VERSION ""
BS_:
BU_:

BO_ 823 EPBM_alertMatrix1: 8 ETH
 SG_ EPBM_f065_rightEncIntrpt: 0|1@1+ (1,0) [0|0] "" X
 SG_ EPBM_f066_rightIdleOc: 1|1@1+ (1,0) [0|0] "" X
 SG_ EPBM_f067_rightEncIrrational: 2|1@1+ (1,0) [0|0] "" X
 SG_ EPBM_f068_rightEncoderSna: 3|1@1+ (1,0) [0|0] "" X
 SG_ EPBM_f069_rightOc: 4|1@1+ (1,0) [0|0] "" X
 SG_ EPBM_f070_rightUc: 5|1@1+ (1,0) [0|0] "" X
 SG_ EPBM_f071_rightEndStop: 6|1@1+ (1,0) [0|0] "" X
 SG_ EPBM_f072_rightShortApply: 7|1@1+ (1,0) [0|0] "" X
 SG_ EPBM_f073_rightNShort: 8|1@1+ (1,0) [0|0] "" X
 SG_ EPBM_f074_rightPShort: 9|1@1+ (1,0) [0|0] "" X
 SG_ EPBM_f075_rightNOpen: 10|1@1+ (1,0) [0|0] "" X
 SG_ EPBM_f076_rightPOpen: 11|1@1+ (1,0) [0|0] "" X
 SG_ EPBM_f077_rightEnaStuckHigh: 12|1@1+ (1,0) [0|0] "" X
 SG_ EPBM_f078_rightEnaStuckLow: 13|1@1+ (1,0) [0|0] "" X
 SG_ EPBM_f079_rightDriveDuration: 14|1@1+ (1,0) [0|0] "" X
 SG_ EPBM_f080_rightPHalfBridge: 15|1@1+ (1,0) [0|0] "" X
 SG_ EPBM_f081_rightNHalfBridge: 16|1@1+ (1,0) [0|0] "" X
 SG_ EPBM_f082_rightNvOv: 17|1@1+ (1,0) [0|0] "" X
 SG_ EPBM_f083_rightNvUv: 18|1@1+ (1,0) [0|0] "" X
 SG_ EPBM_f084_rightPvOv: 19|1@1+ (1,0) [0|0] "" X
 SG_ EPBM_f085_rightPvUv: 20|1@1+ (1,0) [0|0] "" X
 SG_ EPBM_f086_rightSubstateErr: 21|1@1+ (1,0) [0|0] "" X
 SG_ EPBM_f087_rightOverApply: 22|1@1+ (1,0) [0|0] "" X
 SG_ EPBM_f088_rightUnderApply: 23|1@1+ (1,0) [0|0] "" X
 SG_ EPBM_f089_rightOverRelease: 24|1@1+ (1,0) [0|0] "" X
 SG_ EPBM_f090_rightUnderRelease: 25|1@1+ (1,0) [0|0] "" X
 SG_ EPBM_f091_spuriousEncIntR: 26|1@1+ (1,0) [0|0] "" X
 SG_ EPBM_f092_noCurrentCalR: 27|1@1+ (1,0) [0|0] "" X
 SG_ EPBM_f093_dasMIA: 28|1@1+ (1,0) [0|0] "" X
 SG_ EPBM_f094_unused: 29|1@1+ (1,0) [0|0] "" X
 SG_ EPBM_f095_invalidConfig: 30|1@1+ (1,0) [0|0] "" X
 SG_ EPBM_f096_selfParkAborted: 31|1@1+ (1,0) [0|0] "" X
 SG_ EPBM_f097_parkMia: 32|1@1+ (1,0) [0|0] "" X
 SG_ EPBM_f098_pmMia: 33|1@1+ (1,0) [0|0] "" X
 SG_ EPBM_f099_unused: 34|1@1+ (1,0) [0|0] "" X
 SG_ EPBM_f100_calibrationWarning: 35|1@1+ (1,0) [0|0] "" X
 SG_ EPBM_f101_calibrationFault: 36|1@1+ (1,0) [0|0] "" X
 SG_ EPBM_f102_targetNotReachedL: 37|1@1+ (1,0) [0|0] "" X
 SG_ EPBM_f103_targetNotReachedR: 38|1@1+ (1,0) [0|0] "" X
 SG_ EPBM_f104_epbStillAsleep: 39|1@1+ (1,0) [0|0] "" X
 SG_ EPBM_f105_epbWentToSleep: 40|1@1+ (1,0) [0|0] "" X
 SG_ EPBM_f106_voltageWarning: 41|1@1+ (1,0) [0|0] "" X
 SG_ EPBM_f107_currentWarning: 42|1@1+ (1,0) [0|0] "" X
 SG_ EPBM_f108_unused: 43|1@1+ (1,0) [0|0] "" X
 SG_ EPBM_f109_unused: 44|1@1+ (1,0) [0|0] "" X
 SG_ EPBM_f110_calWarningLeft: 45|1@1+ (1,0) [0|0] "" X
 SG_ EPBM_f111_calWarningRight: 46|1@1+ (1,0) [0|0] "" X
 SG_ EPBM_f112_calFaultLeft: 47|1@1+ (1,0) [0|0] "" X
 SG_ EPBM_f113_calFaultRight: 48|1@1+ (1,0) [0|0] "" X
 SG_ EPBM_f114_unused: 49|1@1+ (1,0) [0|0] "" X
 SG_ EPBM_f115_rightNVoltageLow: 50|1@1+ (1,0) [0|0] "" X
 SG_ EPBM_f116_rightPVoltageHigh: 51|1@1+ (1,0) [0|0] "" X
 SG_ EPBM_f117_usedFallbackValues: 52|1@1+ (1,0) [0|0] "" X
 SG_ EPBM_f118_unused: 53|1@1+ (1,0) [0|0] "" X
 SG_ EPBM_f119_unused: 54|1@1+ (1,0) [0|0] "" X
 SG_ EPBM_f120_unused: 55|1@1+ (1,0) [0|0] "" X
 SG_ EPBM_f121_unused: 56|1@1+ (1,0) [0|0] "" X
 SG_ EPBM_f122_unused: 57|1@1+ (1,0) [0|0] "" X
 SG_ EPBM_f123_unused: 58|1@1+ (1,0) [0|0] "" X
 SG_ EPBM_f124_unused: 59|1@1+ (1,0) [0|0] "" X
 SG_ EPBM_f125_unused: 60|1@1+ (1,0) [0|0] "" X
 SG_ EPBM_f126_unused: 61|1@1+ (1,0) [0|0] "" X
 SG_ EPBM_f127_unused: 62|1@1+ (1,0) [0|0] "" X
 SG_ EPBM_f128_unused: 63|1@1+ (1,0) [0|0] "" X

BO_ 791 EPBM_alertMatrix2: 8 ETH
 SG_ EPBM_w001_leftEncIntrpt: 0|1@1+ (1,0) [0|0] "" X
 SG_ EPBM_w002_leftIdleOc: 1|1@1+ (1,0) [0|0] "" X
 SG_ EPBM_w003_leftEncIrrational: 2|1@1+ (1,0) [0|0] "" X
 SG_ EPBM_w004_leftEncoderSna: 3|1@1+ (1,0) [0|0] "" X
 SG_ EPBM_w005_leftOc: 4|1@1+ (1,0) [0|0] "" X
 SG_ EPBM_w006_leftUc: 5|1@1+ (1,0) [0|0] "" X
 SG_ EPBM_w007_leftEndStop: 6|1@1+ (1,0) [0|0] "" X
 SG_ EPBM_w008_leftShortApply: 7|1@1+ (1,0) [0|0] "" X
 SG_ EPBM_w009_leftNShort: 8|1@1+ (1,0) [0|0] "" X
 SG_ EPBM_w010_leftPShort: 9|1@1+ (1,0) [0|0] "" X
 SG_ EPBM_w011_leftNOpen: 10|1@1+ (1,0) [0|0] "" X
 SG_ EPBM_w012_leftPOpen: 11|1@1+ (1,0) [0|0] "" X
 SG_ EPBM_w013_leftEnaStuckHigh: 12|1@1+ (1,0) [0|0] "" X
 SG_ EPBM_w014_leftEnaStuckLow: 13|1@1+ (1,0) [0|0] "" X
 SG_ EPBM_w015_leftDriveDuration: 14|1@1+ (1,0) [0|0] "" X
 SG_ EPBM_w016_leftPHalfBridge: 15|1@1+ (1,0) [0|0] "" X
 SG_ EPBM_w017_leftNHalfBridge: 16|1@1+ (1,0) [0|0] "" X
 SG_ EPBM_w018_leftNvOv: 17|1@1+ (1,0) [0|0] "" X
 SG_ EPBM_w019_leftNvUv: 18|1@1+ (1,0) [0|0] "" X
 SG_ EPBM_w020_leftPvOv: 19|1@1+ (1,0) [0|0] "" X
 SG_ EPBM_w021_leftPvUv: 20|1@1+ (1,0) [0|0] "" X
 SG_ EPBM_w022_leftSubstateErr: 21|1@1+ (1,0) [0|0] "" X
 SG_ EPBM_w023_leftOverApply: 22|1@1+ (1,0) [0|0] "" X
 SG_ EPBM_w024_leftUnderApply: 23|1@1+ (1,0) [0|0] "" X
 SG_ EPBM_w025_leftOverRelease: 24|1@1+ (1,0) [0|0] "" X
 SG_ EPBM_w026_leftUnderRelease: 25|1@1+ (1,0) [0|0] "" X
 SG_ EPBM_w027_spuriousEncIntL: 26|1@1+ (1,0) [0|0] "" X
 SG_ EPBM_w028_noCurrentCalL: 27|1@1+ (1,0) [0|0] "" X
 SG_ EPBM_w029_canDisabled: 28|1@1+ (1,0) [0|0] "" X
 SG_ EPBM_w030_interProcSpi: 29|1@1+ (1,0) [0|0] "" X
 SG_ EPBM_w031_stateErr: 30|1@1+ (1,0) [0|0] "" X
 SG_ EPBM_w032_reqStateErr: 31|1@1+ (1,0) [0|0] "" X
 SG_ EPBM_w033_canHardware: 32|1@1+ (1,0) [0|0] "" X
 SG_ EPBM_w034_canData: 33|1@1+ (1,0) [0|0] "" X
 SG_ EPBM_w035_canErr: 34|1@1+ (1,0) [0|0] "" X
 SG_ EPBM_w036_canOverrun: 35|1@1+ (1,0) [0|0] "" X
 SG_ EPBM_w037_firmware: 36|1@1+ (1,0) [0|0] "" X
 SG_ EPBM_w038_eeprom: 37|1@1+ (1,0) [0|0] "" X
 SG_ EPBM_w039_watchdogReset: 38|1@1+ (1,0) [0|0] "" X
 SG_ EPBM_w040_memoryError: 39|1@1+ (1,0) [0|0] "" X
 SG_ EPBM_w041_spiOpen: 40|1@1+ (1,0) [0|0] "" X
 SG_ EPBM_w042_spiRead: 41|1@1+ (1,0) [0|0] "" X
 SG_ EPBM_w043_absMIA: 42|1@1+ (1,0) [0|0] "" X
 SG_ EPBM_w044_diMIA: 43|1@1+ (1,0) [0|0] "" X
 SG_ EPBM_w045_gtwMIA: 44|1@1+ (1,0) [0|0] "" X
 SG_ EPBM_w046_sccmMIA: 45|1@1+ (1,0) [0|0] "" X
 SG_ EPBM_w047_epbMIA: 46|1@1+ (1,0) [0|0] "" X
 SG_ EPBM_w048_chgMIA: 47|1@1+ (1,0) [0|0] "" X
 SG_ EPBM_w049_espMIA: 48|1@1+ (1,0) [0|0] "" X
 SG_ EPBM_w050_mcuMIA: 49|1@1+ (1,0) [0|0] "" X
 SG_ EPBM_w051_leftNVoltageLow: 50|1@1+ (1,0) [0|0] "" X
 SG_ EPBM_w052_leftPVoltageHigh: 51|1@1+ (1,0) [0|0] "" X
 SG_ EPBM_w053_unused: 52|1@1+ (1,0) [0|0] "" X
 SG_ EPBM_w054_unused: 53|1@1+ (1,0) [0|0] "" X
 SG_ EPBM_w055_stackOverflow: 54|1@1+ (1,0) [0|0] "" X
 SG_ EPBM_w056_12vOv: 55|1@1+ (1,0) [0|0] "" X
 SG_ EPBM_w057_12vUv: 56|1@1+ (1,0) [0|0] "" X
 SG_ EPBM_w058_5vLost: 57|1@1+ (1,0) [0|0] "" X
 SG_ EPBM_w059_battMismatch: 58|1@1+ (1,0) [0|0] "" X
 SG_ EPBM_w060_maxCycles1: 59|1@1+ (1,0) [0|0] "" X
 SG_ EPBM_w061_maxCycles2: 60|1@1+ (1,0) [0|0] "" X
 SG_ EPBM_w062_diGearInvld: 61|1@1+ (1,0) [0|0] "" X
 SG_ EPBM_w063_unused: 62|1@1+ (1,0) [0|0] "" X
 SG_ EPBM_w064_unused: 63|1@1+ (1,0) [0|0] "" X

BO_ 807 EPBM_alertMatrix3: 8 ETH
 SG_ EPBM_w065_rightEncIntrpt: 0|1@1+ (1,0) [0|0] "" X
 SG_ EPBM_w066_rightIdleOc: 1|1@1+ (1,0) [0|0] "" X
 SG_ EPBM_w067_rightEncIrrational: 2|1@1+ (1,0) [0|0] "" X
 SG_ EPBM_w068_rightEncoderSna: 3|1@1+ (1,0) [0|0] "" X
 SG_ EPBM_w069_rightOc: 4|1@1+ (1,0) [0|0] "" X
 SG_ EPBM_w070_rightUc: 5|1@1+ (1,0) [0|0] "" X
 SG_ EPBM_w071_rightEndStop: 6|1@1+ (1,0) [0|0] "" X
 SG_ EPBM_w072_rightShortApply: 7|1@1+ (1,0) [0|0] "" X
 SG_ EPBM_w073_rightNShort: 8|1@1+ (1,0) [0|0] "" X
 SG_ EPBM_w074_rightPShort: 9|1@1+ (1,0) [0|0] "" X
 SG_ EPBM_w075_rightNOpen: 10|1@1+ (1,0) [0|0] "" X
 SG_ EPBM_w076_rightPOpen: 11|1@1+ (1,0) [0|0] "" X
 SG_ EPBM_w077_rightEnaStuckHigh: 12|1@1+ (1,0) [0|0] "" X
 SG_ EPBM_w078_rightEnaStuckLow: 13|1@1+ (1,0) [0|0] "" X
 SG_ EPBM_w079_rightDriveDuration: 14|1@1+ (1,0) [0|0] "" X
 SG_ EPBM_w080_rightPHalfBridge: 15|1@1+ (1,0) [0|0] "" X
 SG_ EPBM_w081_rightNHalfBridge: 16|1@1+ (1,0) [0|0] "" X
 SG_ EPBM_w082_rightNvOv: 17|1@1+ (1,0) [0|0] "" X
 SG_ EPBM_w083_rightNvUv: 18|1@1+ (1,0) [0|0] "" X
 SG_ EPBM_w084_rightPvOv: 19|1@1+ (1,0) [0|0] "" X
 SG_ EPBM_w085_rightPvUv: 20|1@1+ (1,0) [0|0] "" X
 SG_ EPBM_w086_rightSubstateErr: 21|1@1+ (1,0) [0|0] "" X
 SG_ EPBM_w087_rightOverApply: 22|1@1+ (1,0) [0|0] "" X
 SG_ EPBM_w088_rightUnderApply: 23|1@1+ (1,0) [0|0] "" X
 SG_ EPBM_w089_rightOverRelease: 24|1@1+ (1,0) [0|0] "" X
 SG_ EPBM_w090_rightUnderRelease: 25|1@1+ (1,0) [0|0] "" X
 SG_ EPBM_w091_spuriousEncIntR: 26|1@1+ (1,0) [0|0] "" X
 SG_ EPBM_w092_noCurrentCalR: 27|1@1+ (1,0) [0|0] "" X
 SG_ EPBM_w093_dasMIA: 28|1@1+ (1,0) [0|0] "" X
 SG_ EPBM_w094_unused: 29|1@1+ (1,0) [0|0] "" X
 SG_ EPBM_w095_invalidConfig: 30|1@1+ (1,0) [0|0] "" X
 SG_ EPBM_w096_selfParkAborted: 31|1@1+ (1,0) [0|0] "" X
 SG_ EPBM_w097_parkMia: 32|1@1+ (1,0) [0|0] "" X
 SG_ EPBM_w098_pmMia: 33|1@1+ (1,0) [0|0] "" X
 SG_ EPBM_w099_unused: 34|1@1+ (1,0) [0|0] "" X
 SG_ EPBM_w100_calibrationWarning: 35|1@1+ (1,0) [0|0] "" X
 SG_ EPBM_w101_calibrationFault: 36|1@1+ (1,0) [0|0] "" X
 SG_ EPBM_w102_targetNotReachedL: 37|1@1+ (1,0) [0|0] "" X
 SG_ EPBM_w103_targetNotReachedR: 38|1@1+ (1,0) [0|0] "" X
 SG_ EPBM_w104_epbStillAsleep: 39|1@1+ (1,0) [0|0] "" X
 SG_ EPBM_w105_epbWentToSleep: 40|1@1+ (1,0) [0|0] "" X
 SG_ EPBM_w106_voltageWarning: 41|1@1+ (1,0) [0|0] "" X
 SG_ EPBM_w107_currentWarning: 42|1@1+ (1,0) [0|0] "" X
 SG_ EPBM_w108_unused: 43|1@1+ (1,0) [0|0] "" X
 SG_ EPBM_w109_unused: 44|1@1+ (1,0) [0|0] "" X
 SG_ EPBM_w110_calWarningLeft: 45|1@1+ (1,0) [0|0] "" X
 SG_ EPBM_w111_calWarningRight: 46|1@1+ (1,0) [0|0] "" X
 SG_ EPBM_w112_calFaultLeft: 47|1@1+ (1,0) [0|0] "" X
 SG_ EPBM_w113_calFaultRight: 48|1@1+ (1,0) [0|0] "" X
 SG_ EPBM_w114_unused: 49|1@1+ (1,0) [0|0] "" X
 SG_ EPBM_w115_rightNVoltageLow: 50|1@1+ (1,0) [0|0] "" X
 SG_ EPBM_w116_rightPVoltageHigh: 51|1@1+ (1,0) [0|0] "" X
 SG_ EPBM_w117_usedFallbackValues: 52|1@1+ (1,0) [0|0] "" X
 SG_ EPBM_w118_unused: 53|1@1+ (1,0) [0|0] "" X
 SG_ EPBM_w119_unused: 54|1@1+ (1,0) [0|0] "" X
 SG_ EPBM_w120_unused: 55|1@1+ (1,0) [0|0] "" X
 SG_ EPBM_w121_unused: 56|1@1+ (1,0) [0|0] "" X
 SG_ EPBM_w122_unused: 57|1@1+ (1,0) [0|0] "" X
 SG_ EPBM_w123_unused: 58|1@1+ (1,0) [0|0] "" X
 SG_ EPBM_w124_unused: 59|1@1+ (1,0) [0|0] "" X
 SG_ EPBM_w125_unused: 60|1@1+ (1,0) [0|0] "" X
 SG_ EPBM_w126_unused: 61|1@1+ (1,0) [0|0] "" X
 SG_ EPBM_w127_unused: 62|1@1+ (1,0) [0|0] "" X
 SG_ EPBM_w128_unused: 63|1@1+ (1,0) [0|0] "" X

BO_ 1351 EPBM_info: 8 ETH
 SG_ EPBM_infoIndex M: 0|8@1+ (1,0) [0|0] "" X
 SG_ EPBM_infoBuildType m10: 8|8@1+ (1,0) [0|0] "" X
 SG_ EPBM_infoBuildConfigID m10: 16|16@1+ (1,0) [0|0] "" X
 SG_ EPBM_infoHardwareID m10: 32|16@1+ (1,0) [0|0] "" X
 SG_ EPBM_infoComponentID m10: 48|16@1+ (1,0) [0|0] "" X
 SG_ EPBM_infoPcbaID m11: 16|8@1+ (1,0) [0|0] "" X
 SG_ EPBM_infoAssemblyID m11: 24|8@1+ (1,0) [0|0] "" X
 SG_ EPBM_infoUsageID m11: 32|16@1+ (1,0) [0|0] "" X
 SG_ EPBM_infoSubUsageID m11: 48|16@1+ (1,0) [0|0] "" X
 SG_ EPBM_infoApplicationCRC m13: 32|32@1+ (1,0) [0|0] "" X
 SG_ EPBM_infoBootloaderSvnRevision m14: 8|24@1+ (1,0) [0|0] "" X
 SG_ EPBM_infoAppGitHashBytes m17: 10|54@1+ (4,0) [0|0] "" X
 SG_ EPBM_infoBootGitHashBytes m18: 10|54@1+ (4,0) [0|0] "" X
 SG_ EPBM_infoPlatformType m19: 8|8@1+ (1,0) [0|0] "" X
 SG_ EPBM_infoMajorVersion m19: 16|8@1+ (1,0) [0|0] "" X
 SG_ EPBM_infoBranchOrigin m19: 24|8@1+ (1,0) [0|0] "" X
 SG_ EPBM_infoMaturity m19: 32|8@1+ (1,0) [0|0] "" X
 SG_ EPBM_infoHardwareRevision m19: 40|8@1+ (1,0) [0|0] "" X
 SG_ EPBM_infoBootUdsProtoVersion m20: 8|8@1+ (1,0) [0|0] "" X
 SG_ EPBM_infoBootloaderCRC m20: 32|32@1+ (1,0) [0|0] "" X

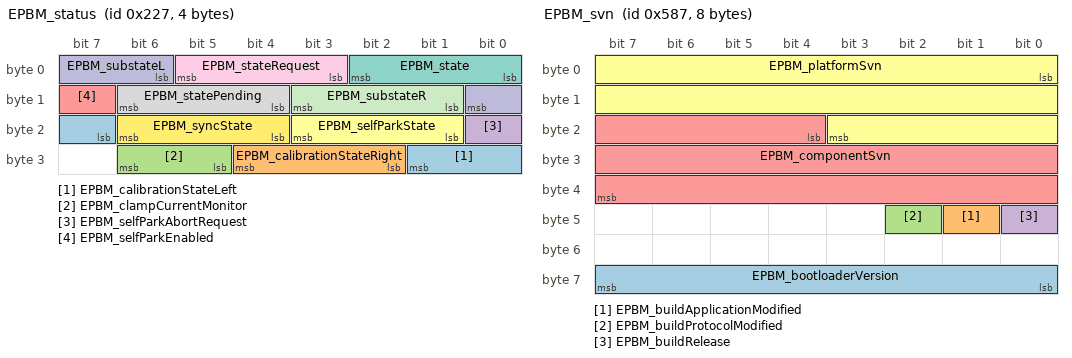
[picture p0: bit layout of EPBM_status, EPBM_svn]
BO_ 551 EPBM_status: 4 ETH
 SG_ EPBM_calibrationStateLeft: 23|3@1+ (1,0) [0|0] "" X
 SG_ EPBM_calibrationStateRight: 26|3@1+ (1,0) [0|0] "" X
 SG_ EPBM_clampCurrentMonitor: 29|2@1+ (1,0) [0|0] "" X
 SG_ EPBM_selfParkAbortRequest: 16|1@1+ (1,0) [0|0] "" X
 SG_ EPBM_selfParkEnabled: 15|1@1+ (1,0) [0|0] "" X
 SG_ EPBM_selfParkState: 17|3@1+ (1,0) [0|0] "" X
 SG_ EPBM_state: 0|3@1+ (1,0) [0|0] "" X
 SG_ EPBM_statePending: 12|3@1+ (1,0) [0|0] "" X
 SG_ EPBM_stateRequest: 3|3@1+ (1,0) [0|0] "" X
 SG_ EPBM_substateL: 6|3@1+ (1,0) [0|0] "" X
 SG_ EPBM_substateR: 9|3@1+ (1,0) [0|0] "" X
 SG_ EPBM_syncState: 20|3@1+ (1,0) [0|0] "" X

BO_ 1415 EPBM_svn: 8 ETH
 SG_ EPBM_bootloaderVersion: 56|8@1+ (1,0) [0|0] "" X
 SG_ EPBM_buildApplicationModified: 41|1@1+ (1,0) [0|0] "" X
 SG_ EPBM_buildProtocolModified: 42|1@1+ (1,0) [0|0] "" X
 SG_ EPBM_buildRelease: 40|1@1+ (1,0) [0|0] "" X
 SG_ EPBM_componentSvn: 20|20@1+ (1,0) [0|0] "" X
 SG_ EPBM_platformSvn: 0|20@1+ (1,0) [0|0] "" X

BO_ 1623 EPBM_udsResponse: 8 ETH
 SG_ EPBM_udsResponseData_H: 0|32@0+ (1,0) [0|0] "" X
 SG_ EPBM_udsResponseData_L: 32|32@0+ (1,0) [0|0] "" X

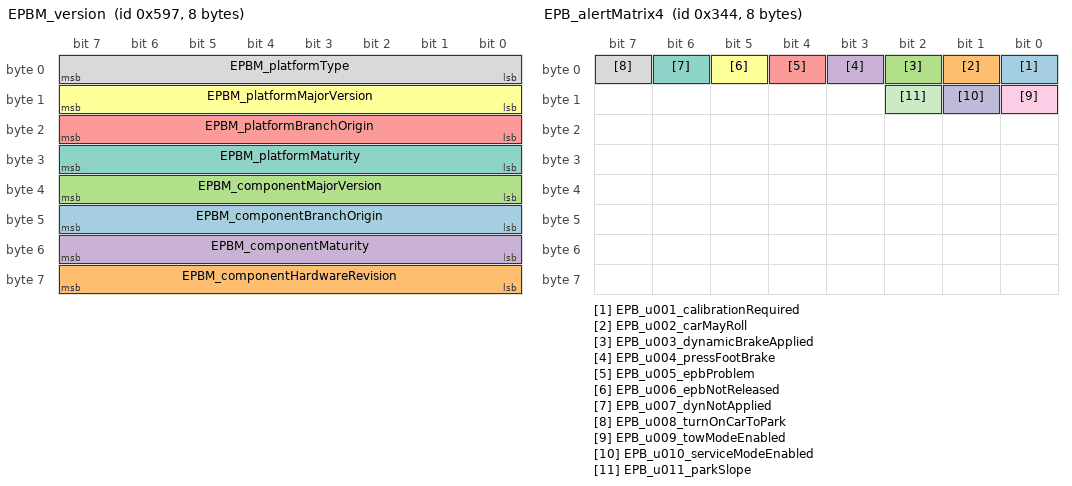
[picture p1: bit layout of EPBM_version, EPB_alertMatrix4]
BO_ 1431 EPBM_version: 8 ETH
 SG_ EPBM_componentBranchOrigin: 40|8@1+ (1,0) [0|0] "" X
 SG_ EPBM_componentHardwareRevision: 56|8@1+ (1,0) [0|0] "" X
 SG_ EPBM_componentMajorVersion: 32|8@1+ (1,0) [0|0] "" X
 SG_ EPBM_componentMaturity: 48|8@1+ (1,0) [0|0] "" X
 SG_ EPBM_platformBranchOrigin: 16|8@1+ (1,0) [0|0] "" X
 SG_ EPBM_platformMajorVersion: 8|8@1+ (1,0) [0|0] "" X
 SG_ EPBM_platformMaturity: 24|8@1+ (1,0) [0|0] "" X
 SG_ EPBM_platformType: 0|8@1+ (1,0) [0|0] "" X

BO_ 772 EPB_alertMatrix0: 8 ETH
 SG_ EPB_f001_leftEncIntrpt: 0|1@1+ (1,0) [0|0] "" X
 SG_ EPB_f002_leftIdleOc: 1|1@1+ (1,0) [0|0] "" X
 SG_ EPB_f003_leftEncIrrational: 2|1@1+ (1,0) [0|0] "" X
 SG_ EPB_f004_leftEncoderSna: 3|1@1+ (1,0) [0|0] "" X
 SG_ EPB_f005_leftOc: 4|1@1+ (1,0) [0|0] "" X
 SG_ EPB_f006_leftUc: 5|1@1+ (1,0) [0|0] "" X
 SG_ EPB_f007_leftEndStop: 6|1@1+ (1,0) [0|0] "" X
 SG_ EPB_f008_leftShortApply: 7|1@1+ (1,0) [0|0] "" X
 SG_ EPB_f009_leftNShort: 8|1@1+ (1,0) [0|0] "" X
 SG_ EPB_f010_leftPShort: 9|1@1+ (1,0) [0|0] "" X
 SG_ EPB_f011_leftNOpen: 10|1@1+ (1,0) [0|0] "" X
 SG_ EPB_f012_leftPOpen: 11|1@1+ (1,0) [0|0] "" X
 SG_ EPB_f013_leftEnaStuckHigh: 12|1@1+ (1,0) [0|0] "" X
 SG_ EPB_f014_leftEnaStuckLow: 13|1@1+ (1,0) [0|0] "" X
 SG_ EPB_f015_leftDriveDuration: 14|1@1+ (1,0) [0|0] "" X
 SG_ EPB_f016_leftPHalfBridge: 15|1@1+ (1,0) [0|0] "" X
 SG_ EPB_f017_leftNHalfBridge: 16|1@1+ (1,0) [0|0] "" X
 SG_ EPB_f018_leftNvOv: 17|1@1+ (1,0) [0|0] "" X
 SG_ EPB_f019_leftNvUv: 18|1@1+ (1,0) [0|0] "" X
 SG_ EPB_f020_leftPvOv: 19|1@1+ (1,0) [0|0] "" X
 SG_ EPB_f021_leftPvUv: 20|1@1+ (1,0) [0|0] "" X
 SG_ EPB_f022_leftSubstateErr: 21|1@1+ (1,0) [0|0] "" X
 SG_ EPB_f023_leftFirstShortApply: 22|1@1+ (1,0) [0|0] "" X
 SG_ EPB_f024_motorShortedReleaseL: 23|1@1+ (1,0) [0|0] "" X
 SG_ EPB_f025_motorShortedApplyL: 24|1@1+ (1,0) [0|0] "" X
 SG_ EPB_f026_noCurrentCalL: 25|1@1+ (1,0) [0|0] "" X
 SG_ EPB_f027_spuriousEncIntL: 26|1@1+ (1,0) [0|0] "" X
 SG_ EPB_f028_reqStateErr: 27|1@1+ (1,0) [0|0] "" X
 SG_ EPB_f029_stateErr: 28|1@1+ (1,0) [0|0] "" X
 SG_ EPB_f030_interProcSpi: 29|1@1+ (1,0) [0|0] "" X
 SG_ EPB_f031_chgMIA: 30|1@1+ (1,0) [0|0] "" X
 SG_ EPB_f032_canDisabled: 31|1@1+ (1,0) [0|0] "" X
 SG_ EPB_f033_canHardware: 32|1@1+ (1,0) [0|0] "" X
 SG_ EPB_f034_canData: 33|1@1+ (1,0) [0|0] "" X
 SG_ EPB_f035_canErr: 34|1@1+ (1,0) [0|0] "" X
 SG_ EPB_f036_canOverrun: 35|1@1+ (1,0) [0|0] "" X
 SG_ EPB_f037_firmware: 36|1@1+ (1,0) [0|0] "" X
 SG_ EPB_f038_eeprom: 37|1@1+ (1,0) [0|0] "" X
 SG_ EPB_f039_watchdogReset: 38|1@1+ (1,0) [0|0] "" X
 SG_ EPB_f040_memoryError: 39|1@1+ (1,0) [0|0] "" X
 SG_ EPB_f041_spiOpen: 40|1@1+ (1,0) [0|0] "" X
 SG_ EPB_f042_spiRead: 41|1@1+ (1,0) [0|0] "" X
 SG_ EPB_f043_absMIA: 42|1@1+ (1,0) [0|0] "" X
 SG_ EPB_f044_diMIA: 43|1@1+ (1,0) [0|0] "" X
 SG_ EPB_f045_gtwMIA: 44|1@1+ (1,0) [0|0] "" X
 SG_ EPB_f046_sccmMIA: 45|1@1+ (1,0) [0|0] "" X
 SG_ EPB_f047_epbmMIA: 46|1@1+ (1,0) [0|0] "" X
 SG_ EPB_f048_mcuMIA: 47|1@1+ (1,0) [0|0] "" X
 SG_ EPB_f049_espMIA: 48|1@1+ (1,0) [0|0] "" X
 SG_ EPB_f050_resetRequired: 49|1@1+ (1,0) [0|0] "" X
 SG_ EPB_f051_epbNotApplied: 50|1@1+ (1,0) [0|0] "" X
 SG_ EPB_f052_epbProblem: 51|1@1+ (1,0) [0|0] "" X
 SG_ EPB_f053_epbNotReleased: 52|1@1+ (1,0) [0|0] "" X
 SG_ EPB_f054_severeShortApply: 53|1@1+ (1,0) [0|0] "" X
 SG_ EPB_f055_stackOverflow: 54|1@1+ (1,0) [0|0] "" X
 SG_ EPB_f056_12vOv: 55|1@1+ (1,0) [0|0] "" X
 SG_ EPB_f057_12vUv: 56|1@1+ (1,0) [0|0] "" X
 SG_ EPB_f058_5vLost: 57|1@1+ (1,0) [0|0] "" X
 SG_ EPB_f059_battMismatch: 58|1@1+ (1,0) [0|0] "" X
 SG_ EPB_f060_maxCycles1: 59|1@1+ (1,0) [0|0] "" X
 SG_ EPB_f061_maxCycles2: 60|1@1+ (1,0) [0|0] "" X
 SG_ EPB_f062_diGearInvld: 61|1@1+ (1,0) [0|0] "" X
 SG_ EPB_f063_parkWhlSpeed: 62|1@1+ (1,0) [0|0] "" X
 SG_ EPB_f064_EPBMTimeout: 63|1@1+ (1,0) [0|0] "" X

BO_ 820 EPB_alertMatrix1: 8 ETH
 SG_ EPB_f065_rightEncIntrpt: 0|1@1+ (1,0) [0|0] "" X
 SG_ EPB_f066_rightIdleOc: 1|1@1+ (1,0) [0|0] "" X
 SG_ EPB_f067_rightEncIrrational: 2|1@1+ (1,0) [0|0] "" X
 SG_ EPB_f068_rightEncoderSna: 3|1@1+ (1,0) [0|0] "" X
 SG_ EPB_f069_rightOc: 4|1@1+ (1,0) [0|0] "" X
 SG_ EPB_f070_rightUc: 5|1@1+ (1,0) [0|0] "" X
 SG_ EPB_f071_rightEndStop: 6|1@1+ (1,0) [0|0] "" X
 SG_ EPB_f072_rightShortApply: 7|1@1+ (1,0) [0|0] "" X
 SG_ EPB_f073_rightNShort: 8|1@1+ (1,0) [0|0] "" X
 SG_ EPB_f074_rightPShort: 9|1@1+ (1,0) [0|0] "" X
 SG_ EPB_f075_rightNOpen: 10|1@1+ (1,0) [0|0] "" X
 SG_ EPB_f076_rightPOpen: 11|1@1+ (1,0) [0|0] "" X
 SG_ EPB_f077_rightEnaStuckHigh: 12|1@1+ (1,0) [0|0] "" X
 SG_ EPB_f078_rightEnaStuckLow: 13|1@1+ (1,0) [0|0] "" X
 SG_ EPB_f079_rightDriveDuration: 14|1@1+ (1,0) [0|0] "" X
 SG_ EPB_f080_rightPHalfBridge: 15|1@1+ (1,0) [0|0] "" X
 SG_ EPB_f081_rightNHalfBridge: 16|1@1+ (1,0) [0|0] "" X
 SG_ EPB_f082_rightNvOv: 17|1@1+ (1,0) [0|0] "" X
 SG_ EPB_f083_rightNvUv: 18|1@1+ (1,0) [0|0] "" X
 SG_ EPB_f084_rightPvOv: 19|1@1+ (1,0) [0|0] "" X
 SG_ EPB_f085_rightPvUv: 20|1@1+ (1,0) [0|0] "" X
 SG_ EPB_f086_rightSubstateErr: 21|1@1+ (1,0) [0|0] "" X
 SG_ EPB_f087_rightFirstShortApply: 22|1@1+ (1,0) [0|0] "" X
 SG_ EPB_f088_motorShortedReleaseR: 23|1@1+ (1,0) [0|0] "" X
 SG_ EPB_f089_motorShortedApplyR: 24|1@1+ (1,0) [0|0] "" X
 SG_ EPB_f090_noCurrentCalR: 25|1@1+ (1,0) [0|0] "" X
 SG_ EPB_f091_spuriousEncIntR: 26|1@1+ (1,0) [0|0] "" X
 SG_ EPB_f092_obsolete: 27|1@1+ (1,0) [0|0] "" X
 SG_ EPB_f093_dasMIA: 28|1@1+ (1,0) [0|0] "" X
 SG_ EPB_f094_inhibitEac: 29|1@1+ (1,0) [0|0] "" X
 SG_ EPB_f095_invalidConfig: 30|1@1+ (1,0) [0|0] "" X
 SG_ EPB_f096_epasMia: 31|1@1+ (1,0) [0|0] "" X
 SG_ EPB_f097_selfParkAborted: 32|1@1+ (1,0) [0|0] "" X
 SG_ EPB_f098_parkMia: 33|1@1+ (1,0) [0|0] "" X
 SG_ EPB_f099_pmMia: 34|1@1+ (1,0) [0|0] "" X
 SG_ EPB_f100_calibrationWarning: 35|1@1+ (1,0) [0|0] "" X
 SG_ EPB_f101_calibrationFault: 36|1@1+ (1,0) [0|0] "" X
 SG_ EPB_f102_eepromCorrupt: 37|1@1+ (1,0) [0|0] "" X
 SG_ EPB_f103_eepromUpdated: 38|1@1+ (1,0) [0|0] "" X
 SG_ EPB_f104_epbmStillAsleep: 39|1@1+ (1,0) [0|0] "" X
 SG_ EPB_f105_epbmWentToSleep: 40|1@1+ (1,0) [0|0] "" X
 SG_ EPB_f106_leftNVoltageLow: 41|1@1+ (1,0) [0|0] "" X
 SG_ EPB_f107_leftPVoltageHigh: 42|1@1+ (1,0) [0|0] "" X
 SG_ EPB_f108_rightNVoltageLow: 43|1@1+ (1,0) [0|0] "" X
 SG_ EPB_f109_rightPVoltageHigh: 44|1@1+ (1,0) [0|0] "" X
 SG_ EPB_f110_calWarningLeft: 45|1@1+ (1,0) [0|0] "" X
 SG_ EPB_f111_calWarningRight: 46|1@1+ (1,0) [0|0] "" X
 SG_ EPB_f112_calFaultLeft: 47|1@1+ (1,0) [0|0] "" X
 SG_ EPB_f113_calFaultRight: 48|1@1+ (1,0) [0|0] "" X
 SG_ EPB_f114_voltageWarning: 49|1@1+ (1,0) [0|0] "" X
 SG_ EPB_f115_currentWarning: 50|1@1+ (1,0) [0|0] "" X
 SG_ EPB_f116_unableToCalcGrade: 51|1@1+ (1,0) [0|0] "" X
 SG_ EPB_f117_usedFallbackValues: 52|1@1+ (1,0) [0|0] "" X
 SG_ EPB_f118_unused: 53|1@1+ (1,0) [0|0] "" X
 SG_ EPB_f119_unused: 54|1@1+ (1,0) [0|0] "" X
 SG_ EPB_f120_releaseLogL: 55|1@1+ (1,0) [0|0] "" X
 SG_ EPB_f121_releaseLogR: 56|1@1+ (1,0) [0|0] "" X
 SG_ EPB_f122_unused: 57|1@1+ (1,0) [0|0] "" X
 SG_ EPB_f123_releaseDistanceL: 58|1@1+ (1,0) [0|0] "" X
 SG_ EPB_f124_releaseDistanceR: 59|1@1+ (1,0) [0|0] "" X
 SG_ EPB_f125_gradeTooSteep: 60|1@1+ (1,0) [0|0] "" X
 SG_ EPB_f126_unused: 61|1@1+ (1,0) [0|0] "" X
 SG_ EPB_f127_unused: 62|1@1+ (1,0) [0|0] "" X
 SG_ EPB_f128_unused: 63|1@1+ (1,0) [0|0] "" X

BO_ 788 EPB_alertMatrix2: 8 ETH
 SG_ EPB_w001_leftEncIntrpt: 0|1@1+ (1,0) [0|0] "" X
 SG_ EPB_w002_leftIdleOc: 1|1@1+ (1,0) [0|0] "" X
 SG_ EPB_w003_leftEncIrrational: 2|1@1+ (1,0) [0|0] "" X
 SG_ EPB_w004_leftEncoderSna: 3|1@1+ (1,0) [0|0] "" X
 SG_ EPB_w005_leftOc: 4|1@1+ (1,0) [0|0] "" X
 SG_ EPB_w006_leftUc: 5|1@1+ (1,0) [0|0] "" X
 SG_ EPB_w007_leftEndStop: 6|1@1+ (1,0) [0|0] "" X
 SG_ EPB_w008_leftShortApply: 7|1@1+ (1,0) [0|0] "" X
 SG_ EPB_w009_leftNShort: 8|1@1+ (1,0) [0|0] "" X
 SG_ EPB_w010_leftPShort: 9|1@1+ (1,0) [0|0] "" X
 SG_ EPB_w011_leftNOpen: 10|1@1+ (1,0) [0|0] "" X
 SG_ EPB_w012_leftPOpen: 11|1@1+ (1,0) [0|0] "" X
 SG_ EPB_w013_leftEnaStuckHigh: 12|1@1+ (1,0) [0|0] "" X
 SG_ EPB_w014_leftEnaStuckLow: 13|1@1+ (1,0) [0|0] "" X
 SG_ EPB_w015_leftDriveDuration: 14|1@1+ (1,0) [0|0] "" X
 SG_ EPB_w016_leftPHalfBridge: 15|1@1+ (1,0) [0|0] "" X
 SG_ EPB_w017_leftNHalfBridge: 16|1@1+ (1,0) [0|0] "" X
 SG_ EPB_w018_leftNvOv: 17|1@1+ (1,0) [0|0] "" X
 SG_ EPB_w019_leftNvUv: 18|1@1+ (1,0) [0|0] "" X
 SG_ EPB_w020_leftPvOv: 19|1@1+ (1,0) [0|0] "" X
 SG_ EPB_w021_leftPvUv: 20|1@1+ (1,0) [0|0] "" X
 SG_ EPB_w022_leftSubstateErr: 21|1@1+ (1,0) [0|0] "" X
 SG_ EPB_w023_leftFirstShortApply: 22|1@1+ (1,0) [0|0] "" X
 SG_ EPB_w024_motorShortedReleaseL: 23|1@1+ (1,0) [0|0] "" X
 SG_ EPB_w025_motorShortedApplyL: 24|1@1+ (1,0) [0|0] "" X
 SG_ EPB_w026_noCurrentCalL: 25|1@1+ (1,0) [0|0] "" X
 SG_ EPB_w027_spuriousEncIntL: 26|1@1+ (1,0) [0|0] "" X
 SG_ EPB_w028_reqStateErr: 27|1@1+ (1,0) [0|0] "" X
 SG_ EPB_w029_stateErr: 28|1@1+ (1,0) [0|0] "" X
 SG_ EPB_w030_interProcSpi: 29|1@1+ (1,0) [0|0] "" X
 SG_ EPB_w031_chgMIA: 30|1@1+ (1,0) [0|0] "" X
 SG_ EPB_w032_canDisabled: 31|1@1+ (1,0) [0|0] "" X
 SG_ EPB_w033_canHardware: 32|1@1+ (1,0) [0|0] "" X
 SG_ EPB_w034_canData: 33|1@1+ (1,0) [0|0] "" X
 SG_ EPB_w035_canErr: 34|1@1+ (1,0) [0|0] "" X
 SG_ EPB_w036_canOverrun: 35|1@1+ (1,0) [0|0] "" X
 SG_ EPB_w037_firmware: 36|1@1+ (1,0) [0|0] "" X
 SG_ EPB_w038_eeprom: 37|1@1+ (1,0) [0|0] "" X
 SG_ EPB_w039_watchdogReset: 38|1@1+ (1,0) [0|0] "" X
 SG_ EPB_w040_memoryError: 39|1@1+ (1,0) [0|0] "" X
 SG_ EPB_w041_spiOpen: 40|1@1+ (1,0) [0|0] "" X
 SG_ EPB_w042_spiRead: 41|1@1+ (1,0) [0|0] "" X
 SG_ EPB_w043_absMIA: 42|1@1+ (1,0) [0|0] "" X
 SG_ EPB_w044_diMIA: 43|1@1+ (1,0) [0|0] "" X
 SG_ EPB_w045_gtwMIA: 44|1@1+ (1,0) [0|0] "" X
 SG_ EPB_w046_sccmMIA: 45|1@1+ (1,0) [0|0] "" X
 SG_ EPB_w047_epbmMIA: 46|1@1+ (1,0) [0|0] "" X
 SG_ EPB_w048_mcuMIA: 47|1@1+ (1,0) [0|0] "" X
 SG_ EPB_w049_espMIA: 48|1@1+ (1,0) [0|0] "" X
 SG_ EPB_w050_resetRequired: 49|1@1+ (1,0) [0|0] "" X
 SG_ EPB_w051_epbNotApplied: 50|1@1+ (1,0) [0|0] "" X
 SG_ EPB_w052_epbProblem: 51|1@1+ (1,0) [0|0] "" X
 SG_ EPB_w053_epbNotReleased: 52|1@1+ (1,0) [0|0] "" X
 SG_ EPB_w054_severeShortApply: 53|1@1+ (1,0) [0|0] "" X
 SG_ EPB_w055_stackOverflow: 54|1@1+ (1,0) [0|0] "" X
 SG_ EPB_w056_12vOv: 55|1@1+ (1,0) [0|0] "" X
 SG_ EPB_w057_12vUv: 56|1@1+ (1,0) [0|0] "" X
 SG_ EPB_w058_5vLost: 57|1@1+ (1,0) [0|0] "" X
 SG_ EPB_w059_battMismatch: 58|1@1+ (1,0) [0|0] "" X
 SG_ EPB_w060_maxCycles1: 59|1@1+ (1,0) [0|0] "" X
 SG_ EPB_w061_maxCycles2: 60|1@1+ (1,0) [0|0] "" X
 SG_ EPB_w062_diGearInvld: 61|1@1+ (1,0) [0|0] "" X
 SG_ EPB_w063_parkWhlSpeed: 62|1@1+ (1,0) [0|0] "" X
 SG_ EPB_w064_EPBMTimeout: 63|1@1+ (1,0) [0|0] "" X

BO_ 804 EPB_alertMatrix3: 8 ETH
 SG_ EPB_w065_rightEncIntrpt: 0|1@1+ (1,0) [0|0] "" X
 SG_ EPB_w066_rightIdleOc: 1|1@1+ (1,0) [0|0] "" X
 SG_ EPB_w067_rightEncIrrational: 2|1@1+ (1,0) [0|0] "" X
 SG_ EPB_w068_rightEncoderSna: 3|1@1+ (1,0) [0|0] "" X
 SG_ EPB_w069_rightOc: 4|1@1+ (1,0) [0|0] "" X
 SG_ EPB_w070_rightUc: 5|1@1+ (1,0) [0|0] "" X
 SG_ EPB_w071_rightEndStop: 6|1@1+ (1,0) [0|0] "" X
 SG_ EPB_w072_rightShortApply: 7|1@1+ (1,0) [0|0] "" X
 SG_ EPB_w073_rightNShort: 8|1@1+ (1,0) [0|0] "" X
 SG_ EPB_w074_rightPShort: 9|1@1+ (1,0) [0|0] "" X
 SG_ EPB_w075_rightNOpen: 10|1@1+ (1,0) [0|0] "" X
 SG_ EPB_w076_rightPOpen: 11|1@1+ (1,0) [0|0] "" X
 SG_ EPB_w077_rightEnaStuckHigh: 12|1@1+ (1,0) [0|0] "" X
 SG_ EPB_w078_rightEnaStuckLow: 13|1@1+ (1,0) [0|0] "" X
 SG_ EPB_w079_rightDriveDuration: 14|1@1+ (1,0) [0|0] "" X
 SG_ EPB_w080_rightPHalfBridge: 15|1@1+ (1,0) [0|0] "" X
 SG_ EPB_w081_rightNHalfBridge: 16|1@1+ (1,0) [0|0] "" X
 SG_ EPB_w082_rightNvOv: 17|1@1+ (1,0) [0|0] "" X
 SG_ EPB_w083_rightNvUv: 18|1@1+ (1,0) [0|0] "" X
 SG_ EPB_w084_rightPvOv: 19|1@1+ (1,0) [0|0] "" X
 SG_ EPB_w085_rightPvUv: 20|1@1+ (1,0) [0|0] "" X
 SG_ EPB_w086_rightSubstateErr: 21|1@1+ (1,0) [0|0] "" X
 SG_ EPB_w087_rightFirstShortApply: 22|1@1+ (1,0) [0|0] "" X
 SG_ EPB_w088_motorShortedReleaseR: 23|1@1+ (1,0) [0|0] "" X
 SG_ EPB_w089_motorShortedApplyR: 24|1@1+ (1,0) [0|0] "" X
 SG_ EPB_w090_noCurrentCalR: 25|1@1+ (1,0) [0|0] "" X
 SG_ EPB_w091_spuriousEncIntR: 26|1@1+ (1,0) [0|0] "" X
 SG_ EPB_w092_obsolete: 27|1@1+ (1,0) [0|0] "" X
 SG_ EPB_w093_dasMIA: 28|1@1+ (1,0) [0|0] "" X
 SG_ EPB_w094_inhibitEac: 29|1@1+ (1,0) [0|0] "" X
 SG_ EPB_w095_invalidConfig: 30|1@1+ (1,0) [0|0] "" X
 SG_ EPB_w096_epasMia: 31|1@1+ (1,0) [0|0] "" X
 SG_ EPB_w097_selfParkAborted: 32|1@1+ (1,0) [0|0] "" X
 SG_ EPB_w098_parkMia: 33|1@1+ (1,0) [0|0] "" X
 SG_ EPB_w099_pmMia: 34|1@1+ (1,0) [0|0] "" X
 SG_ EPB_w100_calibrationWarning: 35|1@1+ (1,0) [0|0] "" X
 SG_ EPB_w101_calibrationFault: 36|1@1+ (1,0) [0|0] "" X
 SG_ EPB_w102_eepromCorrupt: 37|1@1+ (1,0) [0|0] "" X
 SG_ EPB_w103_eepromUpdated: 38|1@1+ (1,0) [0|0] "" X
 SG_ EPB_w104_epbmStillAsleep: 39|1@1+ (1,0) [0|0] "" X
 SG_ EPB_w105_epbmWentToSleep: 40|1@1+ (1,0) [0|0] "" X
 SG_ EPB_w106_leftNVoltageLow: 41|1@1+ (1,0) [0|0] "" X
 SG_ EPB_w107_leftPVoltageHigh: 42|1@1+ (1,0) [0|0] "" X
 SG_ EPB_w108_rightNVoltageLow: 43|1@1+ (1,0) [0|0] "" X
 SG_ EPB_w109_rightPVoltageHigh: 44|1@1+ (1,0) [0|0] "" X
 SG_ EPB_w110_calWarningLeft: 45|1@1+ (1,0) [0|0] "" X
 SG_ EPB_w111_calWarningRight: 46|1@1+ (1,0) [0|0] "" X
 SG_ EPB_w112_calFaultLeft: 47|1@1+ (1,0) [0|0] "" X
 SG_ EPB_w113_calFaultRight: 48|1@1+ (1,0) [0|0] "" X
 SG_ EPB_w114_voltageWarning: 49|1@1+ (1,0) [0|0] "" X
 SG_ EPB_w115_currentWarning: 50|1@1+ (1,0) [0|0] "" X
 SG_ EPB_w116_unableToCalcGrade: 51|1@1+ (1,0) [0|0] "" X
 SG_ EPB_w117_usedFallbackValues: 52|1@1+ (1,0) [0|0] "" X
 SG_ EPB_w118_unused: 53|1@1+ (1,0) [0|0] "" X
 SG_ EPB_w119_unused: 54|1@1+ (1,0) [0|0] "" X
 SG_ EPB_w120_releaseLogL: 55|1@1+ (1,0) [0|0] "" X
 SG_ EPB_w121_releaseLogR: 56|1@1+ (1,0) [0|0] "" X
 SG_ EPB_w122_unused: 57|1@1+ (1,0) [0|0] "" X
 SG_ EPB_w123_releaseDistanceL: 58|1@1+ (1,0) [0|0] "" X
 SG_ EPB_w124_releaseDistanceR: 59|1@1+ (1,0) [0|0] "" X
 SG_ EPB_w125_gradeTooSteep: 60|1@1+ (1,0) [0|0] "" X
 SG_ EPB_w126_unused: 61|1@1+ (1,0) [0|0] "" X
 SG_ EPB_w127_unused: 62|1@1+ (1,0) [0|0] "" X
 SG_ EPB_w128_unused: 63|1@1+ (1,0) [0|0] "" X

BO_ 836 EPB_alertMatrix4: 8 ETH
 SG_ EPB_u001_calibrationRequired: 0|1@1+ (1,0) [0|0] "" X
 SG_ EPB_u002_carMayRoll: 1|1@1+ (1,0) [0|0] "" X
 SG_ EPB_u003_dynamicBrakeApplied: 2|1@1+ (1,0) [0|0] "" X
 SG_ EPB_u004_pressFootBrake: 3|1@1+ (1,0) [0|0] "" X
 SG_ EPB_u005_epbProblem: 4|1@1+ (1,0) [0|0] "" X
 SG_ EPB_u006_epbNotReleased: 5|1@1+ (1,0) [0|0] "" X
 SG_ EPB_u007_dynNotApplied: 6|1@1+ (1,0) [0|0] "" X
 SG_ EPB_u008_turnOnCarToPark: 7|1@1+ (1,0) [0|0] "" X
 SG_ EPB_u009_towModeEnabled: 8|1@1+ (1,0) [0|0] "" X
 SG_ EPB_u010_serviceModeEnabled: 9|1@1+ (1,0) [0|0] "" X
 SG_ EPB_u011_parkSlope: 10|1@1+ (1,0) [0|0] "" X

BO_ 1332 EPB_info: 8 ETH
 SG_ EPB_infoIndex M: 0|8@1+ (1,0) [0|0] "" X
 SG_ EPB_infoBuildType m10: 8|8@1+ (1,0) [0|0] "" X
 SG_ EPB_infoBuildConfigID m10: 16|16@1+ (1,0) [0|0] "" X
 SG_ EPB_infoHardwareID m10: 32|16@1+ (1,0) [0|0] "" X
 SG_ EPB_infoComponentID m10: 48|16@1+ (1,0) [0|0] "" X
 SG_ EPB_infoPcbaID m11: 16|8@1+ (1,0) [0|0] "" X
 SG_ EPB_infoAssemblyID m11: 24|8@1+ (1,0) [0|0] "" X
 SG_ EPB_infoUsageID m11: 32|16@1+ (1,0) [0|0] "" X
 SG_ EPB_infoSubUsageID m11: 48|16@1+ (1,0) [0|0] "" X
 SG_ EPB_infoApplicationCRC m13: 32|32@1+ (1,0) [0|0] "" X
 SG_ EPB_infoBootloaderSvnRevision m14: 8|24@1+ (1,0) [0|0] "" X
 SG_ EPB_infoAppGitHashBytes m17: 10|54@1+ (4,0) [0|0] "" X
 SG_ EPB_infoBootGitHashBytes m18: 10|54@1+ (4,0) [0|0] "" X
 SG_ EPB_infoPlatformType m19: 8|8@1+ (1,0) [0|0] "" X
 SG_ EPB_infoMajorVersion m19: 16|8@1+ (1,0) [0|0] "" X
 SG_ EPB_infoBranchOrigin m19: 24|8@1+ (1,0) [0|0] "" X
 SG_ EPB_infoMaturity m19: 32|8@1+ (1,0) [0|0] "" X
 SG_ EPB_infoHardwareRevision m19: 40|8@1+ (1,0) [0|0] "" X
 SG_ EPB_infoBootUdsProtoVersion m20: 8|8@1+ (1,0) [0|0] "" X
 SG_ EPB_infoBootloaderCRC m20: 32|32@1+ (1,0) [0|0] "" X

BO_ 516 EPB_status: 8 ETH
 SG_ EPB_brakeApplied: 22|2@1+ (1,0) [0|0] "" X
 SG_ EPB_brakeHwTypeMismatch: 16|1@1+ (1,0) [0|0] "" X
 SG_ EPB_brakeLight: 8|2@1+ (1,0) [0|0] "" X
 SG_ EPB_calibrationStateLeft: 27|3@1+ (1,0) [0|0] "" X
 SG_ EPB_calibrationStateRight: 47|3@1+ (1,0) [0|0] "" X
 SG_ EPB_ignoreCan: 34|2@1+ (1,0) [0|0] "" X
 SG_ EPB_mcuButtonAvailable: 40|1@1+ (1,0) [0|0] "" X
 SG_ EPB_requestUserConfirmation: 33|1@1+ (1,0) [0|0] "" X
 SG_ EPB_selfParkEnabled: 36|1@1+ (1,0) [0|0] "" X
 SG_ EPB_selfParkState: 37|3@1+ (1,0) [0|0] "" X
 SG_ EPB_state: 0|3@1+ (1,0) [0|0] "" X
 SG_ EPB_statePending: 24|3@1+ (1,0) [0|0] "" X
 SG_ EPB_stateRequest: 3|3@1+ (1,0) [0|0] "" X
 SG_ EPB_statusChecksum: 56|8@1+ (1,0) [0|0] "" X
 SG_ EPB_statusCounter: 52|4@1+ (1,0) [0|0] "" X
 SG_ EPB_substateL: 10|3@1+ (1,0) [0|0] "" X
 SG_ EPB_substateR: 13|3@1+ (1,0) [0|0] "" X
 SG_ EPB_syncState: 44|3@1+ (1,0) [0|0] "" X
 SG_ EPB_telltale: 41|3@1+ (1,0) [0|0] "" X
 SG_ EPB_towModeEnabled: 32|1@1+ (1,0) [0|0] "" X
 SG_ EPB_tsApply: 18|2@1+ (1,0) [0|0] "" X
 SG_ EPB_tsRelease: 20|2@1+ (1,0) [0|0] "" X

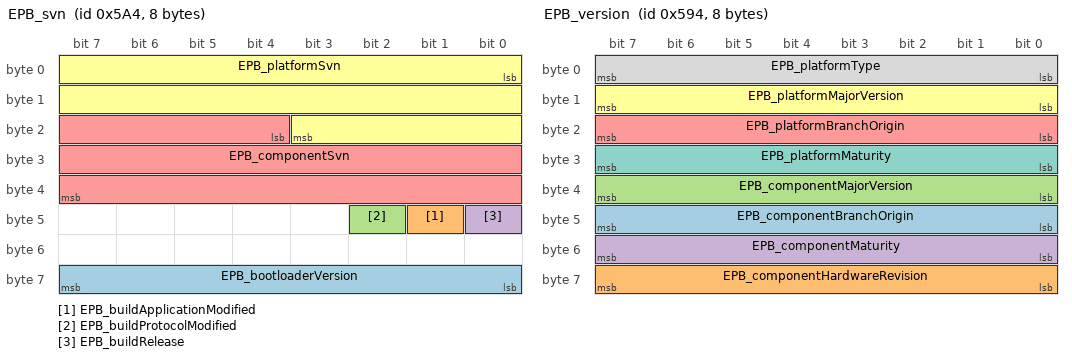
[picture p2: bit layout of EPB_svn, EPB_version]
BO_ 1444 EPB_svn: 8 ETH
 SG_ EPB_bootloaderVersion: 56|8@1+ (1,0) [0|0] "" X
 SG_ EPB_buildApplicationModified: 41|1@1+ (1,0) [0|0] "" X
 SG_ EPB_buildProtocolModified: 42|1@1+ (1,0) [0|0] "" X
 SG_ EPB_buildRelease: 40|1@1+ (1,0) [0|0] "" X
 SG_ EPB_componentSvn: 20|20@1+ (1,0) [0|0] "" X
 SG_ EPB_platformSvn: 0|20@1+ (1,0) [0|0] "" X

BO_ 1620 EPB_udsResponse: 8 ETH
 SG_ EPB_udsResponseData_H: 0|32@0+ (1,0) [0|0] "" X
 SG_ EPB_udsResponseData_L: 32|32@0+ (1,0) [0|0] "" X

BO_ 1428 EPB_version: 8 ETH
 SG_ EPB_componentBranchOrigin: 40|8@1+ (1,0) [0|0] "" X
 SG_ EPB_componentHardwareRevision: 56|8@1+ (1,0) [0|0] "" X
 SG_ EPB_componentMajorVersion: 32|8@1+ (1,0) [0|0] "" X
 SG_ EPB_componentMaturity: 48|8@1+ (1,0) [0|0] "" X
 SG_ EPB_platformBranchOrigin: 16|8@1+ (1,0) [0|0] "" X
 SG_ EPB_platformMajorVersion: 8|8@1+ (1,0) [0|0] "" X
 SG_ EPB_platformMaturity: 24|8@1+ (1,0) [0|0] "" X
 SG_ EPB_platformType: 0|8@1+ (1,0) [0|0] "" X

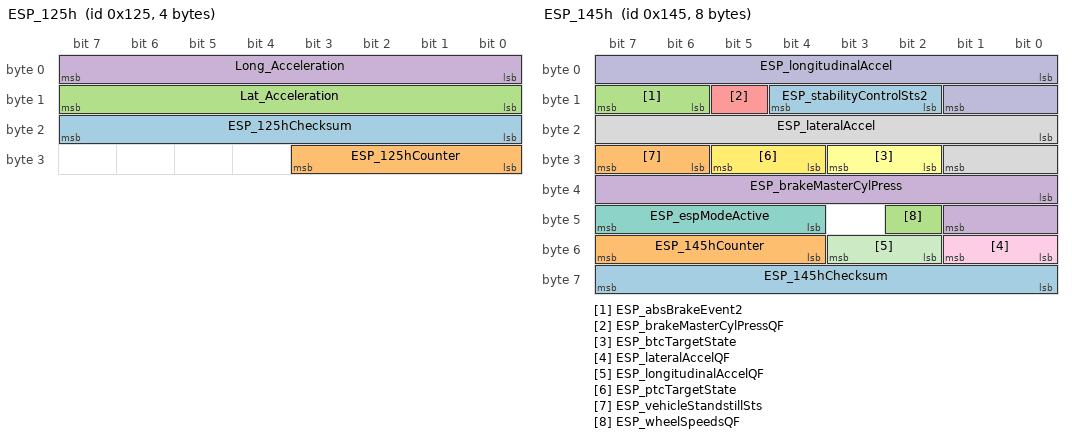
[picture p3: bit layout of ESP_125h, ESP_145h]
BO_ 293 ESP_125h: 4 ETH
 SG_ ESP_125hChecksum: 16|8@1+ (1,0) [0|0] "" X
 SG_ ESP_125hCounter: 24|4@1+ (1,0) [0|0] "" X
 SG_ Lat_Acceleration: 8|8@1- (0.08,0) [0|0] "m/s^2" X
 SG_ Long_Acceleration: 0|8@1- (0.08,0) [0|0] "m/s^2" X

BO_ 56 ESP_135h: 5 ETH
 SG_ ESP_135hChecksum: 16|8@1+ (1,0) [0|0] "" X
 SG_ ESP_135hCounter: 8|4@1+ (1,0) [0|0] "" X
 SG_ ESP_absBrakeEvent: 2|1@1+ (1,0) [0|0] "" X
 SG_ ESP_absFaultLamp: 27|1@1+ (1,0) [0|0] "" X
 SG_ ESP_brakeDiscWipingActive: 4|1@1+ (1,0) [0|0] "" X
 SG_ ESP_brakeLamp: 3|1@1+ (1,0) [0|0] "" X
 SG_ ESP_espFaultLamp: 6|1@1+ (1,0) [0|0] "" X
 SG_ ESP_espLampFlash: 7|1@1+ (1,0) [0|0] "" X
 SG_ ESP_espOffLamp: 31|1@1+ (1,0) [0|0] "" X
 SG_ ESP_hillStartAssistActive: 0|2@1+ (1,0) [0|0] "" X
 SG_ ESP_hydraulicBoostEnabled: 30|1@1+ (1,0) [0|0] "" X
 SG_ ESP_messageDynoModeActive: 29|1@1+ (1,0) [0|0] "" X
 SG_ ESP_messageEBDFailure: 26|1@1+ (1,0) [0|0] "" X
 SG_ ESP_messagePumpFailure: 25|1@1+ (1,0) [0|0] "" X
 SG_ ESP_messagePumpService: 24|1@1+ (1,0) [0|0] "" X
 SG_ ESP_stabilityControlSts: 12|3@1+ (1,0) [0|0] "" X
 SG_ ESP_tcDisabledByFault: 28|1@1+ (1,0) [0|0] "" X
 SG_ ESP_tcLampFlash: 5|1@1+ (1,0) [0|0] "" X
 SG_ ESP_tcOffLamp: 15|1@1+ (1,0) [0|0] "" X

BO_ 325 ESP_145h: 8 ETH
 SG_ ESP_145hChecksum: 56|8@1+ (1,0) [0|0] "" X
 SG_ ESP_145hCounter: 52|4@1+ (1,0) [0|0] "" X
 SG_ ESP_absBrakeEvent2: 14|2@1+ (1,0) [0|0] "" X
 SG_ ESP_brakeMasterCylPress: 32|10@1+ (0.25,-42.5) [0|0] "bar" X
 SG_ ESP_brakeMasterCylPressQF: 13|1@1+ (1,0) [0|0] "" X
 SG_ ESP_btcTargetState: 26|2@1+ (1,0) [0|0] "" X
 SG_ ESP_espModeActive: 44|4@1+ (1,0) [0|0] "" X
 SG_ ESP_lateralAccel: 16|10@1+ (0.05,-25.6) [0|0] "m/s^2" X
 SG_ ESP_lateralAccelQF: 48|2@1+ (1,0) [0|0] "" X
 SG_ ESP_longitudinalAccel: 0|10@1+ (0.05,-25.6) [0|0] "m/s^2" X
 SG_ ESP_longitudinalAccelQF: 50|2@1+ (1,0) [0|0] "" X
 SG_ ESP_ptcTargetState: 28|2@1+ (1,0) [0|0] "" X
 SG_ ESP_stabilityControlSts2: 10|3@1+ (1,0) [0|0] "" X
 SG_ ESP_vehicleStandstillSts: 30|2@1+ (1,0) [0|0] "" X
 SG_ ESP_wheelSpeedsQF: 42|1@1+ (1,0) [0|0] "" X

BO_ 1 ESP_B: 8 ETH
 SG_ ESP_BChecksum: 32|8@1+ (1,0) [0|0] "" X
 SG_ ESP_BCounter: 59|4@1+ (1,0) [0|0] "" X
 SG_ ESP_vehicleSpeed: 40|16@0+ (0.01,0) [0|0] "kph" X
 SG_ ESP_vehicleSpeedQF: 56|2@1+ (1,0) [0|0] "" X
 SG_ ESP_wheelPulseCountFrL: 0|8@1+ (1,0) [0|0] "" X
 SG_ ESP_wheelPulseCountFrR: 8|8@1+ (1,0) [0|0] "" X
 SG_ ESP_wheelPulseCountReL: 16|8@1+ (1,0) [0|0] "" X
 SG_ ESP_wheelPulseCountReR: 24|8@1+ (1,0) [0|0] "" X

BO_ 504 ESP_C_partial: 2 ETH
 SG_ ESP_driverBrakeApply: 14|2@1+ (1,0) [0|0] "" X
 SG_ ESP_yawRate: 0|12@1+ (0.001,-2) [0|0] "rad/s" X

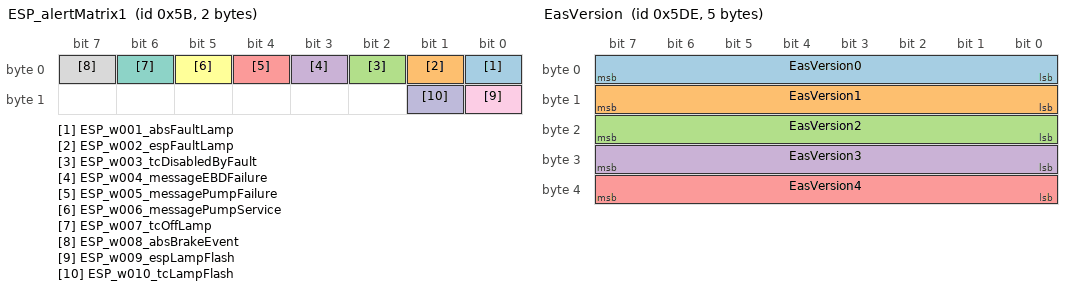
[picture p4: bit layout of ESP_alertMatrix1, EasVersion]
BO_ 91 ESP_alertMatrix1: 2 ETH
 SG_ ESP_w001_absFaultLamp: 0|1@1+ (1,0) [0|0] "" X
 SG_ ESP_w002_espFaultLamp: 1|1@1+ (1,0) [0|0] "" X
 SG_ ESP_w003_tcDisabledByFault: 2|1@1+ (1,0) [0|0] "" X
 SG_ ESP_w004_messageEBDFailure: 3|1@1+ (1,0) [0|0] "" X
 SG_ ESP_w005_messagePumpFailure: 4|1@1+ (1,0) [0|0] "" X
 SG_ ESP_w006_messagePumpService: 5|1@1+ (1,0) [0|0] "" X
 SG_ ESP_w007_tcOffLamp: 6|1@1+ (1,0) [0|0] "" X
 SG_ ESP_w008_absBrakeEvent: 7|1@1+ (1,0) [0|0] "" X
 SG_ ESP_w009_espLampFlash: 8|1@1+ (1,0) [0|0] "" X
 SG_ ESP_w010_tcLampFlash: 9|1@1+ (1,0) [0|0] "" X

BO_ 949 ESP_dtcMatrix: 8 ETH
 SG_ ESP_dtcIndex M: 0|8@1+ (1,0) [0|0] "" X
 SG_ ESP_d000_absPumpMotorControl m0: 8|2@1+ (1,0) [0|0] "" X
 SG_ ESP_d001_wssFLLineGnd m0: 10|2@1+ (1,0) [0|0] "" X
 SG_ ESP_d002_wssFLLineHigh m0: 12|2@1+ (1,0) [0|0] "" X
 SG_ ESP_d003_wssFLLineUndef m0: 14|2@1+ (1,0) [0|0] "" X
 SG_ ESP_d004_wssFLOutOfRange m0: 16|2@1+ (1,0) [0|0] "" X
 SG_ ESP_d005_wssFLSignalMissing m0: 18|2@1+ (1,0) [0|0] "" X
 SG_ ESP_d006_wssFLWrongSen m0: 20|2@1+ (1,0) [0|0] "" X
 SG_ ESP_d007_wssFLPlausibility m0: 22|2@1+ (1,0) [0|0] "" X
 SG_ ESP_d008_wssFAWrongMounting m0: 24|2@1+ (1,0) [0|0] "" X
 SG_ ESP_d009_wssFLAirGap m0: 26|2@1+ (1,0) [0|0] "" X
 SG_ ESP_d010_wssFLSupGnd m0: 28|2@1+ (1,0) [0|0] "" X
 SG_ ESP_d011_wssTstFLFld m0: 30|2@1+ (1,0) [0|0] "" X
 SG_ ESP_d012_wssFRLineGnd m0: 32|2@1+ (1,0) [0|0] "" X
 SG_ ESP_d013_wssFRLineHigh m0: 34|2@1+ (1,0) [0|0] "" X
 SG_ ESP_d014_wssFRLineUndef m0: 36|2@1+ (1,0) [0|0] "" X
 SG_ ESP_d015_wssFROutOfRange m0: 38|2@1+ (1,0) [0|0] "" X
 SG_ ESP_d016_wssFRSignalMissing m0: 40|2@1+ (1,0) [0|0] "" X
 SG_ ESP_d017_wssFRWrongSen m0: 42|2@1+ (1,0) [0|0] "" X
 SG_ ESP_d018_wssFRPlausibility m0: 44|2@1+ (1,0) [0|0] "" X
 SG_ ESP_d019_wssMonWheelDirFR m0: 46|2@1+ (1,0) [0|0] "" X
 SG_ ESP_d020_wssFRAirGap m0: 48|2@1+ (1,0) [0|0] "" X
 SG_ ESP_d021_wssFRSupGnd m0: 50|2@1+ (1,0) [0|0] "" X
 SG_ ESP_d022_wssTstFRFld m0: 52|2@1+ (1,0) [0|0] "" X
 SG_ ESP_d023_wssRLLineGnd m0: 54|2@1+ (1,0) [0|0] "" X
 SG_ ESP_d024_wssRLLineHigh m0: 56|2@1+ (1,0) [0|0] "" X
 SG_ ESP_d025_wssRLLineUndef m0: 58|2@1+ (1,0) [0|0] "" X
 SG_ ESP_d026_wssRLOutOfRange m0: 60|2@1+ (1,0) [0|0] "" X
 SG_ ESP_d027_wssRLSignalMissing m0: 62|2@1+ (1,0) [0|0] "" X
 SG_ ESP_d028_wssRLWrongSen m1: 8|2@1+ (1,0) [0|0] "" X
 SG_ ESP_d029_wssRLPlausibility m1: 10|2@1+ (1,0) [0|0] "" X
 SG_ ESP_d030_wssRAWrongMounting m1: 12|2@1+ (1,0) [0|0] "" X
 SG_ ESP_d031_wssRLAirGap m1: 14|2@1+ (1,0) [0|0] "" X
 SG_ ESP_d032_wssRLSupGnd m1: 16|2@1+ (1,0) [0|0] "" X
 SG_ ESP_d033_wssTstRLFld m1: 18|2@1+ (1,0) [0|0] "" X
 SG_ ESP_d034_wssRRLineGnd m1: 20|2@1+ (1,0) [0|0] "" X
 SG_ ESP_d035_wssRRLineHigh m1: 22|2@1+ (1,0) [0|0] "" X
 SG_ ESP_d036_wssRRLineUndef m1: 24|2@1+ (1,0) [0|0] "" X
 SG_ ESP_d037_wssRROutOfRange m1: 26|2@1+ (1,0) [0|0] "" X
 SG_ ESP_d038_wssRRSignalMissing m1: 28|2@1+ (1,0) [0|0] "" X
 SG_ ESP_d039_wssRRWrongSen m1: 30|2@1+ (1,0) [0|0] "" X
 SG_ ESP_d040_wssRRPlausibility m1: 32|2@1+ (1,0) [0|0] "" X
 SG_ ESP_d041_wssMonWheelDirRR m1: 34|2@1+ (1,0) [0|0] "" X
 SG_ ESP_d042_wssRRAirGap m1: 36|2@1+ (1,0) [0|0] "" X
 SG_ ESP_d043_wssRRSupGnd m1: 38|2@1+ (1,0) [0|0] "" X
 SG_ ESP_d044_wssTstRRFld m1: 40|2@1+ (1,0) [0|0] "" X
 SG_ ESP_d045_wssGeneralFault m1: 42|2@1+ (1,0) [0|0] "" X
 SG_ ESP_d046_brakeSwitchStuckHigh m1: 44|2@1+ (1,0) [0|0] "" X
 SG_ ESP_d047_blsStatusInvd m1: 46|2@1+ (1,0) [0|0] "" X
 SG_ ESP_d048_brakeSwitchPlausib m1: 48|2@1+ (1,0) [0|0] "" X
 SG_ ESP_d049_pressSenMc1Line m1: 50|2@1+ (1,0) [0|0] "" X
 SG_ ESP_d050_acmPsOfstMc1 m1: 52|2@1+ (1,0) [0|0] "" X
 SG_ ESP_d051_acmPsTstpulseMc1 m1: 54|2@1+ (1,0) [0|0] "" X
 SG_ ESP_d052_comSclLowBrakeFluid m1: 56|2@1+ (1,0) [0|0] "" X
 SG_ ESP_d053_sasMonConstSig m1: 58|2@1+ (1,0) [0|0] "" X
 SG_ ESP_d054_sasMonOfst m1: 60|2@1+ (1,0) [0|0] "" X
 SG_ ESP_d055_sasPlausibility m1: 62|2@1+ (1,0) [0|0] "" X
 SG_ ESP_d056_aySensorFault m2: 8|2@1+ (1,0) [0|0] "" X
 SG_ ESP_d057_aysMonRange m2: 10|2@1+ (1,0) [0|0] "" X
 SG_ ESP_d058_aysOffset m2: 12|2@1+ (1,0) [0|0] "" X
 SG_ ESP_d059_aysPlaus m2: 14|2@1+ (1,0) [0|0] "" X
 SG_ ESP_d060_axSensorFault m2: 16|2@1+ (1,0) [0|0] "" X
 SG_ ESP_d061_axsMonRange m2: 18|2@1+ (1,0) [0|0] "" X
 SG_ ESP_d062_axOffsTooLarge m2: 20|2@1+ (1,0) [0|0] "" X
 SG_ ESP_d063_axSensorPlaus m2: 22|2@1+ (1,0) [0|0] "" X
 SG_ ESP_d064_yawSensorFault m2: 24|2@1+ (1,0) [0|0] "" X
 SG_ ESP_d065_yawSensorPlaus m2: 26|2@1+ (1,0) [0|0] "" X
 SG_ ESP_d066_absVdcContControl m2: 28|2@1+ (1,0) [0|0] "" X
 SG_ ESP_d067_undervoltage m2: 30|2@1+ (1,0) [0|0] "" X
 SG_ ESP_d068_overvoltage m2: 32|2@1+ (1,0) [0|0] "" X
 SG_ ESP_d069_memoryFault m2: 34|2@1+ (1,0) [0|0] "" X
 SG_ ESP_d070_ecuInternalGeneric m2: 36|2@1+ (1,0) [0|0] "" X
 SG_ ESP_d071_ecuInternalEcu m2: 38|2@1+ (1,0) [0|0] "" X
 SG_ ESP_d072_valveGeneric m2: 40|2@1+ (1,0) [0|0] "" X
 SG_ ESP_d073_valveAvFaults m2: 42|2@1+ (1,0) [0|0] "" X
 SG_ ESP_d074_valveEvFaults m2: 44|2@1+ (1,0) [0|0] "" X
 SG_ ESP_d075_valveHsvFaults m2: 46|2@1+ (1,0) [0|0] "" X
 SG_ ESP_d076_valveUsvFaults m2: 48|2@1+ (1,0) [0|0] "" X
 SG_ ESP_d077_refNotInitInTime m2: 50|2@1+ (1,0) [0|0] "" X
 SG_ ESP_d078_acmBtmOheatBraking m2: 52|2@1+ (1,0) [0|0] "" X
 SG_ ESP_d079_varCodeEeprom m2: 54|2@1+ (1,0) [0|0] "" X
 SG_ ESP_d080_reverseGearPlaus m2: 56|2@1+ (1,0) [0|0] "" X
 SG_ ESP_d081_comSclVinAllZeroFF m2: 58|2@1+ (1,0) [0|0] "" X
 SG_ ESP_d082_comSclVip405HsImpVin m2: 60|2@1+ (1,0) [0|0] "" X
 SG_ ESP_d083_comSclVip405HsDtCrpt m2: 62|2@1+ (1,0) [0|0] "" X
 SG_ ESP_d084_comSclVip405HsTout m3: 8|2@1+ (1,0) [0|0] "" X
 SG_ ESP_d085_rollerBenchActv m3: 10|2@1+ (1,0) [0|0] "" X
 SG_ ESP_d086_network0 m3: 12|2@1+ (1,0) [0|0] "" X
 SG_ ESP_d087_network1 m3: 14|2@1+ (1,0) [0|0] "" X
 SG_ ESP_d088_comMotorTOut m3: 16|2@1+ (1,0) [0|0] "" X
 SG_ ESP_d089_comDrsTxTOut m3: 18|2@1+ (1,0) [0|0] "" X
 SG_ ESP_d090_comSclStwAnglhpTout m3: 20|2@1+ (1,0) [0|0] "" X
 SG_ ESP_d091_comSclEpbStatusTout m3: 22|2@1+ (1,0) [0|0] "" X
 SG_ ESP_d092_comIbEsptTOut m3: 24|2@1+ (1,0) [0|0] "" X
 SG_ ESP_d093_comSclBdyStatusTout m3: 26|2@1+ (1,0) [0|0] "" X
 SG_ ESP_d094_comSclGtwEsp1Tout m3: 28|2@1+ (1,0) [0|0] "" X
 SG_ ESP_d095_comSclGtwOdoTout m3: 30|2@1+ (1,0) [0|0] "" X
 SG_ ESP_d096_comSclGtwCarCfgTout m3: 32|2@1+ (1,0) [0|0] "" X
 SG_ ESP_d097_comMotorCrpt m3: 34|2@1+ (1,0) [0|0] "" X
 SG_ ESP_d098_comMotorMsgCount m3: 36|2@1+ (1,0) [0|0] "" X
 SG_ ESP_d099_comMotorInvalidSig m3: 38|2@1+ (1,0) [0|0] "" X
 SG_ ESP_d100_comSclEpbStatusCrpt m3: 40|2@1+ (1,0) [0|0] "" X
 SG_ ESP_d101_comIbEspCrpt m3: 42|2@1+ (1,0) [0|0] "" X
 SG_ ESP_d102_comIbEspMsgCount m3: 44|2@1+ (1,0) [0|0] "" X
 SG_ ESP_d103_sclIbEspInvalidSig m3: 46|2@1+ (1,0) [0|0] "" X
 SG_ ESP_d104_comSclBdyStatusCrpt m3: 48|2@1+ (1,0) [0|0] "" X
 SG_ ESP_d105_comStwAnglHpCrpt m3: 50|2@1+ (1,0) [0|0] "" X
 SG_ ESP_d106_comStwAnglHpMsgCount m3: 52|2@1+ (1,0) [0|0] "" X
 SG_ ESP_d107_comSasInvalidSig m3: 54|2@1+ (1,0) [0|0] "" X
 SG_ ESP_d108_comDrsTxCrpt m3: 56|2@1+ (1,0) [0|0] "" X
 SG_ ESP_d109_sclMm3InvalidSig m3: 58|2@1+ (1,0) [0|0] "" X
 SG_ ESP_d110_comGtwEsp1Crpt m3: 60|2@1+ (1,0) [0|0] "" X
 SG_ ESP_d111_comSclGtwEsp1CntFlt m3: 62|2@1+ (1,0) [0|0] "" X
 SG_ ESP_d112_comSclGtwOdoDtCrpt m4: 8|2@1+ (1,0) [0|0] "" X
 SG_ ESP_d113_comSclGtwCrCfgDtCrpt m4: 10|2@1+ (1,0) [0|0] "" X
 SG_ ESP_d114_teslaChassisTypeSna m4: 12|2@1+ (1,0) [0|0] "" X
 SG_ ESP_d115_varPlatCalMismtch m4: 14|2@1+ (1,0) [0|0] "" X
 SG_ ESP_d116_ptsBlsStatusInvd m4: 16|2@1+ (1,0) [0|0] "" X
 SG_ ESP_d117_comSclBdwReqInvalid m4: 18|2@1+ (1,0) [0|0] "" X
 SG_ ESP_d118_rcmInvalidAx m4: 20|2@1+ (1,0) [0|0] "" X
 SG_ ESP_d119_rcmInvalidAy m4: 22|2@1+ (1,0) [0|0] "" X
 SG_ ESP_d120_rcmInvalidYaw m4: 24|2@1+ (1,0) [0|0] "" X
 SG_ ESP_d121_rcmInvalidFrame1 m4: 26|2@1+ (1,0) [0|0] "" X
 SG_ ESP_d122_rcmInvalidFrame2 m4: 28|2@1+ (1,0) [0|0] "" X
 SG_ ESP_d123_rcmLostComm m4: 30|2@1+ (1,0) [0|0] "" X
 SG_ ESP_d124_rcmIncompleteSensInfo m4: 32|2@1+ (1,0) [0|0] "" X
 SG_ ESP_d125_rcmSerialNumMismatch m4: 34|2@1+ (1,0) [0|0] "" X
 SG_ ESP_d126_rcmWrongSensorConfig m4: 36|2@1+ (1,0) [0|0] "" X
 SG_ ESP_d127_rcmInvalidCalibration m4: 38|2@1+ (1,0) [0|0] "" X
 SG_ ESP_d128_comSclPmState2TOut m4: 40|2@1+ (1,0) [0|0] "" X
 SG_ ESP_d129_sclBdwReqActiveInvd m4: 42|2@1+ (1,0) [0|0] "" X
 SG_ ESP_d130_comPmState2Crpt m4: 44|2@1+ (1,0) [0|0] "" X
 SG_ ESP_d131_comSclPmState2CntFlt m4: 46|2@1+ (1,0) [0|0] "" X
 SG_ ESP_d132_sclPmEbrCmdStateInvd m4: 48|2@1+ (1,0) [0|0] "" X
 SG_ ESP_d133_acmVsSignalPlaus m5: 8|2@1+ (1,0) [0|0] "" X
 SG_ ESP_d134_sasMonRange m5: 10|2@1+ (1,0) [0|0] "" X
 SG_ ESP_d135_sasMonGrad m5: 12|2@1+ (1,0) [0|0] "" X
 SG_ ESP_d136_yrsSignalOutOfRange m5: 14|2@1+ (1,0) [0|0] "" X
 SG_ ESP_d137_yrsMonGrad m5: 16|2@1+ (1,0) [0|0] "" X
 SG_ ESP_d138_yrsOffsetTooLarge m5: 18|2@1+ (1,0) [0|0] "" X
 SG_ ESP_d139_evpSigPlausibility m5: 20|2@1+ (1,0) [0|0] "" X
 SG_ ESP_d140_evpVacSigLow m5: 22|2@1+ (1,0) [0|0] "" X
 SG_ ESP_d141_vacSensorElectFail m5: 24|2@1+ (1,0) [0|0] "" X
 SG_ ESP_d142_canCommGeneral m5: 26|2@1+ (1,0) [0|0] "" X
 SG_ ESP_d143_mcuChassisContrDtCrpt m5: 28|2@1+ (1,0) [0|0] "" X
 SG_ ESP_d144_mcuChassisContrTout m5: 30|2@1+ (1,0) [0|0] "" X

BO_ 805 ESP_info: 8 ETH
 SG_ ESP_infoIndex M: 0|8@1+ (1,0) [0|0] "" X
 SG_ ESP_buildType m10: 8|8@1+ (1,0) [0|0] "" X
 SG_ ESP_componentId m10: 48|16@1+ (1,0) [0|0] "" X
 SG_ ESP_pcbaId m11: 16|8@1+ (1,0) [0|0] "" X
 SG_ ESP_assemblyId m11: 24|8@1+ (1,0) [0|0] "" X
 SG_ ESP_usageId m11: 32|16@1+ (1,0) [0|0] "" X
 SG_ ESP_applicationCrc m13: 32|32@1+ (1,0) [0|0] "" X
 SG_ ESP_vehicleVariant m16: 16|8@1+ (1,0) [0|0] "" X
 SG_ ESP_udsProtocolVersion m20: 8|8@1+ (1,0) [0|0] "" X
 SG_ ESP_bootloaderCrc m20: 32|32@1+ (1,0) [0|0] "" X
 SG_ ESP_variantCrc m22: 32|32@1+ (1,0) [0|0] "" X

BO_ 1621 ESP_udsResponse: 8 ETH
 SG_ ESP_udsResponse: 0|54@0+ (1024,0) [0|0] "" X

BO_ 1502 EasVersion: 5 ETH
 SG_ EasVersion0: 0|8@1+ (1,0) [0|0] "" X
 SG_ EasVersion1: 8|8@1+ (1,0) [0|0] "" X
 SG_ EasVersion2: 16|8@1+ (1,0) [0|0] "" X
 SG_ EasVersion3: 24|8@1+ (1,0) [0|0] "" X
 SG_ EasVersion4: 32|8@1+ (1,0) [0|0] "" X

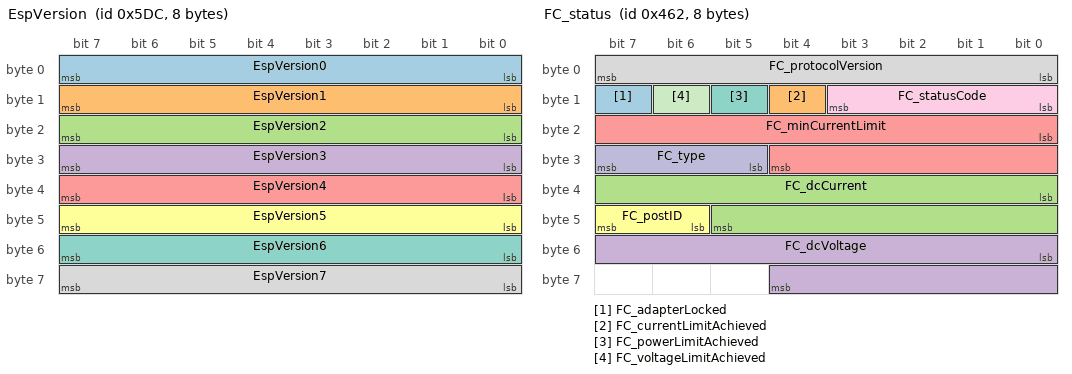
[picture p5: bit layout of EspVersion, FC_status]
BO_ 1500 EspVersion: 8 ETH
 SG_ EspVersion0: 0|8@1+ (1,0) [0|0] "" X
 SG_ EspVersion1: 8|8@1+ (1,0) [0|0] "" X
 SG_ EspVersion2: 16|8@1+ (1,0) [0|0] "" X
 SG_ EspVersion3: 24|8@1+ (1,0) [0|0] "" X
 SG_ EspVersion4: 32|8@1+ (1,0) [0|0] "" X
 SG_ EspVersion5: 40|8@1+ (1,0) [0|0] "" X
 SG_ EspVersion6: 48|8@1+ (1,0) [0|0] "" X
 SG_ EspVersion7: 56|8@1+ (1,0) [0|0] "" X

BO_ 533 FC_info: 8 ETH
 SG_ FC_infoDummySig: 7|1@1+ (1,0) [0|0] "" X
 SG_ FC_infoIndex M: 0|7@1+ (1,0) [0|0] "" X
 SG_ FC_infoBuildType m10: 8|8@1+ (1,0) [0|0] "" X
 SG_ FC_infoBuildConfigID m10: 16|16@1+ (1,0) [0|0] "" X
 SG_ FC_infoHardwareID m10: 32|16@1+ (1,0) [0|0] "" X
 SG_ FC_infoComponentID m10: 48|16@1+ (1,0) [0|0] "" X
 SG_ FC_infoPcbaID m11: 16|8@1+ (1,0) [0|0] "" X
 SG_ FC_infoAssemblyID m11: 24|8@1+ (1,0) [0|0] "" X
 SG_ FC_infoUsageID m11: 32|16@1+ (1,0) [0|0] "" X
 SG_ FC_infoSubUsageID m11: 48|16@1+ (1,0) [0|0] "" X
 SG_ FC_infoApplicationCRC m13: 32|32@1+ (1,0) [0|0] "" X
 SG_ FC_infoBootSvnRev m14: 8|24@1+ (1,0) [0|0] "" X
 SG_ FC_infoBootCRC m15: 32|32@1+ (1,0) [0|0] "" X
 SG_ FC_infoCPLDVersionMajor m16: 16|8@1+ (1,0) [0|0] "" X
 SG_ FC_infoCPLDVersionMinor m16: 24|8@1+ (1,0) [0|0] "" X
 SG_ FC_infoAppGitHashBytes m17: 10|54@1+ (4,0) [0|0] "" X
 SG_ FC_infoBootGitHashBytes m18: 10|54@1+ (4,0) [0|0] "" X
 SG_ FC_infoPlatformType m19: 8|8@1+ (1,0) [0|0] "" X
 SG_ FC_infoMajorVersion m19: 16|8@1+ (1,0) [0|0] "" X
 SG_ FC_infoBranchOrigin m19: 24|8@1+ (1,0) [0|0] "" X
 SG_ FC_infoMaturity m19: 32|8@1+ (1,0) [0|0] "" X
 SG_ FC_infoHardwareRevision m19: 40|8@1+ (1,0) [0|0] "" X
 SG_ FC_infoBootUdsProtoVersion m20: 8|8@1+ (1,0) [0|0] "" X
 SG_ FC_partNumChar01 m25: 8|8@1+ (1,0) [0|0] "" X
 SG_ FC_partNumChar02 m25: 16|8@1+ (1,0) [0|0] "" X
 SG_ FC_partNumChar03 m25: 24|8@1+ (1,0) [0|0] "" X
 SG_ FC_partNumChar04 m25: 32|8@1+ (1,0) [0|0] "" X
 SG_ FC_partNumChar05 m25: 40|8@1+ (1,0) [0|0] "" X
 SG_ FC_partNumChar06 m25: 48|8@1+ (1,0) [0|0] "" X
 SG_ FC_partNumChar07 m25: 56|8@1+ (1,0) [0|0] "" X
 SG_ FC_partNumChar08 m26: 8|8@1+ (1,0) [0|0] "" X
 SG_ FC_partNumChar09 m26: 16|8@1+ (1,0) [0|0] "" X
 SG_ FC_partNumChar10 m26: 24|8@1+ (1,0) [0|0] "" X
 SG_ FC_partNumChar11 m26: 32|8@1+ (1,0) [0|0] "" X
 SG_ FC_partNumChar12 m26: 40|8@1+ (1,0) [0|0] "" X
 SG_ FC_partNumChar13 m26: 48|8@1+ (1,0) [0|0] "" X
 SG_ FC_partNumChar14 m26: 56|8@1+ (1,0) [0|0] "" X
 SG_ FC_partNumChar15 m27: 8|8@1+ (1,0) [0|0] "" X
 SG_ FC_partNumChar16 m27: 16|8@1+ (1,0) [0|0] "" X
 SG_ FC_partNumChar17 m27: 24|8@1+ (1,0) [0|0] "" X
 SG_ FC_partNumChar18 m27: 32|8@1+ (1,0) [0|0] "" X
 SG_ FC_partNumChar19 m27: 40|8@1+ (1,0) [0|0] "" X
 SG_ FC_partNumChar20 m27: 48|8@1+ (1,0) [0|0] "" X

BO_ 543 FC_serial: 8 ETH
 SG_ FC_serialDataSelect M: 0|7@1+ (1,0) [0|0] "" X
 SG_ FC_serialDummySig: 7|1@1+ (1,0) [0|0] "" X
 SG_ FC_serialChar01 m0: 8|8@1+ (1,0) [0|0] "" X
 SG_ FC_serialChar02 m0: 16|8@1+ (1,0) [0|0] "" X
 SG_ FC_serialChar03 m0: 24|8@1+ (1,0) [0|0] "" X
 SG_ FC_serialChar04 m0: 32|8@1+ (1,0) [0|0] "" X
 SG_ FC_serialChar05 m0: 40|8@1+ (1,0) [0|0] "" X
 SG_ FC_serialChar06 m0: 48|8@1+ (1,0) [0|0] "" X
 SG_ FC_serialChar07 m0: 56|8@1+ (1,0) [0|0] "" X
 SG_ FC_serialChar08 m1: 8|8@1+ (1,0) [0|0] "" X
 SG_ FC_serialChar09 m1: 16|8@1+ (1,0) [0|0] "" X
 SG_ FC_serialChar10 m1: 24|8@1+ (1,0) [0|0] "" X
 SG_ FC_serialChar11 m1: 32|8@1+ (1,0) [0|0] "" X
 SG_ FC_serialChar12 m1: 40|8@1+ (1,0) [0|0] "" X
 SG_ FC_serialChar13 m1: 48|8@1+ (1,0) [0|0] "" X
 SG_ FC_serialChar14 m1: 56|8@1+ (1,0) [0|0] "" X
 SG_ FC_serialChar15 m2: 8|8@1+ (1,0) [0|0] "" X
 SG_ FC_serialChar16 m2: 16|8@1+ (1,0) [0|0] "" X
 SG_ FC_serialChar17 m2: 24|8@1+ (1,0) [0|0] "" X

BO_ 1122 FC_status: 8 ETH
 SG_ FC_adapterLocked: 15|1@1+ (1,0) [0|0] "" X
 SG_ FC_currentLimitAchieved: 12|1@1+ (1,0) [0|0] "" X
 SG_ FC_dcCurrent: 32|14@1- (0.0732422,0) [0|0] "A" X
 SG_ FC_dcVoltage: 48|13@1+ (0.0732422,0) [0|0] "V" X
 SG_ FC_minCurrentLimit: 16|13@1+ (0.1,0) [0|0] "A" X
 SG_ FC_postID: 46|2@1+ (2,0) [0|0] "" X
 SG_ FC_powerLimitAchieved: 13|1@1+ (1,0) [0|0] "" X
 SG_ FC_protocolVersion: 0|8@1+ (1,0) [0|0] "" X
 SG_ FC_statusCode: 8|4@1+ (1,0) [0|0] "" X
 SG_ FC_type: 29|3@1+ (1,0) [0|0] "" X
 SG_ FC_voltageLimitAchieved: 14|1@1+ (1,0) [0|0] "" X

BO_ 1123 FC_status2: 1 ETH
 SG_ FC_externalIsolationResistance: 0|8@1+ (40,0) [0|0] "kOhm" X

BO_ 1124 FC_status3: 8 ETH
 SG_ FC_status3DataSelect M: 0|7@1+ (1,0) [0|0] "" X
 SG_ FC_status3DummySig: 7|1@1+ (1,0) [0|0] "" X
 SG_ FC_class m0: 8|8@1+ (1,0) [0|0] "" X
 SG_ FC_brand m0: 16|4@1+ (1,0) [0|0] "" X
 SG_ FC_coolingType m0: 20|4@1+ (1,0) [0|0] "" X
 SG_ FC_uiStopType m0: 24|4@1+ (1,0) [0|0] "" X

BO_ 644 FC_userMatrix1: 8 ETH
 SG_ FC_u001_scPostOutOfService: 0|1@1+ (1,0) [0|0] "" X
 SG_ FC_u002_scPowerShared: 1|1@1+ (1,0) [0|0] "" X

BO_ 645 FC_userMatrix2: 8 ETH
 SG_ FC_u065_userData: 10|54@1+ (1024,0) [0|0] "" X

BO_ 643 FC_warningMatrix3: 8 ETH
 SG_ FC_w129_CA_flyback_HW_OC: 0|1@1+ (1,0) [0|0] "" X
 SG_ FC_w130_CA_flyback_SW_OV: 1|1@1+ (1,0) [0|0] "" X
 SG_ FC_w131_CA_flyback_HW_OV: 2|1@1+ (1,0) [0|0] "" X
 SG_ FC_w132_CA_bmsMia: 3|1@1+ (1,0) [0|0] "" X
 SG_ FC_w133_CA_evseMia: 4|1@1+ (1,0) [0|0] "" X
 SG_ FC_w134_CA_vehTxBufOvf: 5|1@1+ (1,0) [0|0] "" X
 SG_ FC_w135_CA_vehRxBufOvf: 6|1@1+ (1,0) [0|0] "" X
 SG_ FC_w136_CA_evseTxBufOvf: 7|1@1+ (1,0) [0|0] "" X
 SG_ FC_w137_CA_evseRxBufOvf: 8|1@1+ (1,0) [0|0] "" X
 SG_ FC_w138_CA_hwProxTrip: 9|1@1+ (1,0) [0|0] "" X
 SG_ FC_w139_CA_ss2NotLow: 10|1@1+ (1,0) [0|0] "" X
 SG_ FC_w140_CA_bmsIncompatible: 11|1@1+ (1,0) [0|0] "" X
 SG_ FC_w141_CA_vehConn_OT: 12|1@1+ (1,0) [0|0] "" X
 SG_ FC_w142_CA_evseConn_OT: 13|1@1+ (1,0) [0|0] "" X
 SG_ FC_w143_CA_pcb_OT: 14|1@1+ (1,0) [0|0] "" X
 SG_ FC_w144_CA_flybackUnstable: 15|1@1+ (1,0) [0|0] "" X
 SG_ FC_w145_CA_flybackDataStale: 16|1@1+ (1,0) [0|0] "" X
 SG_ FC_w146_CA_flybackBusLoadHi: 17|1@1+ (1,0) [0|0] "" X
 SG_ FC_w147_CA_vehConn_UT: 18|1@1+ (1,0) [0|0] "" X
 SG_ FC_w148_CA_evseConn_UT: 19|1@1+ (1,0) [0|0] "" X
 SG_ FC_w149_CA_pcb_UT: 20|1@1+ (1,0) [0|0] "" X
 SG_ FC_w150_CA_vehToEvseDeltaHi: 21|1@1+ (1,0) [0|0] "" X
 SG_ FC_w151_CA_vehToEvseDeltaLo: 22|1@1+ (1,0) [0|0] "" X
 SG_ FC_w152_CA_vehToPcbDeltaHi: 23|1@1+ (1,0) [0|0] "" X
 SG_ FC_w153_CA_evseToPcbDeltaHi: 24|1@1+ (1,0) [0|0] "" X
 SG_ FC_w154_CA_vehToPcbDeltaLo: 25|1@1+ (1,0) [0|0] "" X
 SG_ FC_w155_CA_evseToPcbDeltaLo: 26|1@1+ (1,0) [0|0] "" X
 SG_ FC_w156_CA_flybackRunTimeout: 27|1@1+ (1,0) [0|0] "" X
 SG_ FC_w157_CA_unused: 28|1@1+ (1,0) [0|0] "" X
 SG_ FC_w158_CA_evseOverCurrent: 29|1@1+ (1,0) [0|0] "" X
 SG_ FC_w159_CA_wdtExpired: 30|1@1+ (1,0) [0|0] "" X
 SG_ FC_w160_CA_ss2Deasserted: 31|1@1+ (1,0) [0|0] "" X
 SG_ FC_w161_CA_vehTempHiFoldBk: 32|1@1+ (1,0) [0|0] "" X
 SG_ FC_w162_CA_evseTempHiFoldBk: 33|1@1+ (1,0) [0|0] "" X
 SG_ FC_w163_CA_pcbTempHiFoldBk: 34|1@1+ (1,0) [0|0] "" X
 SG_ FC_w164_CA_proxDisconnected: 35|1@1+ (1,0) [0|0] "" X
 SG_ FC_w165_CA_evseConnUnlocked: 36|1@1+ (1,0) [0|0] "" X
 SG_ FC_w166_CA_vehConnUnlocked: 37|1@1+ (1,0) [0|0] "" X
 SG_ FC_w167_CA_isoVoltageLow: 38|1@1+ (1,0) [0|0] "" X
 SG_ FC_w168_CA_proxTimeout: 39|1@1+ (1,0) [0|0] "" X
 SG_ FC_w169_CA_pilotAcceptTimeout: 40|1@1+ (1,0) [0|0] "" X
 SG_ FC_w170_CA_vehDataTimeout: 41|1@1+ (1,0) [0|0] "" X
 SG_ FC_w171_CA_vehConLockTimeout: 42|1@1+ (1,0) [0|0] "" X
 SG_ FC_w172_CA_ss2LowTimeout: 43|1@1+ (1,0) [0|0] "" X
 SG_ FC_w173_CA_evseDataTimeout: 44|1@1+ (1,0) [0|0] "" X
 SG_ FC_w174_CA_vehReadyTimeout: 45|1@1+ (1,0) [0|0] "" X
 SG_ FC_w175_CA_evseIsoTestTimeout: 46|1@1+ (1,0) [0|0] "" X
 SG_ FC_w176_CA_chargingBusTimeout: 47|1@1+ (1,0) [0|0] "" X
 SG_ FC_w177_CA_bmsCtrCloseTimeout: 48|1@1+ (1,0) [0|0] "" X
 SG_ FC_w178_CA_evseStartTimeout: 49|1@1+ (1,0) [0|0] "" X
 SG_ FC_w179_CA_startupProblem: 50|1@1+ (1,0) [0|0] "" X
 SG_ FC_w180_CA_chargingProblem: 51|1@1+ (1,0) [0|0] "" X
 SG_ FC_w181_CA_vRegBrownout: 52|1@1+ (1,0) [0|0] "" X
 SG_ FC_w182_CA_evseChrMalfunc: 53|1@1+ (1,0) [0|0] "" X
 SG_ FC_w183_CA_evseBatIncompat: 54|1@1+ (1,0) [0|0] "" X
 SG_ FC_w184_CA_evseBatMalfunc: 55|1@1+ (1,0) [0|0] "" X
 SG_ FC_w185_CA_vehReadyDeasserted: 56|1@1+ (1,0) [0|0] "" X
 SG_ FC_w186_CA_fcContOpenTimeout: 57|1@1+ (1,0) [0|0] "" X
 SG_ FC_w187_CA_evseConLockTimeout: 58|1@1+ (1,0) [0|0] "" X

BO_ 646 FC_warningMatrix4: 8 ETH
 SG_ FC_w193_FCAlertPlaceholder: 10|54@1+ (1024,0) [0|0] "" X

BO_ 650 FC_warningMatrix5: 8 ETH
 SG_ FC_w257_GB_bmsMia: 0|1@1+ (1,0) [0|0] "" X
 SG_ FC_w258_GB_evseMia: 1|1@1+ (1,0) [0|0] "" X
 SG_ FC_w259_GB_vehTxBufOvf: 2|1@1+ (1,0) [0|0] "" X
 SG_ FC_w260_GB_vehRxBufOvf: 3|1@1+ (1,0) [0|0] "" X
 SG_ FC_w261_GB_evseTxBufOvf: 4|1@1+ (1,0) [0|0] "" X
 SG_ FC_w262_GB_evseRxBufOvf: 5|1@1+ (1,0) [0|0] "" X
 SG_ FC_w263_GB_hwProxTrip: 6|1@1+ (1,0) [0|0] "" X
 SG_ FC_w264_GB_ss2NotLow: 7|1@1+ (1,0) [0|0] "" X
 SG_ FC_w265_GB_bmsIncompatible: 8|1@1+ (1,0) [0|0] "" X
 SG_ FC_w266_GB_negPin_OT: 9|1@1+ (1,0) [0|0] "" X
 SG_ FC_w267_GB_posPin_OT: 10|1@1+ (1,0) [0|0] "" X
 SG_ FC_w268_GB_pcb_OT: 11|1@1+ (1,0) [0|0] "" X
 SG_ FC_w269_GB_unused: 12|1@1+ (1,0) [0|0] "" X
 SG_ FC_w270_GB_unused: 13|1@1+ (1,0) [0|0] "" X
 SG_ FC_w271_GB_unused: 14|1@1+ (1,0) [0|0] "" X
 SG_ FC_w272_GB_negToPosDeltaHi: 15|1@1+ (1,0) [0|0] "" X
 SG_ FC_w273_GB_negToPosDeltaLo: 16|1@1+ (1,0) [0|0] "" X
 SG_ FC_w274_GB_negToPcbDeltaHi: 17|1@1+ (1,0) [0|0] "" X
 SG_ FC_w275_GB_posToPcbDeltaHi: 18|1@1+ (1,0) [0|0] "" X
 SG_ FC_w276_GB_negToPcbDeltaLo: 19|1@1+ (1,0) [0|0] "" X
 SG_ FC_w277_GB_posToPcbDeltaLo: 20|1@1+ (1,0) [0|0] "" X
 SG_ FC_w278_GB_unused: 21|1@1+ (1,0) [0|0] "" X
 SG_ FC_w279_GB_evseOverCurrent: 22|1@1+ (1,0) [0|0] "" X
 SG_ FC_w280_GB_unused: 23|1@1+ (1,0) [0|0] "" X
 SG_ FC_w281_GB_ss2Deasserted: 24|1@1+ (1,0) [0|0] "" X
 SG_ FC_w282_GB_negTempHiFoldBk: 25|1@1+ (1,0) [0|0] "" X
 SG_ FC_w283_GB_posTempHiFoldBk: 26|1@1+ (1,0) [0|0] "" X
 SG_ FC_w284_GB_pcbTempHiFoldBk: 27|1@1+ (1,0) [0|0] "" X
 SG_ FC_w285_GB_proxDisconnected: 28|1@1+ (1,0) [0|0] "" X
 SG_ FC_w286_GB_evseConnUnlocked: 29|1@1+ (1,0) [0|0] "" X
 SG_ FC_w287_GB_vehConnUnlocked: 30|1@1+ (1,0) [0|0] "" X
 SG_ FC_w288_GB_isoVoltageLow: 31|1@1+ (1,0) [0|0] "" X
 SG_ FC_w289_GB_proxTimeout: 32|1@1+ (1,0) [0|0] "" X
 SG_ FC_w290_GB_pilotAcceptTimeout: 33|1@1+ (1,0) [0|0] "" X
 SG_ FC_w291_GB_vehDataTimeout: 34|1@1+ (1,0) [0|0] "" X
 SG_ FC_w292_GB_vehConLockTimeout: 35|1@1+ (1,0) [0|0] "" X
 SG_ FC_w293_GB_ss2LowTimeout: 36|1@1+ (1,0) [0|0] "" X
 SG_ FC_w294_GB_evseDataTimeout: 37|1@1+ (1,0) [0|0] "" X
 SG_ FC_w295_GB_vehReadyTimeout: 38|1@1+ (1,0) [0|0] "" X
 SG_ FC_w296_GB_evseIsoTestTimeout: 39|1@1+ (1,0) [0|0] "" X
 SG_ FC_w297_GB_chargingBusTimeout: 40|1@1+ (1,0) [0|0] "" X
 SG_ FC_w298_GB_bmsCtrCloseTimeout: 41|1@1+ (1,0) [0|0] "" X
 SG_ FC_w299_GB_evseReadyTimeout: 42|1@1+ (1,0) [0|0] "" X
 SG_ FC_w300_GB_startupProblem: 43|1@1+ (1,0) [0|0] "" X
 SG_ FC_w301_GB_chargingProblem: 44|1@1+ (1,0) [0|0] "" X
 SG_ FC_w302_GB_vRegBrownout: 45|1@1+ (1,0) [0|0] "" X
 SG_ FC_w303_GB_negRecogTimeout: 46|1@1+ (1,0) [0|0] "" X
 SG_ FC_w304_GB_evseIncompatible: 47|1@1+ (1,0) [0|0] "" X
 SG_ FC_w305_GB_posRecogTimeout: 48|1@1+ (1,0) [0|0] "" X
 SG_ FC_w306_GB_vehReadyDeasserted: 49|1@1+ (1,0) [0|0] "" X
 SG_ FC_w307_GB_fcContOpenTimeout: 50|1@1+ (1,0) [0|0] "" X
 SG_ FC_w308_GB_evseConLockTimeout: 51|1@1+ (1,0) [0|0] "" X
 SG_ FC_w309_GB_unused: 52|1@1+ (1,0) [0|0] "" X
 SG_ FC_w310_GB_vehicleIdTimeout: 53|1@1+ (1,0) [0|0] "" X
 SG_ FC_w311_GB_battParamsTimeout: 54|1@1+ (1,0) [0|0] "" X
 SG_ FC_w312_GB_evseLimitsTimeout: 55|1@1+ (1,0) [0|0] "" X

BO_ 651 FC_warningMatrix6: 8 ETH
 SG_ FC_w321_FCAlertPlaceholder: 10|54@1+ (1024,0) [0|0] "" X

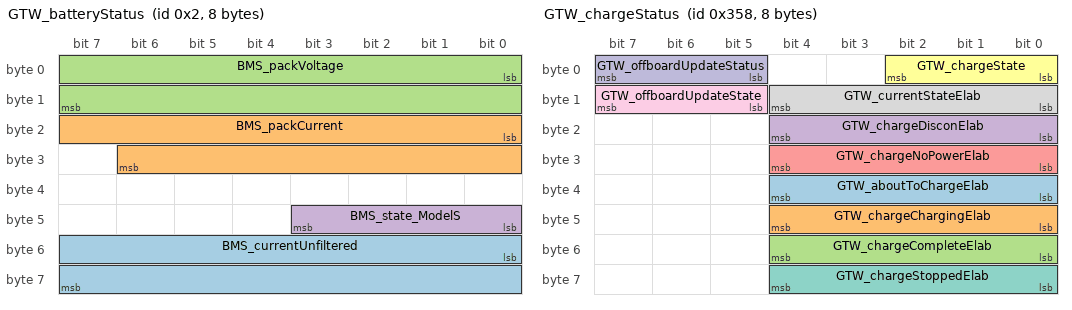
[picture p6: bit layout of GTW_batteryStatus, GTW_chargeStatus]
BO_ 2 GTW_batteryStatus: 8 ETH
 SG_ BMS_currentUnfiltered: 48|16@1- (0.05,-1000) [0|0] "A" X
 SG_ BMS_packCurrent: 16|15@1- (0.1,-1000) [0|0] "A" X
 SG_ BMS_packVoltage: 0|16@1+ (0.01,0) [0|0] "V" X
 SG_ BMS_state_ModelS: 40|4@1+ (1,0) [0|0] "" X

BO_ 523 GTW_captureAck: 4 ETH
 SG_ GTW_captureBus: 8|8@1+ (1,0) [0|0] "" X
 SG_ GTW_captureMessage: 16|16@0+ (1,0) [0|0] "" X
 SG_ GTW_captureState: 0|8@1+ (1,0) [0|0] "" X

BO_ 792 GTW_carConfig: 8 ETH
 SG_ GTW_HVJB16APerPhaseOK: 22|1@1+ (1,0) [0|0] "" X
 SG_ GTW_airbagCutoffInstalled: 32|1@1+ (1,0) [0|0] "" X
 SG_ GTW_audioType: 28|2@1+ (1,0) [0|0] "" X
 SG_ GTW_autopilot: 62|2@1+ (1,0) [0|0] "" X
 SG_ GTW_autopilotTrial: 25|1@1+ (1,0) [0|0] "" X
 SG_ GTW_auxHvacType: 60|1@1+ (1,0) [0|0] "" X
 SG_ GTW_cornerInstalled: 52|1@1+ (1,0) [0|0] "" X
 SG_ GTW_country: 0|16@0+ (1,0) [0|0] "" X
 SG_ GTW_drlInstalled: 48|1@1+ (1,0) [0|0] "" X
 SG_ GTW_euVehicle: 39|1@1+ (1,0) [0|0] "" X
 SG_ GTW_fastChargeAllowed: 35|2@1+ (1,0) [0|0] "" X
 SG_ GTW_forceTrunksClosed: 41|1@1+ (1,0) [0|0] "" X
 SG_ GTW_fourWheelDrive: 43|1@1+ (1,0) [0|0] "" X
 SG_ GTW_frontFogInstalled: 16|1@1+ (1,0) [0|0] "" X
 SG_ GTW_frunkLatchType: 21|1@1+ (1,0) [0|0] "" X
 SG_ GTW_gpsType: 58|2@1+ (1,0) [0|0] "" X
 SG_ GTW_ionizerType: 23|1@1+ (1,0) [0|0] "" X
 SG_ GTW_memoryMirrorsInstalled: 26|1@1+ (1,0) [0|0] "" X
 SG_ GTW_memorySeatsInstalled: 33|2@1+ (1,0) [0|0] "" X
 SG_ GTW_noKeylessEntry: 50|1@1+ (1,0) [0|0] "" X
 SG_ GTW_noPack: 30|1@1+ (1,0) [0|0] "" X
 SG_ GTW_noVehicleSleep: 31|1@1+ (1,0) [0|0] "" X
 SG_ GTW_ocsInstalled: 38|1@1+ (1,0) [0|0] "" X
 SG_ GTW_performanceConfig: 53|3@1+ (1,0) [0|0] "" X
 SG_ GTW_plcAdapterType: 45|1@1+ (1,0) [0|0] "" X
 SG_ GTW_powerLiftGate: 49|1@1+ (1,0) [0|0] "" X
 SG_ GTW_rearDriveUnitType: 47|1@1+ (1,0) [0|0] "" X
 SG_ GTW_rearFogInstalled: 17|1@1+ (1,0) [0|0] "" X
 SG_ GTW_rhd: 27|1@1+ (1,0) [0|0] "" X
 SG_ GTW_roofColor: 56|2@1+ (1,0) [0|0] "" X
 SG_ GTW_seatHeatersInstalled: 44|1@1+ (1,0) [0|0] "" X
 SG_ GTW_showcar: 42|1@1+ (1,0) [0|0] "" X
 SG_ GTW_steeringHeat: 24|1@1+ (1,0) [0|0] "" X
 SG_ GTW_steeringWheel: 18|3@1+ (1,0) [0|0] "" X
 SG_ GTW_thBusInstalled: 61|1@1+ (1,0) [0|0] "" X
 SG_ GTW_towPackage: 51|1@1+ (1,0) [0|0] "" X
 SG_ GTW_useKey: 40|1@1+ (1,0) [0|0] "" X

BO_ 794 GTW_carConfig2: 8 ETH
 SG_ GTW_ambientLightsInstalled: 52|1@1+ (1,0) [0|0] "" X
 SG_ GTW_badging: 18|3@1+ (1,0) [0|0] "" X
 SG_ GTW_boardRevision: 32|8@1+ (1,0) [0|0] "" X
 SG_ GTW_bodyControlsType: 63|1@1+ (1,0) [0|0] "" X
 SG_ GTW_chargerType: 56|3@1+ (1,0) [0|0] "" X
 SG_ GTW_dimmableRvMirror: 59|1@1+ (1,0) [0|0] "" X
 SG_ GTW_exteriorColorCode: 0|8@1+ (1,0) [0|0] "" X
 SG_ GTW_foldingMirrorsInstalled: 45|1@1+ (1,0) [0|0] "" X
 SG_ GTW_frontSeatVentilationType: 21|3@1+ (1,0) [0|0] "" X
 SG_ GTW_headLampType: 40|2@1+ (1,0) [0|0] "" X
 SG_ GTW_interiorColorCode: 8|8@1+ (1,0) [0|0] "" X
 SG_ GTW_intrusionTiltInstalled: 16|2@1+ (1,0) [0|0] "" X
 SG_ GTW_isEbuck: 46|1@1+ (1,0) [0|0] "" X
 SG_ GTW_lightPipeInstalled: 47|1@1+ (1,0) [0|0] "" X
 SG_ GTW_noPushToUnlock: 53|1@1+ (1,0) [0|0] "" X
 SG_ GTW_noSpeedPulse: 54|1@1+ (1,0) [0|0] "" X
 SG_ GTW_nozzleHeatInstalled: 44|1@1+ (1,0) [0|0] "" X
 SG_ GTW_otherFastChargeAllowed: 60|1@1+ (1,0) [0|0] "" X
 SG_ GTW_packConfig: 24|8@1+ (1,0) [0|0] "" X
 SG_ GTW_powerLiftgateStrutType: 50|1@1+ (1,0) [0|0] "" X
 SG_ GTW_sideMarkerInstalled: 55|1@1+ (1,0) [0|0] "" X
 SG_ GTW_simulatedS1: 42|1@1+ (1,0) [0|0] "" X
 SG_ GTW_steeringColumnType: 51|1@1+ (1,0) [0|0] "" X
 SG_ GTW_thirdRowSeatType: 48|2@1+ (1,0) [0|0] "" X
 SG_ GTW_tpmsType: 61|2@1+ (1,0) [0|0] "" X
 SG_ GTW_wiperHeatInstalled: 43|1@1+ (1,0) [0|0] "" X

BO_ 131 GTW_carConfig3: 8 ETH
 SG_ GTW_airSuspensionInstalled: 24|3@1+ (1,0) [0|0] "" X
 SG_ GTW_backupCameraType: 15|1@1+ (1,0) [0|0] "" X
 SG_ GTW_brakeHwType: 28|2@1+ (1,0) [0|0] "" X
 SG_ GTW_compressorType: 38|2@1+ (1,0) [0|0] "" X
 SG_ GTW_curveLightingType: 31|1@1+ (1,0) [0|0] "" X
 SG_ GTW_dasHw: 20|4@1+ (1,0) [0|0] "" X
 SG_ GTW_displayBacklightFilmType: 11|1@1+ (1,0) [0|0] "" X
 SG_ GTW_epasType: 35|3@1+ (1,0) [0|0] "" X
 SG_ GTW_espInterface: 8|2@1+ (1,0) [0|0] "" X
 SG_ GTW_freeSlaveCharger: 10|1@1+ (1,0) [0|0] "" X
 SG_ GTW_frontDriveUnitType: 12|1@1+ (1,0) [0|0] "" X
 SG_ GTW_headlightLevelerInstalled: 54|2@1+ (1,0) [0|0] "" X
 SG_ GTW_intakeAirFilterType: 59|3@1+ (1,0) [0|0] "" X
 SG_ GTW_mapRegion: 0|4@1+ (1,0) [0|0] "" X
 SG_ GTW_navigationAllowed: 18|2@1+ (1,0) [0|0] "" X
 SG_ GTW_numberHVILNodes: 32|3@1+ (1,0) [0|0] "" X
 SG_ GTW_parkAssistInstalled: 16|2@1+ (1,0) [0|0] "" X
 SG_ GTW_radarPosition: 44|4@1+ (1,0) [0|0] "" X
 SG_ GTW_rearFacingSeats: 7|1@1+ (1,0) [0|0] "" X
 SG_ GTW_rearSeatControllerMask: 56|3@1+ (1,0) [0|0] "" X
 SG_ GTW_restraintControlsType: 6|1@1+ (1,0) [0|0] "" X
 SG_ GTW_spoilerInstalled: 62|2@1+ (1,0) [0|0] "" X
 SG_ GTW_sunroofInstalled: 4|2@1+ (1,0) [0|0] "" X
 SG_ GTW_topSpeedEnum: 13|2@1+ (1,0) [0|0] "" X
 SG_ GTW_updateWhatYouSee: 30|1@1+ (1,0) [0|0] "" X
 SG_ GTW_wheelType: 48|5@1+ (1,0) [0|0] "" X
 SG_ GTW_xmAntInstalled: 27|1@1+ (1,0) [0|0] "" X

BO_ 793 GTW_carConfig4: 8 ETH
 SG_ GTW_chassisType: 34|2@1+ (1,0) [0|0] "" X
 SG_ GTW_devTPMSType: 31|1@1+ (1,0) [0|0] "" X
 SG_ GTW_efficiencyPackage: 16|1@1+ (1,0) [0|0] "" X
 SG_ GTW_efuseType: 46|2@1+ (1,0) [0|0] "" X
 SG_ GTW_exvType: 3|1@1+ (1,0) [0|0] "" X
 SG_ GTW_falconCapSensorInstalled: 57|1@1+ (1,0) [0|0] "" X
 SG_ GTW_falconInwardUSSInstalled: 54|2@1+ (1,0) [0|0] "" X
 SG_ GTW_falconStrutType: 56|1@1+ (1,0) [0|0] "" X
 SG_ GTW_fasciaType: 5|1@1+ (1,0) [0|0] "" X
 SG_ GTW_fastChargeInstalled: 24|2@1+ (1,0) [0|0] "" X
 SG_ GTW_forwardRadarHw: 58|2@1+ (1,0) [0|0] "" X
 SG_ GTW_frontDoorActuationType: 17|2@1+ (1,0) [0|0] "" X
 SG_ GTW_frontDoorLatchType: 22|1@1+ (1,0) [0|0] "" X
 SG_ GTW_homelinkInstalled: 42|2@1+ (1,0) [0|0] "" X
 SG_ GTW_parkSensorGeometryType: 32|2@1+ (1,0) [0|0] "" X
 SG_ GTW_performanceAddOn: 44|2@1+ (1,0) [0|0] "" X
 SG_ GTW_performanceLock: 53|1@1+ (1,0) [0|0] "" X
 SG_ GTW_prototypeType: 6|2@1+ (1,0) [0|0] "" X
 SG_ GTW_pwsSpeakerType: 20|1@1+ (1,0) [0|0] "" X
 SG_ GTW_pwsSupported: 19|1@1+ (1,0) [0|0] "" X
 SG_ GTW_rearSeatHeatersInstalled: 50|3@1+ (1,0) [0|0] "" X
 SG_ GTW_rearSeatType: 0|3@1+ (1,0) [0|0] "" X
 SG_ GTW_restraintsHardwareType: 8|8@1+ (1,0) [0|0] "" X
 SG_ GTW_screenAdhesiveType: 41|1@1+ (1,0) [0|0] "" X
 SG_ GTW_seatType: 26|2@1+ (1,0) [0|0] "" X
 SG_ GTW_shutterType: 4|1@1+ (1,0) [0|0] "" X
 SG_ GTW_softPackConfig: 60|4@1+ (1,0) [0|0] "" X
 SG_ GTW_standbySupplyRequired: 23|1@1+ (1,0) [0|0] "" X
 SG_ GTW_steeringColumnHarness: 39|1@1+ (1,0) [0|0] "" X
 SG_ GTW_temperatureHumiditySensor: 40|1@1+ (1,0) [0|0] "" X
 SG_ GTW_thirdRowSeatHeatType: 48|2@1+ (1,0) [0|0] "" X
 SG_ GTW_tractionControlType: 21|1@1+ (1,0) [0|0] "" X
 SG_ GTW_twelveVBatteryType: 36|3@1+ (1,0) [0|0] "" X

BO_ 856 GTW_chargeStatus: 8 ETH
 SG_ GTW_aboutToChargeElab: 32|5@1+ (1,0) [0|0] "" X
 SG_ GTW_chargeChargingElab: 40|5@1+ (1,0) [0|0] "" X
 SG_ GTW_chargeCompleteElab: 48|5@1+ (1,0) [0|0] "" X
 SG_ GTW_chargeDisconElab: 16|5@1+ (1,0) [0|0] "" X
 SG_ GTW_chargeNoPowerElab: 24|5@1+ (1,0) [0|0] "" X
 SG_ GTW_chargeState: 0|3@1+ (1,0) [0|0] "" X
 SG_ GTW_chargeStoppedElab: 56|5@1+ (1,0) [0|0] "" X
 SG_ GTW_currentStateElab: 8|5@1+ (1,0) [0|0] "" X
 SG_ GTW_offboardUpdateState: 13|3@1+ (1,0) [0|0] "" X
 SG_ GTW_offboardUpdateStatus: 5|3@1+ (1,0) [0|0] "" X

BO_ 824 GTW_dtcMatrix: 8 ETH
 SG_ GTW_dtcIndex M: 0|8@1+ (1,0) [0|0] "" X
 SG_ GTW_d001_versionMismatch m0: 8|2@1+ (1,0) [0|0] "" X
 SG_ GTW_d002_12VOvervoltage m0: 10|2@1+ (1,0) [0|0] "" X
 SG_ GTW_d003_12VUndervoltage m0: 12|2@1+ (1,0) [0|0] "" X
 SG_ GTW_d004_replaceGateway m0: 14|2@1+ (1,0) [0|0] "" X
 SG_ GTW_d005_componentMia m0: 16|2@1+ (1,0) [0|0] "" X
 SG_ GTW_d006_replace12VBattery m0: 18|2@1+ (1,0) [0|0] "" X
 SG_ GTW_d007_chgMia m0: 20|2@1+ (1,0) [0|0] "" X
 SG_ GTW_d008_diMia m0: 22|2@1+ (1,0) [0|0] "" X
 SG_ GTW_d009_bmsMia m0: 24|2@1+ (1,0) [0|0] "" X
 SG_ GTW_d010_dcdcMia m0: 26|2@1+ (1,0) [0|0] "" X
 SG_ GTW_d011_thcMia m0: 28|2@1+ (1,0) [0|0] "" X
 SG_ GTW_d012_bdyMia m0: 30|2@1+ (1,0) [0|0] "" X
 SG_ GTW_d013_epbMia m0: 32|2@1+ (1,0) [0|0] "" X

BO_ 257 GTW_epasControl_reduced: 3 ETH
 SG_ GTW_epasTuneRequest: 0|3@1+ (1,0) [0|0] "" X

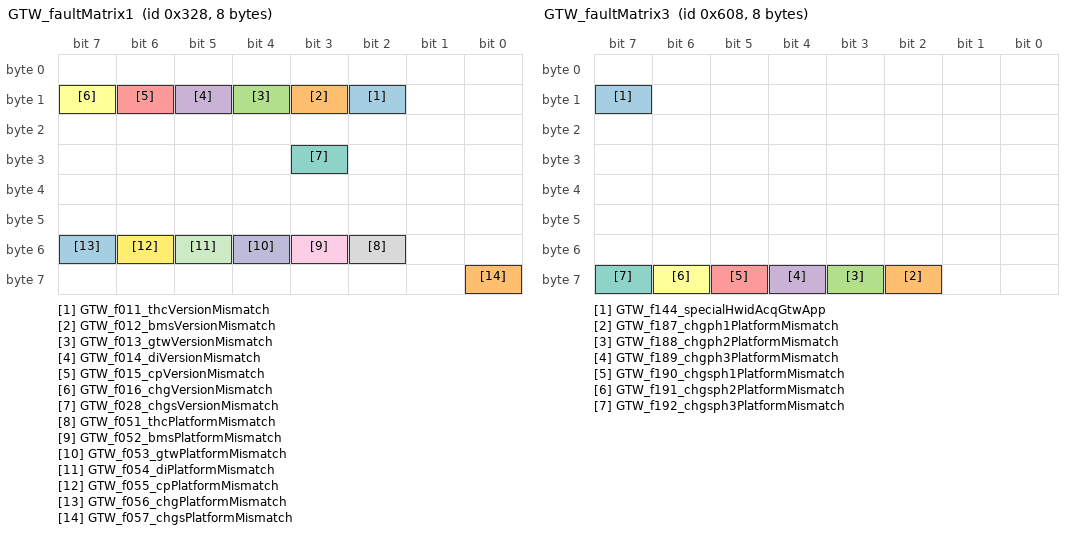
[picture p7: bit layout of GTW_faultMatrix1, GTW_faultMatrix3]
BO_ 808 GTW_faultMatrix1: 8 ETH
 SG_ GTW_f011_thcVersionMismatch: 10|1@1+ (1,0) [0|0] "" X
 SG_ GTW_f012_bmsVersionMismatch: 11|1@1+ (1,0) [0|0] "" X
 SG_ GTW_f013_gtwVersionMismatch: 12|1@1+ (1,0) [0|0] "" X
 SG_ GTW_f014_diVersionMismatch: 13|1@1+ (1,0) [0|0] "" X
 SG_ GTW_f015_cpVersionMismatch: 14|1@1+ (1,0) [0|0] "" X
 SG_ GTW_f016_chgVersionMismatch: 15|1@1+ (1,0) [0|0] "" X
 SG_ GTW_f028_chgsVersionMismatch: 27|1@1+ (1,0) [0|0] "" X
 SG_ GTW_f051_thcPlatformMismatch: 50|1@1+ (1,0) [0|0] "" X
 SG_ GTW_f052_bmsPlatformMismatch: 51|1@1+ (1,0) [0|0] "" X
 SG_ GTW_f053_gtwPlatformMismatch: 52|1@1+ (1,0) [0|0] "" X
 SG_ GTW_f054_diPlatformMismatch: 53|1@1+ (1,0) [0|0] "" X
 SG_ GTW_f055_cpPlatformMismatch: 54|1@1+ (1,0) [0|0] "" X
 SG_ GTW_f056_chgPlatformMismatch: 55|1@1+ (1,0) [0|0] "" X
 SG_ GTW_f057_chgsPlatformMismatch: 56|1@1+ (1,0) [0|0] "" X

BO_ 1528 GTW_faultMatrix2: 8 ETH
 SG_ GTW_f067_missingFirmwareRc: 2|1@1+ (1,0) [0|0] "" X
 SG_ GTW_f081_disVersionMismatch: 16|1@1+ (1,0) [0|0] "" X
 SG_ GTW_f082_disPlatformMismatch: 17|1@1+ (1,0) [0|0] "" X
 SG_ GTW_f084_pmVersionMismatch: 19|1@1+ (1,0) [0|0] "" X
 SG_ GTW_f085_pmPlatformMismatch: 20|1@1+ (1,0) [0|0] "" X
 SG_ GTW_f094_bmsCpldVersionMismatch: 29|1@1+ (1,0) [0|0] "" X
 SG_ GTW_f095_chgCpldVersionMismatch: 30|1@1+ (1,0) [0|0] "" X
 SG_ GTW_f096_diCpldVersionMismatch: 31|1@1+ (1,0) [0|0] "" X
 SG_ GTW_f097_chgsCpldVersionMismatch: 32|1@1+ (1,0) [0|0] "" X
 SG_ GTW_f098_disCpldVersionMismatch: 33|1@1+ (1,0) [0|0] "" X
 SG_ GTW_f100_epbVersionMismatch: 35|1@1+ (1,0) [0|0] "" X
 SG_ GTW_f101_epbPlatformMismatch: 36|1@1+ (1,0) [0|0] "" X
 SG_ GTW_f102_epbmVersionMismatch: 37|1@1+ (1,0) [0|0] "" X
 SG_ GTW_f103_epbmPlatformMismatch: 38|1@1+ (1,0) [0|0] "" X
 SG_ GTW_f106_espVersionMismatch: 41|1@1+ (1,0) [0|0] "" X
 SG_ GTW_f126_icVersionMismatch: 61|1@1+ (1,0) [0|0] "" X
 SG_ GTW_f127_epasVersionMismatch: 62|1@1+ (1,0) [0|0] "" X

BO_ 1544 GTW_faultMatrix3: 8 ETH
 SG_ GTW_f144_specialHwidAcqGtwApp: 15|1@1+ (1,0) [0|0] "" X
 SG_ GTW_f187_chgph1PlatformMismatch: 58|1@1+ (1,0) [0|0] "" X
 SG_ GTW_f188_chgph2PlatformMismatch: 59|1@1+ (1,0) [0|0] "" X
 SG_ GTW_f189_chgph3PlatformMismatch: 60|1@1+ (1,0) [0|0] "" X
 SG_ GTW_f190_chgsph1PlatformMismatch: 61|1@1+ (1,0) [0|0] "" X
 SG_ GTW_f191_chgsph2PlatformMismatch: 62|1@1+ (1,0) [0|0] "" X
 SG_ GTW_f192_chgsph3PlatformMismatch: 63|1@1+ (1,0) [0|0] "" X

BO_ 1496 GTW_faultMatrix4: 8 ETH
 SG_ GTW_f193_chgph1VersionMismatch: 0|1@1+ (1,0) [0|0] "" X
 SG_ GTW_f194_chgph2VersionMismatch: 1|1@1+ (1,0) [0|0] "" X
 SG_ GTW_f195_chgph3VersionMismatch: 2|1@1+ (1,0) [0|0] "" X
 SG_ GTW_f196_chgph1CpldVersMismatch: 3|1@1+ (1,0) [0|0] "" X
 SG_ GTW_f197_chgph2CpldVersMismatch: 4|1@1+ (1,0) [0|0] "" X
 SG_ GTW_f198_chgph3CpldVersMismatch: 5|1@1+ (1,0) [0|0] "" X
 SG_ GTW_f199_chgsph1VersionMismatch: 6|1@1+ (1,0) [0|0] "" X
 SG_ GTW_f200_chgsph2VersionMismatch: 7|1@1+ (1,0) [0|0] "" X
 SG_ GTW_f201_chgsph3VersionMismatch: 8|1@1+ (1,0) [0|0] "" X
 SG_ GTW_f202_chgsph1CpldVersMismatch: 9|1@1+ (1,0) [0|0] "" X
 SG_ GTW_f203_chgsph2CpldVersMismatch: 10|1@1+ (1,0) [0|0] "" X
 SG_ GTW_f204_chgsph3CpldVersMismatch: 11|1@1+ (1,0) [0|0] "" X
 SG_ GTW_f205_firmwareRcModuleProblem: 12|1@1+ (1,0) [0|0] "" X
 SG_ GTW_f208_noDriveAllowed: 15|1@1+ (1,0) [0|0] "" X
 SG_ GTW_f209_noChargeAllowed: 16|1@1+ (1,0) [0|0] "" X
 SG_ GTW_f210_noSupportAllowed: 17|1@1+ (1,0) [0|0] "" X
 SG_ GTW_f227_icPlatformMismatch: 34|1@1+ (1,0) [0|0] "" X
 SG_ GTW_f228_icFpgaVersionMismatch: 35|1@1+ (1,0) [0|0] "" X
 SG_ GTW_f231_pmsVersionMismatch: 38|1@1+ (1,0) [0|0] "" X
 SG_ GTW_f232_pmsPlatformMismatch: 39|1@1+ (1,0) [0|0] "" X
 SG_ GTW_f236_buildTypeMismatch: 43|1@1+ (1,0) [0|0] "" X
 SG_ GTW_f241_dasVersionMismatch: 48|1@1+ (1,0) [0|0] "" X
 SG_ GTW_f243_espConfigMismatch: 50|1@1+ (1,0) [0|0] "" X
 SG_ GTW_f244_bcConfigMismatch: 51|1@1+ (1,0) [0|0] "" X
 SG_ GTW_f246_espCalVersionMismatch: 53|1@1+ (1,0) [0|0] "" X
 SG_ GTW_f248_bccenVersionMismatch: 55|1@1+ (1,0) [0|0] "" X
 SG_ GTW_f249_bcfdmVersionMismatch: 56|1@1+ (1,0) [0|0] "" X
 SG_ GTW_f250_bcfrontVersionMismatch: 57|1@1+ (1,0) [0|0] "" X
 SG_ GTW_f251_bcrdmVersionMismatch: 58|1@1+ (1,0) [0|0] "" X
 SG_ GTW_f252_bcrearVersionMismatch: 59|1@1+ (1,0) [0|0] "" X
 SG_ GTW_f253_radcVersionMismatch: 60|1@1+ (1,0) [0|0] "" X
 SG_ GTW_f254_bccenPlatformMismatch: 61|1@1+ (1,0) [0|0] "" X
 SG_ GTW_f255_bcfdmPlatformMismatch: 62|1@1+ (1,0) [0|0] "" X
 SG_ GTW_f256_bcfrontPlatformMismatch: 63|1@1+ (1,0) [0|0] "" X

BO_ 1992 GTW_faultMatrix5: 8 ETH
 SG_ GTW_f257_bcrdmPlatformMismatch: 0|1@1+ (1,0) [0|0] "" X
 SG_ GTW_f258_bcrearPlatformMismatch: 1|1@1+ (1,0) [0|0] "" X
 SG_ GTW_f259_radcPlatformMismatch: 2|1@1+ (1,0) [0|0] "" X
 SG_ GTW_f266_ibstVersionMismatch: 9|1@1+ (1,0) [0|0] "" X
 SG_ GTW_f267_ibstCalMismatch: 10|1@1+ (1,0) [0|0] "" X
 SG_ GTW_f272_chgrlyPlatformMismatch: 15|1@1+ (1,0) [0|0] "" X
 SG_ GTW_f278_bcfpmPlatformMismatch: 21|1@1+ (1,0) [0|0] "" X
 SG_ GTW_f279_bcfpmVersionMismatch: 22|1@1+ (1,0) [0|0] "" X
 SG_ GTW_f280_bcrpmPlatformMismatch: 23|1@1+ (1,0) [0|0] "" X
 SG_ GTW_f281_bcrpmVersionMismatch: 24|1@1+ (1,0) [0|0] "" X
 SG_ GTW_f282_bcs2lPlatformMismatch: 25|1@1+ (1,0) [0|0] "" X
 SG_ GTW_f284_bcs2cPlatformMismatch: 27|1@1+ (1,0) [0|0] "" X
 SG_ GTW_f286_bcs2rPlatformMismatch: 29|1@1+ (1,0) [0|0] "" X
 SG_ GTW_f288_bcfalcdPlatformMismatch: 31|1@1+ (1,0) [0|0] "" X
 SG_ GTW_f289_bcfalcdVersionMismatch: 32|1@1+ (1,0) [0|0] "" X
 SG_ GTW_f293_espHwCfgMismatch: 36|1@1+ (1,0) [0|0] "" X
 SG_ GTW_f294_ibstHwCfgMismatch: 37|1@1+ (1,0) [0|0] "" X
 SG_ GTW_f295_rcmConfigMismatch: 38|1@1+ (1,0) [0|0] "" X
 SG_ GTW_f296_rcmVersionMismatch: 39|1@1+ (1,0) [0|0] "" X
 SG_ GTW_f298_rcmcalVersionMismatch: 41|1@1+ (1,0) [0|0] "" X
 SG_ GTW_f316_bcfalcpPlatformMismatch: 59|1@1+ (1,0) [0|0] "" X
 SG_ GTW_f317_bcfalcpVersionMismatch: 60|1@1+ (1,0) [0|0] "" X
 SG_ GTW_f320_airSuspPlatformMismatch: 63|1@1+ (1,0) [0|0] "" X

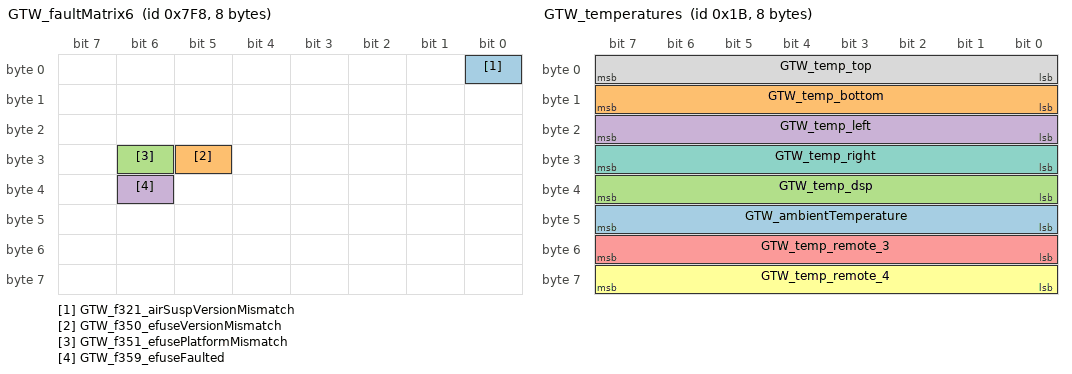
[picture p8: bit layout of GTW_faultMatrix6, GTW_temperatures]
BO_ 2040 GTW_faultMatrix6: 8 ETH
 SG_ GTW_f321_airSuspVersionMismatch: 0|1@1+ (1,0) [0|0] "" X
 SG_ GTW_f350_efuseVersionMismatch: 29|1@1+ (1,0) [0|0] "" X
 SG_ GTW_f351_efusePlatformMismatch: 30|1@1+ (1,0) [0|0] "" X
 SG_ GTW_f359_efuseFaulted: 38|1@1+ (1,0) [0|0] "" X

BO_ 49 GTW_gatewayStatus: 8 ETH
 SG_ GTW_accGoingDown: 0|1@1+ (1,0) [0|0] "" X
 SG_ GTW_accRailRequest: 4|1@1+ (1,0) [0|0] "" X
 SG_ GTW_bdyBusAsleep: 9|1@1+ (1,0) [0|0] "" X
 SG_ GTW_bftBusAsleep: 11|1@1+ (1,0) [0|0] "" X
 SG_ GTW_busesActive: 28|1@1+ (1,0) [0|0] "" X
 SG_ GTW_chBusAsleep: 13|1@1+ (1,0) [0|0] "" X
 SG_ GTW_charging: 7|1@1+ (1,0) [0|0] "" X
 SG_ GTW_diagBusAsleep: 8|1@1+ (1,0) [0|0] "" X
 SG_ GTW_diagDriveState: 29|3@1+ (1,0) [0|0] "" X
 SG_ GTW_driveRailRequest: 3|1@1+ (1,0) [0|0] "" X
 SG_ GTW_driverIsLeaving: 18|1@1+ (1,0) [0|0] "" X
 SG_ GTW_ethBusAsleep: 14|1@1+ (1,0) [0|0] "" X
 SG_ GTW_gsmPwrGood: 19|1@1+ (1,0) [0|0] "" X
 SG_ GTW_hvacGoingDown: 1|1@1+ (1,0) [0|0] "" X
 SG_ GTW_hvacRailRequest: 2|1@1+ (1,0) [0|0] "" X
 SG_ GTW_icWillBePoweredOff: 20|1@1+ (1,0) [0|0] "" X
 SG_ GTW_leftSeatHeaterOn: 15|1@1+ (1,0) [0|0] "" X
 SG_ GTW_mcuGoingDown: 17|1@1+ (1,0) [0|0] "" X
 SG_ GTW_preconditioningCabin: 5|1@1+ (1,0) [0|0] "" X
 SG_ GTW_preconditioningPack: 6|1@1+ (1,0) [0|0] "" X
 SG_ GTW_ptBusAsleep: 10|1@1+ (1,0) [0|0] "" X
 SG_ GTW_rearCenterSeatHeaterOn: 22|1@1+ (1,0) [0|0] "" X
 SG_ GTW_rearLeftSeatHeaterOn: 21|1@1+ (1,0) [0|0] "" X
 SG_ GTW_rearRightSeatHeaterOn: 23|1@1+ (1,0) [0|0] "" X
 SG_ GTW_rightSeatHeaterOn: 16|1@1+ (1,0) [0|0] "" X
 SG_ GTW_startingSleepAck: 26|1@1+ (1,0) [0|0] "" X
 SG_ GTW_statusChecksum: 56|8@1+ (1,0) [0|0] "" X
 SG_ GTW_statusCounter: 52|4@1+ (1,0) [0|0] "" X
 SG_ GTW_touchPower: 27|1@1+ (1,0) [0|0] "" X
 SG_ GTW_willBeGoingToSleep: 24|2@1+ (1,0) [0|0] "" X

BO_ 60 GTW_info: 8 ETH
 SG_ GTW_infoIndex M: 0|8@1+ (1,0) [0|0] "" X
 SG_ GTW_appGitHash0 m17: 8|8@1+ (1,0) [0|0] "" X
 SG_ GTW_appGitHash1 m17: 16|8@1+ (1,0) [0|0] "" X
 SG_ GTW_appGitHash2 m17: 24|8@1+ (1,0) [0|0] "" X
 SG_ GTW_appGitHash3 m17: 32|8@1+ (1,0) [0|0] "" X
 SG_ GTW_appGitHash4 m17: 40|8@1+ (1,0) [0|0] "" X
 SG_ GTW_appGitHash5 m17: 48|8@1+ (1,0) [0|0] "" X
 SG_ GTW_appGitHash6 m17: 56|8@1+ (1,0) [0|0] "" X
 SG_ GTW_buildType m10: 8|8@1+ (1,0) [0|0] "" X
 SG_ GTW_buildConfigID m10: 16|16@1+ (1,0) [0|0] "" X
 SG_ GTW_applicationCrc m13: 32|32@1+ (1,0) [0|0] "" X
 SG_ GTW_branchEnumId m21: 32|12@1+ (1,0) [0|0] "" X
 SG_ GTW_branchCommitCount m21: 44|20@1+ (1,0) [0|0] "" X

BO_ 776 GTW_odo_partial: 8 ETH
 SG_ GTW_easManualLevelRequest: 0|3@1+ (1,0) [0|0] "" X

BO_ 14 GTW_requests: 1 ETH
 SG_ GTW_timeRequest: 0|1@1+ (1,0) [0|0] "" X

BO_ 135 GTW_sleepDebug: 8 ETH
 SG_ GTW_bdyHadKeepWake: 1|1@1+ (1,0) [0|0] "" X
 SG_ GTW_chgWantsKeepAwake: 6|1@1+ (1,0) [0|0] "" X
 SG_ GTW_clusterState: 16|3@1+ (1,0) [0|0] "" X
 SG_ GTW_cpWantsKeepAwake: 7|1@1+ (1,0) [0|0] "" X
 SG_ GTW_ddmHadKeepWake: 2|1@1+ (1,0) [0|0] "" X
 SG_ GTW_delayMinutesRemaining: 48|8@1+ (1,0) [0|0] "min" X
 SG_ GTW_icOff: 13|1@1+ (1,0) [0|0] "" X
 SG_ GTW_keyPresent: 14|1@1+ (1,0) [0|0] "" X
 SG_ GTW_lftHadKeepWake: 4|1@1+ (1,0) [0|0] "" X
 SG_ GTW_mcuClusterInstantOn: 11|1@1+ (1,0) [0|0] "" X
 SG_ GTW_mcuGatewaySleepReq: 8|3@1+ (1,0) [0|0] "" X
 SG_ GTW_pdmHadKeepWake: 3|1@1+ (1,0) [0|0] "" X
 SG_ GTW_secHadKeepWake: 0|1@1+ (1,0) [0|0] "" X
 SG_ GTW_sleepInhibitedByXfer: 12|1@1+ (1,0) [0|0] "" X
 SG_ GTW_sunHadKeepWake: 5|1@1+ (1,0) [0|0] "" X
 SG_ GTW_updaterMinutesRemaining: 40|8@1+ (1,0) [0|0] "min" X
 SG_ GTW_updaterSleepDelay: 24|8@1+ (5,0) [0|0] "" X
 SG_ GTW_wouldSleep: 15|1@1+ (1,0) [0|0] "" X

BO_ 136 GTW_sleepDebug2: 8 ETH
 SG_ GTW_deepSleepMinutes: 32|14@0+ (1,0) [0|0] "" X
 SG_ GTW_lastUserAction: 0|32@0+ (1,0) [0|0] "secs" X
 SG_ GTW_mcuOff: 41|1@1+ (1,0) [0|0] "" X
 SG_ GTW_updaterChBusMinutesRemaining: 56|8@1+ (1,0) [0|0] "min" X
 SG_ GTW_updaterChBusSleepDelay: 48|8@1+ (5,0) [0|0] "" X
 SG_ GTW_wantDeepSleep: 40|1@1+ (1,0) [0|0] "" X

BO_ 2038 GTW_sleepDebug3: 4 ETH
 SG_ GTW_wakeupReason: 0|32@0+ (1,0) [0|0] "" X

BO_ 27 GTW_temperatures: 8 ETH
 SG_ GTW_ambientTemperature: 40|8@1+ (0.5,-40) [0|0] "degC" X
 SG_ GTW_temp_bottom: 8|8@1- (1,0) [0|0] "degC" X
 SG_ GTW_temp_dsp: 32|8@1- (1,0) [0|0] "deg C" X
 SG_ GTW_temp_left: 16|8@1- (1,0) [0|0] "deg C" X
 SG_ GTW_temp_remote_3: 48|8@1- (1,0) [0|0] "deg C" X
 SG_ GTW_temp_remote_4: 56|8@1- (1,0) [0|0] "deg C" X
 SG_ GTW_temp_right: 24|8@1- (1,0) [0|0] "degC" X
 SG_ GTW_temp_top: 0|8@1- (1,0) [0|0] "deg C" X

BO_ 10 GTW_timeResponse: 4 ETH
 SG_ GTW_timeSecs: 0|32@0+ (1,0) [0|0] "" X

BO_ 2028 GTW_toolResponse: 1 ETH
 SG_ GTW_progHLKResponse: 0|2@1+ (1,0) [0|0] "" X

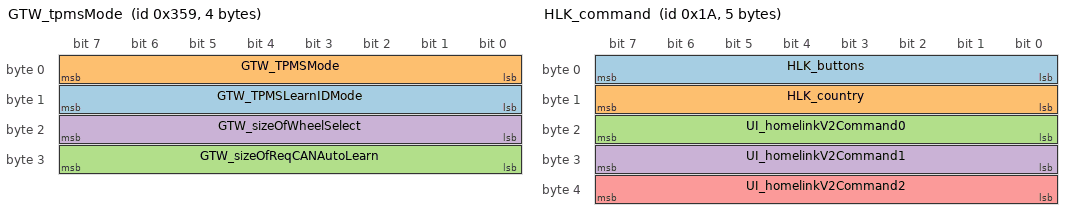
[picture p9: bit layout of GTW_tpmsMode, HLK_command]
BO_ 857 GTW_tpmsMode: 4 ETH
 SG_ GTW_TPMSLearnIDMode: 8|8@1+ (1,0) [0|0] "" X
 SG_ GTW_TPMSMode: 0|8@1+ (1,0) [0|0] "" X
 SG_ GTW_sizeOfReqCANAutoLearn: 24|8@1+ (1,0) [0|0] "" X
 SG_ GTW_sizeOfWheelSelect: 16|8@1+ (1,0) [0|0] "" X

BO_ 840 GTW_userMatrix1: 3 ETH
 SG_ GTW_u001_chgCableConnected: 0|1@1+ (1,0) [0|0] "" X
 SG_ GTW_u002_keyNotInside: 1|1@1+ (1,0) [0|0] "" X
 SG_ GTW_u003_bmsPower: 2|1@1+ (1,0) [0|0] "" X
 SG_ GTW_u004_unusedFwMismatch: 3|1@1+ (1,0) [0|0] "" X
 SG_ GTW_u005_dead12vBattery: 4|1@1+ (1,0) [0|0] "" X
 SG_ GTW_u006_cabinSocTooLow: 5|1@1+ (1,0) [0|0] "" X
 SG_ GTW_u007_cabinOpen: 6|1@1+ (1,0) [0|0] "" X
 SG_ GTW_u008_packSocTooLow: 7|1@1+ (1,0) [0|0] "" X
 SG_ GTW_u009_notEnough12VForDrive: 8|1@1+ (1,0) [0|0] "" X
 SG_ GTW_u010_low12VPower: 9|1@1+ (1,0) [0|0] "" X
 SG_ GTW_u011_replace12vBattery: 10|1@1+ (1,0) [0|0] "" X
 SG_ GTW_u012_parkToCharge: 11|1@1+ (1,0) [0|0] "" X
 SG_ GTW_u013_keyMissingInDrive: 12|1@1+ (1,0) [0|0] "" X
 SG_ GTW_u014_carInNeutral: 13|1@1+ (1,0) [0|0] "" X
 SG_ GTW_u015_displaysNotReady: 14|1@1+ (1,0) [0|0] "" X
 SG_ GTW_u016_driveDisabled: 15|1@1+ (1,0) [0|0] "" X
 SG_ GTW_u017_carInShowroomMode: 16|1@1+ (1,0) [0|0] "" X
 SG_ GTW_u018_efusesNotReady: 17|1@1+ (1,0) [0|0] "" X
 SG_ GTW_u019_overheatSocTooLow: 18|1@1+ (1,0) [0|0] "" X
 SG_ GTW_u020_ccFWUpdate: 19|1@1+ (1,0) [0|0] "" X
 SG_ GTW_u021_pinDisabledDrive: 20|1@1+ (1,0) [0|0] "" X

BO_ 59 GTW_version: 8 ETH
 SG_ GTW_componentHardwareRevision: 56|8@1+ (1,0) [0|0] "" X
 SG_ GTW_platformType: 0|8@1+ (1,0) [0|0] "" X

BO_ 62 GTW_warningMatrix1: 8 ETH
 SG_ GTW_w001_RSR_WDRS: 0|1@1+ (1,0) [0|0] "" X
 SG_ GTW_w002_cantWriteLogEntry: 1|1@1+ (1,0) [0|0] "" X
 SG_ GTW_w003_cantGetLogPoolEntry: 2|1@1+ (1,0) [0|0] "" X
 SG_ GTW_w004_RSR_PORS: 3|1@1+ (1,0) [0|0] "" X
 SG_ GTW_w005_RSR_ERS: 4|1@1+ (1,0) [0|0] "" X
 SG_ GTW_w006_RSR_LLRS: 5|1@1+ (1,0) [0|0] "" X
 SG_ GTW_w007_RSR_LCRS: 6|1@1+ (1,0) [0|0] "" X
 SG_ GTW_w008_RSR_CRS: 7|1@1+ (1,0) [0|0] "" X
 SG_ GTW_w010_sdCardFailed: 9|1@1+ (1,0) [0|0] "" X
 SG_ GTW_w011_thcVersionMismatch: 10|1@1+ (1,0) [0|0] "" X
 SG_ GTW_w012_bmsVersionMismatch: 11|1@1+ (1,0) [0|0] "" X
 SG_ GTW_w013_gtwVersionMismatch: 12|1@1+ (1,0) [0|0] "" X
 SG_ GTW_w014_diVersionMismatch: 13|1@1+ (1,0) [0|0] "" X
 SG_ GTW_w015_cpVersionMismatch: 14|1@1+ (1,0) [0|0] "" X
 SG_ GTW_w016_chgVersionMismatch: 15|1@1+ (1,0) [0|0] "" X
 SG_ GTW_w017_accLoadShed: 16|1@1+ (1,0) [0|0] "" X
 SG_ GTW_w018_hvacLoadShed: 17|1@1+ (1,0) [0|0] "" X
 SG_ GTW_w019_bmsMia: 18|1@1+ (1,0) [0|0] "" X
 SG_ GTW_w020_diMia: 19|1@1+ (1,0) [0|0] "" X
 SG_ GTW_w021_thcMia: 20|1@1+ (1,0) [0|0] "" X
 SG_ GTW_w022_dcdcMia: 21|1@1+ (1,0) [0|0] "" X
 SG_ GTW_w023_chgMia: 22|1@1+ (1,0) [0|0] "" X
 SG_ GTW_w024_chgsMia: 23|1@1+ (1,0) [0|0] "" X
 SG_ GTW_w025_easMia: 24|1@1+ (1,0) [0|0] "" X
 SG_ GTW_w026_ibsMia: 25|1@1+ (1,0) [0|0] "" X
 SG_ GTW_w027_epbMia: 26|1@1+ (1,0) [0|0] "" X
 SG_ GTW_w028_chgsVersionMismatch: 27|1@1+ (1,0) [0|0] "" X
 SG_ GTW_w029_bdyMia: 28|1@1+ (1,0) [0|0] "" X
 SG_ GTW_w030_ddmMia: 29|1@1+ (1,0) [0|0] "" X
 SG_ GTW_w031_lftMia: 30|1@1+ (1,0) [0|0] "" X
 SG_ GTW_w032_pdmMia: 31|1@1+ (1,0) [0|0] "" X
 SG_ GTW_w033_secMia: 32|1@1+ (1,0) [0|0] "" X
 SG_ GTW_w034_sunMia: 33|1@1+ (1,0) [0|0] "" X
 SG_ GTW_w035_tunerMia: 34|1@1+ (1,0) [0|0] "" X
 SG_ GTW_w036_epasMia: 35|1@1+ (1,0) [0|0] "" X
 SG_ GTW_w037_espMia: 36|1@1+ (1,0) [0|0] "" X
 SG_ GTW_w038_icMia: 37|1@1+ (1,0) [0|0] "" X
 SG_ GTW_w039_sccmMia: 38|1@1+ (1,0) [0|0] "" X
 SG_ GTW_w040_msmMia: 39|1@1+ (1,0) [0|0] "" X
 SG_ GTW_w041_ptcMia: 40|1@1+ (1,0) [0|0] "" X
 SG_ GTW_w042_cpMia: 41|1@1+ (1,0) [0|0] "" X
 SG_ GTW_w043_pmMia: 42|1@1+ (1,0) [0|0] "" X
 SG_ GTW_w044_tpmsMia: 43|1@1+ (1,0) [0|0] "" X
 SG_ GTW_w045_rccmMia: 44|1@1+ (1,0) [0|0] "" X
 SG_ GTW_w046_mcuMia: 45|1@1+ (1,0) [0|0] "" X
 SG_ GTW_w047_leftShMia: 46|1@1+ (1,0) [0|0] "" X
 SG_ GTW_w048_rightShMia: 47|1@1+ (1,0) [0|0] "" X
 SG_ GTW_w049_homelinkMia: 48|1@1+ (1,0) [0|0] "" X
 SG_ GTW_w050_rvMirrorMia: 49|1@1+ (1,0) [0|0] "" X
 SG_ GTW_w051_thcPlatformMismatch: 50|1@1+ (1,0) [0|0] "" X
 SG_ GTW_w052_bmsPlatformMismatch: 51|1@1+ (1,0) [0|0] "" X
 SG_ GTW_w053_gtwPlatformMismatch: 52|1@1+ (1,0) [0|0] "" X
 SG_ GTW_w054_diPlatformMismatch: 53|1@1+ (1,0) [0|0] "" X
 SG_ GTW_w055_cpPlatformMismatch: 54|1@1+ (1,0) [0|0] "" X
 SG_ GTW_w056_chgPlatformMismatch: 55|1@1+ (1,0) [0|0] "" X
 SG_ GTW_w057_chgsPlatformMismatch: 56|1@1+ (1,0) [0|0] "" X
 SG_ GTW_w058_stwMia: 57|1@1+ (1,0) [0|0] "" X
 SG_ GTW_w059_stackOverflow: 58|1@1+ (1,0) [0|0] "" X
 SG_ GTW_w060_hvacRailNotOn: 59|1@1+ (1,0) [0|0] "" X
 SG_ GTW_w061_hvacRailTooLow: 60|1@1+ (1,0) [0|0] "" X
 SG_ GTW_w062_hvacRailOV: 61|1@1+ (1,0) [0|0] "" X
 SG_ GTW_w063_unknownMsg: 62|1@1+ (1,0) [0|0] "" X
 SG_ GTW_w064_canOverrun: 63|1@1+ (1,0) [0|0] "" X

BO_ 1432 GTW_warningMatrix2: 8 ETH
 SG_ GTW_w065_msgChecksumMismatch: 0|1@1+ (1,0) [0|0] "" X
 SG_ GTW_w066_canBusOff: 1|1@1+ (1,0) [0|0] "" X
 SG_ GTW_w067_missingFirmwareRc: 2|1@1+ (1,0) [0|0] "" X
 SG_ GTW_w068_can0BusOff: 3|1@1+ (1,0) [0|0] "" X
 SG_ GTW_w069_can1BusOff: 4|1@1+ (1,0) [0|0] "" X
 SG_ GTW_w070_can2BusOff: 5|1@1+ (1,0) [0|0] "" X
 SG_ GTW_w071_can3BusOff: 6|1@1+ (1,0) [0|0] "" X
 SG_ GTW_w072_can4BusOff: 7|1@1+ (1,0) [0|0] "" X
 SG_ GTW_w073_can5BusOff: 8|1@1+ (1,0) [0|0] "" X
 SG_ GTW_w074_can0Errors: 9|1@1+ (1,0) [0|0] "" X
 SG_ GTW_w075_can1Errors: 10|1@1+ (1,0) [0|0] "" X
 SG_ GTW_w076_can2Errors: 11|1@1+ (1,0) [0|0] "" X
 SG_ GTW_w077_can3Errors: 12|1@1+ (1,0) [0|0] "" X
 SG_ GTW_w078_can4Errors: 13|1@1+ (1,0) [0|0] "" X
 SG_ GTW_w079_can5Errors: 14|1@1+ (1,0) [0|0] "" X
 SG_ GTW_w080_appCrcError: 15|1@1+ (1,0) [0|0] "" X
 SG_ GTW_w081_disVersionMismatch: 16|1@1+ (1,0) [0|0] "" X
 SG_ GTW_w083_disMia: 18|1@1+ (1,0) [0|0] "" X
 SG_ GTW_w084_pmVersionMismatch: 19|1@1+ (1,0) [0|0] "" X
 SG_ GTW_w086_mcuLoadShed: 21|1@1+ (1,0) [0|0] "" X
 SG_ GTW_w087_mcuPowerOff: 22|1@1+ (1,0) [0|0] "" X
 SG_ GTW_w088_hwidMismatch: 23|1@1+ (1,0) [0|0] "" X
 SG_ GTW_w089_canTxOverflow: 24|1@1+ (1,0) [0|0] "" X
 SG_ GTW_w090_powerUpTimeout: 25|1@1+ (1,0) [0|0] "" X
 SG_ GTW_w091_mfgDataCrcError: 26|1@1+ (1,0) [0|0] "" X
 SG_ GTW_w092_icTegraMia: 27|1@1+ (1,0) [0|0] "" X
 SG_ GTW_w093_secReset: 28|1@1+ (1,0) [0|0] "" X
 SG_ GTW_w099_epbmMia: 34|1@1+ (1,0) [0|0] "" X
 SG_ GTW_w100_epbVersionMismatch: 35|1@1+ (1,0) [0|0] "" X
 SG_ GTW_w101_epbPlatformMismatch: 36|1@1+ (1,0) [0|0] "" X
 SG_ GTW_w102_epbmVersionMismatch: 37|1@1+ (1,0) [0|0] "" X
 SG_ GTW_w103_epbmPlatformMismatch: 38|1@1+ (1,0) [0|0] "" X
 SG_ GTW_w104_ocsMia: 39|1@1+ (1,0) [0|0] "" X
 SG_ GTW_w105_rcmMia: 40|1@1+ (1,0) [0|0] "" X
 SG_ GTW_w106_espVersionMismatch: 41|1@1+ (1,0) [0|0] "" X
 SG_ GTW_w107_1HzTaskTooLong: 42|1@1+ (1,0) [0|0] "" X
 SG_ GTW_w108_10HzTaskTooLong: 43|1@1+ (1,0) [0|0] "" X
 SG_ GTW_w109_100HzTaskTooLong: 44|1@1+ (1,0) [0|0] "" X
 SG_ GTW_w110_can0BusOverload: 45|1@1+ (1,0) [0|0] "" X
 SG_ GTW_w111_can1BusOverload: 46|1@1+ (1,0) [0|0] "" X
 SG_ GTW_w112_can2BusOverload: 47|1@1+ (1,0) [0|0] "" X
 SG_ GTW_w113_can3BusOverload: 48|1@1+ (1,0) [0|0] "" X
 SG_ GTW_w114_can4BusOverload: 49|1@1+ (1,0) [0|0] "" X
 SG_ GTW_w115_can5BusOverload: 50|1@1+ (1,0) [0|0] "" X
 SG_ GTW_w116_mediaPwrError: 51|1@1+ (1,0) [0|0] "" X
 SG_ GTW_w117_tegraPwrError: 52|1@1+ (1,0) [0|0] "" X
 SG_ GTW_w118_5vMediaPwrError: 53|1@1+ (1,0) [0|0] "" X
 SG_ GTW_w119_dspOverTemp: 54|1@1+ (1,0) [0|0] "" X
 SG_ GTW_w120_cantPreconditionSocSna: 55|1@1+ (1,0) [0|0] "" X
 SG_ GTW_w121_touchCableFault: 56|1@1+ (1,0) [0|0] "" X
 SG_ GTW_w122_bmsNotSupporting12V: 57|1@1+ (1,0) [0|0] "" X
 SG_ GTW_w123_messageCounterMismatch: 58|1@1+ (1,0) [0|0] "" X
 SG_ GTW_w124_logOffsetIncorrect: 59|1@1+ (1,0) [0|0] "" X
 SG_ GTW_w125_dcdcVersionMismatch: 60|1@1+ (1,0) [0|0] "" X
 SG_ GTW_w126_icVersionMismatch: 61|1@1+ (1,0) [0|0] "" X
 SG_ GTW_w127_epasVersionMismatch: 62|1@1+ (1,0) [0|0] "" X
 SG_ GTW_w128_msmVersionMismatch: 63|1@1+ (1,0) [0|0] "" X

BO_ 1464 GTW_warningMatrix3: 8 ETH
 SG_ GTW_w129_ptcVersionMismatch: 0|1@1+ (1,0) [0|0] "" X
 SG_ GTW_w130_rccmVersionMismatch: 1|1@1+ (1,0) [0|0] "" X
 SG_ GTW_w131_tunerVersionMismatch: 2|1@1+ (1,0) [0|0] "" X
 SG_ GTW_w132_tunerDspVersionMismatch: 3|1@1+ (1,0) [0|0] "" X
 SG_ GTW_w133_tunerCalVersionMismatch: 4|1@1+ (1,0) [0|0] "" X
 SG_ GTW_w134_secVersionMismatch: 5|1@1+ (1,0) [0|0] "" X
 SG_ GTW_w135_bcVersionMismatch: 6|1@1+ (1,0) [0|0] "" X
 SG_ GTW_w136_sunVersionMismatch: 7|1@1+ (1,0) [0|0] "" X
 SG_ GTW_w137_lftVersionMismatch: 8|1@1+ (1,0) [0|0] "" X
 SG_ GTW_w138_ddmVersionMismatch: 9|1@1+ (1,0) [0|0] "" X
 SG_ GTW_w139_pdmVersionMismatch: 10|1@1+ (1,0) [0|0] "" X
 SG_ GTW_w140_hndfdVersionMismatch: 11|1@1+ (1,0) [0|0] "" X
 SG_ GTW_w141_hndrdVersionMismatch: 12|1@1+ (1,0) [0|0] "" X
 SG_ GTW_w142_hndfpVersionMismatch: 13|1@1+ (1,0) [0|0] "" X
 SG_ GTW_w143_hndrpVersionMismatch: 14|1@1+ (1,0) [0|0] "" X
 SG_ GTW_w145_unableToSetRtcAlarm: 16|1@1+ (1,0) [0|0] "" X
 SG_ GTW_w146_unableToReadRtc: 17|1@1+ (1,0) [0|0] "" X
 SG_ GTW_w147_sdCardFilesysError: 18|1@1+ (1,0) [0|0] "" X
 SG_ GTW_w148_fileCrcBad: 19|1@1+ (1,0) [0|0] "" X
 SG_ GTW_w149_usingBackupConfig: 20|1@1+ (1,0) [0|0] "" X
 SG_ GTW_w150_missingConfig: 21|1@1+ (1,0) [0|0] "" X
 SG_ GTW_w151_badConfigValue: 22|1@1+ (1,0) [0|0] "" X
 SG_ GTW_w152_headlightLevelerMia: 23|1@1+ (1,0) [0|0] "" X
 SG_ GTW_w153_blowerFault: 24|1@1+ (1,0) [0|0] "" X
 SG_ GTW_w154_fan1Fault: 25|1@1+ (1,0) [0|0] "" X
 SG_ GTW_w155_fan2Fault: 26|1@1+ (1,0) [0|0] "" X
 SG_ GTW_w156_12VAhThreshNotReached: 27|1@1+ (1,0) [0|0] "" X
 SG_ GTW_w157_12VThermalRunaway: 28|1@1+ (1,0) [0|0] "" X
 SG_ GTW_w158_12VOvercharge: 29|1@1+ (1,0) [0|0] "" X
 SG_ GTW_w159_12VChgNotTapering: 30|1@1+ (1,0) [0|0] "" X
 SG_ GTW_w160_crashDetected: 31|1@1+ (1,0) [0|0] "" X
 SG_ GTW_w161_chgPh1Mia: 32|1@1+ (1,0) [0|0] "" X
 SG_ GTW_w162_chgPh2Mia: 33|1@1+ (1,0) [0|0] "" X
 SG_ GTW_w163_chgPh3Mia: 34|1@1+ (1,0) [0|0] "" X
 SG_ GTW_w164_chgsPh1Mia: 35|1@1+ (1,0) [0|0] "" X
 SG_ GTW_w165_chgsPh2Mia: 36|1@1+ (1,0) [0|0] "" X
 SG_ GTW_w166_chgsPh3Mia: 37|1@1+ (1,0) [0|0] "" X
 SG_ GTW_w167_rearLeftShMia: 38|1@1+ (1,0) [0|0] "" X
 SG_ GTW_w168_rearCenterShMia: 39|1@1+ (1,0) [0|0] "" X
 SG_ GTW_w169_rearRightShMia: 40|1@1+ (1,0) [0|0] "" X
 SG_ GTW_w170_parkAssistMia: 41|1@1+ (1,0) [0|0] "" X
 SG_ GTW_w171_blindSpotMia: 42|1@1+ (1,0) [0|0] "" X
 SG_ GTW_w172_ibsCommError: 43|1@1+ (1,0) [0|0] "" X
 SG_ GTW_w173_low12VCapacity: 44|1@1+ (1,0) [0|0] "" X
 SG_ GTW_w174_Replace12VBattery: 45|1@1+ (1,0) [0|0] "" X
 SG_ GTW_w175_low12VPower: 46|1@1+ (1,0) [0|0] "" X
 SG_ GTW_w176_notEnough12VForDrive: 47|1@1+ (1,0) [0|0] "" X
 SG_ GTW_w177_dead12VBattery: 48|1@1+ (1,0) [0|0] "" X
 SG_ GTW_w178_driveRailMismatch: 49|1@1+ (1,0) [0|0] "" X
 SG_ GTW_w179_accRailMismatch: 50|1@1+ (1,0) [0|0] "" X
 SG_ GTW_w180_hvacRailMismatch: 51|1@1+ (1,0) [0|0] "" X
 SG_ GTW_w181_parkAssistSystemDTC: 52|1@1+ (1,0) [0|0] "" X
 SG_ GTW_w182_parkAssistFailure: 53|1@1+ (1,0) [0|0] "" X
 SG_ GTW_w183_dfHndMia: 54|1@1+ (1,0) [0|0] "" X
 SG_ GTW_w184_drHndMia: 55|1@1+ (1,0) [0|0] "" X
 SG_ GTW_w185_pfHndMia: 56|1@1+ (1,0) [0|0] "" X
 SG_ GTW_w186_prHndMia: 57|1@1+ (1,0) [0|0] "" X
 SG_ GTW_w187_chgph1PlatformMismatch: 58|1@1+ (1,0) [0|0] "" X
 SG_ GTW_w188_chgph2PlatformMismatch: 59|1@1+ (1,0) [0|0] "" X
 SG_ GTW_w189_chgph3PlatformMismatch: 60|1@1+ (1,0) [0|0] "" X
 SG_ GTW_w190_chgsph1PlatformMismatch: 61|1@1+ (1,0) [0|0] "" X
 SG_ GTW_w191_chgsph2PlatformMismatch: 62|1@1+ (1,0) [0|0] "" X
 SG_ GTW_w192_chgsph3PlatformMismatch: 63|1@1+ (1,0) [0|0] "" X

BO_ 1480 GTW_warningMatrix4: 8 ETH
 SG_ GTW_w193_chgph1VersionMismatch: 0|1@1+ (1,0) [0|0] "" X
 SG_ GTW_w194_chgph2VersionMismatch: 1|1@1+ (1,0) [0|0] "" X
 SG_ GTW_w195_chgph3VersionMismatch: 2|1@1+ (1,0) [0|0] "" X
 SG_ GTW_w199_chgsph1VersionMismatch: 6|1@1+ (1,0) [0|0] "" X
 SG_ GTW_w200_chgsph2VersionMismatch: 7|1@1+ (1,0) [0|0] "" X
 SG_ GTW_w201_chgsph3VersionMismatch: 8|1@1+ (1,0) [0|0] "" X
 SG_ GTW_w206_parkAssistVersMismatch: 13|1@1+ (1,0) [0|0] "" X
 SG_ GTW_w207_debugTaskMismatch: 14|1@1+ (1,0) [0|0] "" X
 SG_ GTW_w211_leftShFailure: 18|1@1+ (1,0) [0|0] "" X
 SG_ GTW_w212_rightShFailure: 19|1@1+ (1,0) [0|0] "" X
 SG_ GTW_w213_rearLeftShFailure: 20|1@1+ (1,0) [0|0] "" X
 SG_ GTW_w214_rearCenterShFailure: 21|1@1+ (1,0) [0|0] "" X
 SG_ GTW_w215_rearRightShFailure: 22|1@1+ (1,0) [0|0] "" X
 SG_ GTW_w216_assert: 23|1@1+ (1,0) [0|0] "" X
 SG_ GTW_w217_hlkCommError: 24|1@1+ (1,0) [0|0] "" X
 SG_ GTW_w218_airbagIndicator: 25|1@1+ (1,0) [0|0] "" X
 SG_ GTW_w219_ethRxOverflow: 26|1@1+ (1,0) [0|0] "" X
 SG_ GTW_w220_fileVersionMismatch: 27|1@1+ (1,0) [0|0] "" X
 SG_ GTW_w221_RSR_WDRS_SLEEP: 28|1@1+ (1,0) [0|0] "" X
 SG_ GTW_w222_tpmsPressThrWriteFailed: 29|1@1+ (1,0) [0|0] "" X
 SG_ GTW_w223_tunerDabVersionMismatch: 30|1@1+ (1,0) [0|0] "" X
 SG_ GTW_w224_msmProblem: 31|1@1+ (1,0) [0|0] "" X
 SG_ GTW_w225_sdOrLogIssue: 32|1@1+ (1,0) [0|0] "" X
 SG_ GTW_w226_airSuspVersionMismatch: 33|1@1+ (1,0) [0|0] "" X
 SG_ GTW_w229_cmpVersionMismatch: 36|1@1+ (1,0) [0|0] "" X
 SG_ GTW_w230_cmpMia: 37|1@1+ (1,0) [0|0] "" X
 SG_ GTW_w231_pmsVersionMismatch: 38|1@1+ (1,0) [0|0] "" X
 SG_ GTW_w233_pmsMia: 40|1@1+ (1,0) [0|0] "" X
 SG_ GTW_w234_chBusErrors: 41|1@1+ (1,0) [0|0] "" X
 SG_ GTW_w235_tpmsEolIncomplete: 42|1@1+ (1,0) [0|0] "" X
 SG_ GTW_w237_caughtException: 44|1@1+ (1,0) [0|0] "" X
 SG_ GTW_w238_ethernetReset: 45|1@1+ (1,0) [0|0] "" X
 SG_ GTW_w239_12VOvertemp: 46|1@1+ (1,0) [0|0] "" X
 SG_ GTW_w240_ethRxSoftOverflow: 47|1@1+ (1,0) [0|0] "" X
 SG_ GTW_w241_dasVersionMismatch: 48|1@1+ (1,0) [0|0] "" X
 SG_ GTW_w242_dasMia: 49|1@1+ (1,0) [0|0] "" X
 SG_ GTW_w246_espCalVersionMismatch: 53|1@1+ (1,0) [0|0] "" X
 SG_ GTW_w247_tpmsVersionMismatch: 54|1@1+ (1,0) [0|0] "" X
 SG_ GTW_w248_bccenVersionMismatch: 55|1@1+ (1,0) [0|0] "" X
 SG_ GTW_w249_bcfdmVersionMismatch: 56|1@1+ (1,0) [0|0] "" X
 SG_ GTW_w250_bcfrontVersionMismatch: 57|1@1+ (1,0) [0|0] "" X
 SG_ GTW_w251_bcrdmVersionMismatch: 58|1@1+ (1,0) [0|0] "" X
 SG_ GTW_w252_bcrearVersionMismatch: 59|1@1+ (1,0) [0|0] "" X
 SG_ GTW_w253_radcVersionMismatch: 60|1@1+ (1,0) [0|0] "" X

BO_ 2008 GTW_warningMatrix5: 8 ETH
 SG_ GTW_w260_isEbuck: 3|1@1+ (1,0) [0|0] "" X
 SG_ GTW_w261_updateWhatYouSee: 4|1@1+ (1,0) [0|0] "" X
 SG_ GTW_w263_bcrdmMia: 6|1@1+ (1,0) [0|0] "" X
 SG_ GTW_w264_bcrearMia: 7|1@1+ (1,0) [0|0] "" X
 SG_ GTW_w265_ibstMia: 8|1@1+ (1,0) [0|0] "" X
 SG_ GTW_w266_ibstVersionMismatch: 9|1@1+ (1,0) [0|0] "" X
 SG_ GTW_w267_ibstCalMismatch: 10|1@1+ (1,0) [0|0] "" X
 SG_ GTW_w268_ibstFailure: 11|1@1+ (1,0) [0|0] "" X
 SG_ GTW_w269_pedProEvent: 12|1@1+ (1,0) [0|0] "" X
 SG_ GTW_w270_bootSectorRepaired: 13|1@1+ (1,0) [0|0] "" X
 SG_ GTW_w271_bootSectorCorrupted: 14|1@1+ (1,0) [0|0] "" X
 SG_ GTW_w272_chgrlyPlatformMismatch: 15|1@1+ (1,0) [0|0] "" X
 SG_ GTW_w273_chgrlyVersionMismatch: 16|1@1+ (1,0) [0|0] "" X
 SG_ GTW_w274_touchPowerOCFault: 17|1@1+ (1,0) [0|0] "" X
 SG_ GTW_w275_unableToChg12V: 18|1@1+ (1,0) [0|0] "" X
 SG_ GTW_w276_bdwActivated: 19|1@1+ (1,0) [0|0] "" X
 SG_ GTW_w277_iBoosterReduced: 20|1@1+ (1,0) [0|0] "" X
 SG_ GTW_w279_bcfpmVersionMismatch: 22|1@1+ (1,0) [0|0] "" X
 SG_ GTW_w281_bcrpmVersionMismatch: 24|1@1+ (1,0) [0|0] "" X
 SG_ GTW_w283_bcs2lVersionMismatch: 26|1@1+ (1,0) [0|0] "" X
 SG_ GTW_w285_bcs2cVersionMismatch: 28|1@1+ (1,0) [0|0] "" X
 SG_ GTW_w287_bcs2rVersionMismatch: 30|1@1+ (1,0) [0|0] "" X
 SG_ GTW_w289_bcfalcdVersionMismatch: 32|1@1+ (1,0) [0|0] "" X
 SG_ GTW_w290_parkAssistTempFailure: 33|1@1+ (1,0) [0|0] "" X
 SG_ GTW_w291_tunerHdVersionMismatch: 34|1@1+ (1,0) [0|0] "" X
 SG_ GTW_w292_firmwareRcIncomplete: 35|1@1+ (1,0) [0|0] "" X
 SG_ GTW_w297_rcmAirbagsNotArmed: 40|1@1+ (1,0) [0|0] "" X
 SG_ GTW_w299_thBusConfigMismatch: 42|1@1+ (1,0) [0|0] "" X
 SG_ GTW_w301_msmpVersionMismatch: 44|1@1+ (1,0) [0|0] "" X
 SG_ GTW_w303_msmpMia: 46|1@1+ (1,0) [0|0] "" X
 SG_ GTW_w304_ptcrVersionMismatch: 47|1@1+ (1,0) [0|0] "" X
 SG_ GTW_w305_ptcrMia: 48|1@1+ (1,0) [0|0] "" X
 SG_ GTW_w308_rcmNearDeploy: 51|1@1+ (1,0) [0|0] "" X
 SG_ GTW_w309_bcrpmMia: 52|1@1+ (1,0) [0|0] "" X
 SG_ GTW_w310_bcfalcdMia: 53|1@1+ (1,0) [0|0] "" X
 SG_ GTW_w311_bcfalcpMia: 54|1@1+ (1,0) [0|0] "" X
 SG_ GTW_w312_bcs2lMia: 55|1@1+ (1,0) [0|0] "" X
 SG_ GTW_w313_bcs2cMia: 56|1@1+ (1,0) [0|0] "" X
 SG_ GTW_w314_bcs2rMia: 57|1@1+ (1,0) [0|0] "" X
 SG_ GTW_w317_bcfalcpVersionMismatch: 60|1@1+ (1,0) [0|0] "" X
 SG_ GTW_w318_rcmDriverOrientMismatch: 61|1@1+ (1,0) [0|0] "" X
 SG_ GTW_w319_contactorImpedance: 62|1@1+ (1,0) [0|0] "" X
 SG_ GTW_w320_airSuspPlatformMismatch: 63|1@1+ (1,0) [0|0] "" X

BO_ 2024 GTW_warningMatrix6: 8 ETH
 SG_ GTW_w321_airSuspVersionMismatch: 0|1@1+ (1,0) [0|0] "" X
 SG_ GTW_w326_snscll1VersionMismatch: 5|1@1+ (1,0) [0|0] "" X
 SG_ GTW_w327_snscll1PlatformMismatch: 6|1@1+ (1,0) [0|0] "" X
 SG_ GTW_w328_snsclr1VersionMismatch: 7|1@1+ (1,0) [0|0] "" X
 SG_ GTW_w329_snsclr1PlatformMismatch: 8|1@1+ (1,0) [0|0] "" X
 SG_ GTW_w330_snscul1VersionMismatch: 9|1@1+ (1,0) [0|0] "" X
 SG_ GTW_w331_snscul1PlatformMismatch: 10|1@1+ (1,0) [0|0] "" X
 SG_ GTW_w332_snscur1VersionMismatch: 11|1@1+ (1,0) [0|0] "" X
 SG_ GTW_w333_snscur1PlatformMismatch: 12|1@1+ (1,0) [0|0] "" X
 SG_ GTW_w334_msmdMia: 13|1@1+ (1,0) [0|0] "" X
 SG_ GTW_w335_bccenMia: 14|1@1+ (1,0) [0|0] "" X
 SG_ GTW_w336_bcfdmMia: 15|1@1+ (1,0) [0|0] "" X
 SG_ GTW_w337_bcfrontMia: 16|1@1+ (1,0) [0|0] "" X
 SG_ GTW_w338_bcfpmMia: 17|1@1+ (1,0) [0|0] "" X
 SG_ GTW_w339_LTEnPwrIndFault: 18|1@1+ (1,0) [0|0] "" X
 SG_ GTW_w340_12VTooMuchDischarge: 19|1@1+ (1,0) [0|0] "" X
 SG_ GTW_w341_blebaseVersionMismatch: 20|1@1+ (1,0) [0|0] "" X
 SG_ GTW_w342_snsusVersionMismatch: 21|1@1+ (1,0) [0|0] "" X
 SG_ GTW_w343_frunkLatchFailure: 22|1@1+ (1,0) [0|0] "" X
 SG_ GTW_w344_micSenseFailure: 23|1@1+ (1,0) [0|0] "" X
 SG_ GTW_w345_cmd8SigFailure: 24|1@1+ (1,0) [0|0] "" X
 SG_ GTW_w346_canInject: 25|1@1+ (1,0) [0|0] "" X
 SG_ GTW_w347_ethRxBufHighwater: 26|1@1+ (1,0) [0|0] "" X
 SG_ GTW_w349_efuseMia: 28|1@1+ (1,0) [0|0] "" X
 SG_ GTW_w350_efuseVersionMismatch: 29|1@1+ (1,0) [0|0] "" X
 SG_ GTW_w351_efusePlatformMismatch: 30|1@1+ (1,0) [0|0] "" X
 SG_ GTW_w352_epas3sMia: 31|1@1+ (1,0) [0|0] "" X
 SG_ GTW_w353_epas3sVersionMismatch: 32|1@1+ (1,0) [0|0] "" X
 SG_ GTW_w354_epas3pMia: 33|1@1+ (1,0) [0|0] "" X
 SG_ GTW_w355_apsMia: 34|1@1+ (1,0) [0|0] "" X
 SG_ GTW_w357_epas3pVersionMismatch: 36|1@1+ (1,0) [0|0] "" X
 SG_ GTW_w358_unlockRequiredForStart: 37|1@1+ (1,0) [0|0] "" X
 SG_ GTW_w360_espHfcActive: 39|1@1+ (1,0) [0|0] "" X
 SG_ GTW_w361_bdwCompromised: 40|1@1+ (1,0) [0|0] "" X
 SG_ GTW_w363_powerQueueFull: 42|1@1+ (1,0) [0|0] "" X
 SG_ GTW_w364_shutdownMcuBlocked: 43|1@1+ (1,0) [0|0] "" X
 SG_ GTW_w365_bmpPmicError: 44|1@1+ (1,0) [0|0] "" X
 SG_ GTW_w366_12VChgVReduced: 45|1@1+ (1,0) [0|0] "" X
 SG_ GTW_w370_noLVSupportSocTooLow: 46|1@1+ (1,0) [0|0] "" X
 SG_ GTW_w371_bmpWatchdog: 47|1@1+ (1,0) [0|0] "" X
 SG_ GTW_w372_ccFWUpdateFailure: 48|1@1+ (1,0) [0|0] "" X
 SG_ GTW_w373_unFused: 49|1@1+ (1,0) [0|0] "" X
 SG_ GTW_w374_inFactoryMode: 50|1@1+ (1,0) [0|0] "" X
 SG_ GTW_w375_readMdioFailed: 51|1@1+ (1,0) [0|0] "" X
 SG_ GTW_w376_writeMdioFailed: 52|1@1+ (1,0) [0|0] "" X
 SG_ GTW_w377_switchWatchdog: 53|1@1+ (1,0) [0|0] "" X
 SG_ GTW_w378_switchInitFailed: 54|1@1+ (1,0) [0|0] "" X

BO_ 26 HLK_command: 5 ETH
 SG_ HLK_buttons: 0|8@1+ (1,0) [0|0] "" X
 SG_ HLK_country: 8|8@1+ (1,0) [0|0] "" X
 SG_ UI_homelinkV2Command0: 16|8@1+ (1,0) [0|0] "" X
 SG_ UI_homelinkV2Command1: 24|8@1+ (1,0) [0|0] "" X
 SG_ UI_homelinkV2Command2: 32|8@1+ (1,0) [0|0] "" X

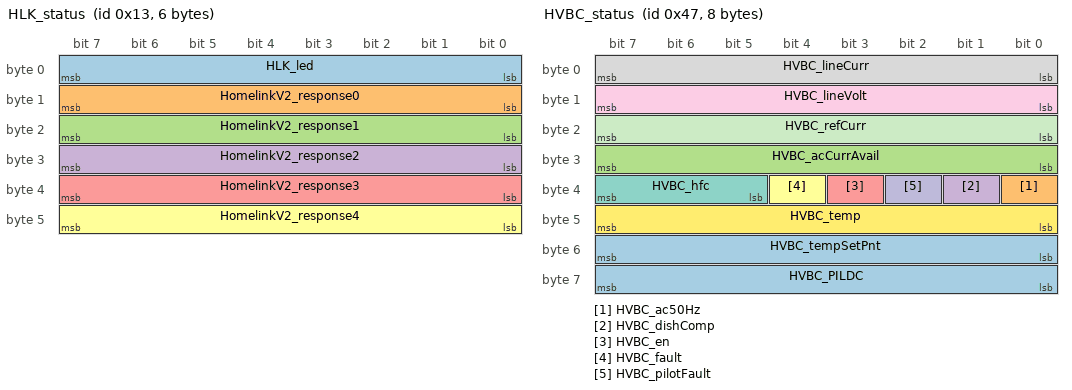
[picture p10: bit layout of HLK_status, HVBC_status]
BO_ 19 HLK_status: 6 ETH
 SG_ HLK_led: 0|8@1+ (1,0) [0|0] "" X
 SG_ HomelinkV2_response0: 8|8@1+ (1,0) [0|0] "" X
 SG_ HomelinkV2_response1: 16|8@1+ (1,0) [0|0] "" X
 SG_ HomelinkV2_response2: 24|8@1+ (1,0) [0|0] "" X
 SG_ HomelinkV2_response3: 32|8@1+ (1,0) [0|0] "" X
 SG_ HomelinkV2_response4: 40|8@1+ (1,0) [0|0] "" X

BO_ 71 HVBC_status: 8 ETH
 SG_ HVBC_PILDC: 56|8@1+ (1,0) [0|0] "%" X
 SG_ HVBC_ac50Hz: 32|1@1+ (1,0) [0|0] "" X
 SG_ HVBC_acCurrAvail: 24|8@1+ (0.125,0) [0|0] "A" X
 SG_ HVBC_dishComp: 33|1@1+ (1,0) [0|0] "" X
 SG_ HVBC_en: 35|1@1+ (1,0) [0|0] "" X
 SG_ HVBC_fault: 36|1@1+ (1,0) [0|0] "" X
 SG_ HVBC_hfc: 37|3@1+ (1,0) [0|0] "" X
 SG_ HVBC_lineCurr: 0|8@1+ (0.125,0) [0|0] "A" X
 SG_ HVBC_lineVolt: 8|8@1+ (1.17188,0) [0|0] "V" X
 SG_ HVBC_pilotFault: 34|1@1+ (1,0) [0|0] "" X
 SG_ HVBC_refCurr: 16|8@1+ (0.125,0) [0|0] "A" X
 SG_ HVBC_temp: 40|8@1- (0.625,0) [0|0] "C" X
 SG_ HVBC_tempSetPnt: 48|8@1- (0.625,0) [0|0] "C" X

BO_ 1551 HVBS_udsResponse: 8 ETH
 SG_ HVBS_udsResponseData: 0|54@0+ (1024,0) [0|0] "" X

BO_ 861 IBST_dtcMatrix: 8 ETH
 SG_ IBST_dtcIndex M: 0|8@1+ (1,0) [0|0] "" X
 SG_ IBST_d000_bmsInitTestFail m0: 8|2@1+ (1,0) [0|0] "" X
 SG_ IBST_d001_bmcSingleTransTest m0: 10|2@1+ (1,0) [0|0] "" X
 SG_ IBST_d002_tle5012SsccrcFail m0: 12|2@1+ (1,0) [0|0] "" X
 SG_ IBST_d003_tle5012Config m0: 14|2@1+ (1,0) [0|0] "" X
 SG_ IBST_d004_deadlMonTaskx1Ovr m0: 16|2@1+ (1,0) [0|0] "" X
 SG_ IBST_d005_ecuWdFltCntTstFls m0: 18|2@1+ (1,0) [0|0] "" X
 SG_ IBST_d006_ecuWdScheduleTout m0: 20|2@1+ (1,0) [0|0] "" X
 SG_ IBST_d007_ecuWdStarttestFls m0: 22|2@1+ (1,0) [0|0] "" X
 SG_ IBST_d008_ecuWdStatusContErr m0: 24|2@1+ (1,0) [0|0] "" X
 SG_ IBST_d009_netOvrvolt m0: 26|2@1+ (1,0) [0|0] "" X
 SG_ IBST_d010_micSpiTout m0: 28|2@1+ (1,0) [0|0] "" X
 SG_ IBST_d011_micSpiTransferErr m0: 30|2@1+ (1,0) [0|0] "" X
 SG_ IBST_d012_netUndvolt m0: 32|2@1+ (1,0) [0|0] "" X
 SG_ IBST_d013_xpassToutErr m0: 34|2@1+ (1,0) [0|0] "" X
 SG_ IBST_d014_rpsOffsEeReadEmpty m0: 36|2@1+ (1,0) [0|0] "" X
 SG_ IBST_d015_rtpEnaHigh m0: 38|2@1+ (1,0) [0|0] "" X
 SG_ IBST_d016_xpassEchoCountErr m0: 40|2@1+ (1,0) [0|0] "" X
 SG_ IBST_d017_preDriveChckFail m0: 42|2@1+ (1,0) [0|0] "" X
 SG_ IBST_d018_ucSafetyFlt m0: 44|2@1+ (1,0) [0|0] "" X
 SG_ IBST_d019_unsupportedHw m0: 46|2@1+ (1,0) [0|0] "" X
 SG_ IBST_d020_voltPreRegModeFld m0: 48|2@1+ (1,0) [0|0] "" X
 SG_ IBST_d021_ubbSupplyLine m0: 50|2@1+ (1,0) [0|0] "" X
 SG_ IBST_d022_stmAswSysTout m0: 52|2@1+ (1,0) [0|0] "" X
 SG_ IBST_d023_stackOvrUndFlow m0: 54|2@1+ (1,0) [0|0] "" X
 SG_ IBST_d024_smmOneReqsInit m0: 56|2@1+ (1,0) [0|0] "" X
 SG_ IBST_d025_ptsSupply m0: 58|2@1+ (1,0) [0|0] "" X
 SG_ IBST_d026_ptsSupplyUndvolt m0: 60|2@1+ (1,0) [0|0] "" X
 SG_ IBST_d027_tempB6Plaus m0: 62|2@1+ (1,0) [0|0] "" X
 SG_ IBST_d028_ecuWdErrCntContErr m1: 8|2@1+ (1,0) [0|0] "" X
 SG_ IBST_d029_bmcShortedGateTest m1: 10|2@1+ (1,0) [0|0] "" X
 SG_ IBST_d030_controllerDevTooBig m1: 12|2@1+ (1,0) [0|0] "" X
 SG_ IBST_d031_ibDtrFail m1: 14|2@1+ (1,0) [0|0] "" X
 SG_ IBST_d032_oc6InitTestFail m1: 16|2@1+ (1,0) [0|0] "" X
 SG_ IBST_d033_oc6Monitor m1: 18|2@1+ (1,0) [0|0] "" X
 SG_ IBST_d034_motorOscillationDet m1: 20|2@1+ (1,0) [0|0] "" X
 SG_ IBST_d035_rpsOffsEeReadFail m1: 22|2@1+ (1,0) [0|0] "" X
 SG_ IBST_d036_sysErrHook m1: 24|2@1+ (1,0) [0|0] "" X
 SG_ IBST_d037_calIdlePosNotPlaus m1: 26|2@1+ (1,0) [0|0] "" X
 SG_ IBST_d038_boostSupUndrvolt m1: 28|2@1+ (1,0) [0|0] "" X
 SG_ IBST_d039_calRoutineAbort m1: 30|2@1+ (1,0) [0|0] "" X
 SG_ IBST_d040_bmcGateUndervoltPro m1: 32|2@1+ (1,0) [0|0] "" X
 SG_ IBST_d041_hswInitPhseUndrvolt m1: 34|2@1+ (1,0) [0|0] "" X
 SG_ IBST_d042_ltmWarnLevelReached m1: 36|2@1+ (1,0) [0|0] "" X
 SG_ IBST_d043_rpsVctrLengthRelErr m1: 38|2@1+ (1,0) [0|0] "" X
 SG_ IBST_d044_b6TempDegradeLevel1 m1: 40|2@1+ (1,0) [0|0] "" X
 SG_ IBST_d045_B6TempDegradeLevel2 m1: 42|2@1+ (1,0) [0|0] "" X
 SG_ IBST_d046_spiAnglOrRawNotUp m1: 44|2@1+ (1,0) [0|0] "" X
 SG_ IBST_d047_dcomIboosterNotInit m1: 46|2@1+ (1,0) [0|0] "" X
 SG_ IBST_d048_unintendMotorReturn m1: 48|2@1+ (1,0) [0|0] "" X
 SG_ IBST_d049_cdmOvrvoltLevel1 m1: 50|2@1+ (1,0) [0|0] "" X
 SG_ IBST_d050_cdmUndrvoltLevel2 m1: 52|2@1+ (1,0) [0|0] "" X
 SG_ IBST_d051_cdmUndrvoltLevel1 m1: 54|2@1+ (1,0) [0|0] "" X
 SG_ IBST_d052_motTrvlRelReadFail m1: 56|2@1+ (1,0) [0|0] "" X
 SG_ IBST_d053_tle5012UnexpReset m1: 58|2@1+ (1,0) [0|0] "" X
 SG_ IBST_d054_bmsGateUndrvolt m1: 60|2@1+ (1,0) [0|0] "" X
 SG_ IBST_d055_kl15HwPlausSw m1: 62|2@1+ (1,0) [0|0] "" X
 SG_ IBST_d056_ibNotShutDownRight m2: 8|2@1+ (1,0) [0|0] "" X
 SG_ IBST_d057_cdmHardUndrvolt m2: 10|2@1+ (1,0) [0|0] "" X
 SG_ IBST_d058_cdmHardOvrvolt m2: 12|2@1+ (1,0) [0|0] "" X
 SG_ IBST_d059_maxTrvlAdjstUpdFail m2: 14|2@1+ (1,0) [0|0] "" X
 SG_ IBST_d060_ltmLimitReached m2: 16|2@1+ (1,0) [0|0] "" X
 SG_ IBST_d061_dcomEcuDefect m2: 18|2@1+ (1,0) [0|0] "" X
 SG_ IBST_d062_inputStroke1RngHigh m2: 20|2@1+ (1,0) [0|0] "" X
 SG_ IBST_d063_inputStroke1RngLow m2: 22|2@1+ (1,0) [0|0] "" X
 SG_ IBST_d064_inputStroke2RngHigh m2: 24|2@1+ (1,0) [0|0] "" X
 SG_ IBST_d065_inputStroke2RngLow m2: 26|2@1+ (1,0) [0|0] "" X
 SG_ IBST_d066_ibSupVoltDivDrift m2: 28|2@1+ (1,0) [0|0] "" X
 SG_ IBST_d067_sOutRodToPressVal m2: 30|2@1+ (1,0) [0|0] "" X
 SG_ IBST_d068_tle5012LifeCnt m2: 32|2@1+ (1,0) [0|0] "" X
 SG_ IBST_d069_cdmExtendedUndrvolt m2: 34|2@1+ (1,0) [0|0] "" X
 SG_ IBST_d070_cdmExtendedOvrvolt m2: 36|2@1+ (1,0) [0|0] "" X
 SG_ IBST_d071_tempB6Ch1LineHigh m2: 38|2@1+ (1,0) [0|0] "" X
 SG_ IBST_d072_tempB6Ch1LineLow m2: 40|2@1+ (1,0) [0|0] "" X
 SG_ IBST_d073_tempB6Ch2LineHigh m2: 42|2@1+ (1,0) [0|0] "" X
 SG_ IBST_d074_tempB6Ch2LineLow m2: 44|2@1+ (1,0) [0|0] "" X
 SG_ IBST_d075_hevSwitchOffDcom m2: 46|2@1+ (1,0) [0|0] "" X
 SG_ IBST_d076_tle5012VoltFail m2: 48|2@1+ (1,0) [0|0] "" X
 SG_ IBST_d077_bcsFltCurrentHigh m2: 50|2@1+ (1,0) [0|0] "" X
 SG_ IBST_d078_bcsFltCurrentLow m2: 52|2@1+ (1,0) [0|0] "" X
 SG_ IBST_d079_ecuSupVoltDivDrift m2: 54|2@1+ (1,0) [0|0] "" X
 SG_ IBST_d080_inputstroke1Grad m2: 56|2@1+ (1,0) [0|0] "" X
 SG_ IBST_d081_pts1Err m2: 58|2@1+ (1,0) [0|0] "" X
 SG_ IBST_d082_pts1LineGnd m2: 60|2@1+ (1,0) [0|0] "" X
 SG_ IBST_d083_pts1LineHigh m2: 62|2@1+ (1,0) [0|0] "" X
 SG_ IBST_d084_inputStroke2Grad m3: 8|2@1+ (1,0) [0|0] "" X
 SG_ IBST_d085_pts2Err m3: 10|2@1+ (1,0) [0|0] "" X
 SG_ IBST_d086_pts2LineGnd m3: 12|2@1+ (1,0) [0|0] "" X
 SG_ IBST_d087_pts2LineHigh m3: 14|2@1+ (1,0) [0|0] "" X
 SG_ IBST_d088_faildevInputStroke m3: 16|2@1+ (1,0) [0|0] "" X
 SG_ IBST_d089_ptsOffsTooHigh m3: 18|2@1+ (1,0) [0|0] "" X
 SG_ IBST_d090_pbistErr m3: 20|2@1+ (1,0) [0|0] "" X
 SG_ IBST_d091_ramInitErr m3: 22|2@1+ (1,0) [0|0] "" X
 SG_ IBST_d092_ramsinlgeFlt m3: 24|2@1+ (1,0) [0|0] "" X
 SG_ IBST_d093_bertFlt m3: 26|2@1+ (1,0) [0|0] "" X
 SG_ IBST_d094_CalDataNotPlaus m3: 28|2@1+ (1,0) [0|0] "" X
 SG_ IBST_d095_canEHwError m3: 30|2@1+ (1,0) [0|0] "" X
 SG_ IBST_d096_canETout m3: 32|2@1+ (1,0) [0|0] "" X
 SG_ IBST_d097_cpuException m3: 34|2@1+ (1,0) [0|0] "" X
 SG_ IBST_d098_ecuBandGap m3: 36|2@1+ (1,0) [0|0] "" X
 SG_ IBST_d099_ecuBmsOnWhileWdTout m3: 38|2@1+ (1,0) [0|0] "" X
 SG_ IBST_d100_ecuErrpinCntTstFls m3: 40|2@1+ (1,0) [0|0] "" X
 SG_ IBST_d101_ecuHetException m3: 42|2@1+ (1,0) [0|0] "" X
 SG_ IBST_d102_ecuHetTuAddErr m3: 44|2@1+ (1,0) [0|0] "" X
 SG_ IBST_d103_ecuHetTuBusErr m3: 46|2@1+ (1,0) [0|0] "" X
 SG_ IBST_d104_ecuHetTuBusyErr m3: 48|2@1+ (1,0) [0|0] "" X
 SG_ IBST_d105_ecuHetTuException m3: 50|2@1+ (1,0) [0|0] "" X
 SG_ IBST_d106_ecuTaskMissing m3: 52|2@1+ (1,0) [0|0] "" X
 SG_ IBST_d107_hetRefError m3: 54|2@1+ (1,0) [0|0] "" X
 SG_ IBST_d108_micInitSpiTstFld m3: 56|2@1+ (1,0) [0|0] "" X
 SG_ IBST_d109_micInitSpiTransfErr m3: 58|2@1+ (1,0) [0|0] "" X
 SG_ IBST_d110_micIntMonGenBitMon m3: 60|2@1+ (1,0) [0|0] "" X
 SG_ IBST_d111_micIntVoltMonFld m3: 62|2@1+ (1,0) [0|0] "" X
 SG_ IBST_d112_motPosTrvlReadEmpty m4: 8|2@1+ (1,0) [0|0] "" X
 SG_ IBST_d113_motAngBoundReadEmpt m4: 10|2@1+ (1,0) [0|0] "" X
 SG_ IBST_d114_motShaftShiftDetect m4: 12|2@1+ (1,0) [0|0] "" X
 SG_ IBST_d115_osErrHook m4: 14|2@1+ (1,0) [0|0] "" X
 SG_ IBST_d116_pdurEInitFail m4: 16|2@1+ (1,0) [0|0] "" X
 SG_ IBST_d117_pdurEPduInstLost m4: 18|2@1+ (1,0) [0|0] "" X
 SG_ IBST_d118_pts1OffsEeReadEmpty m4: 20|2@1+ (1,0) [0|0] "" X
 SG_ IBST_d119_pts2OffsEeReadEmpty m4: 22|2@1+ (1,0) [0|0] "" X
 SG_ IBST_d120_rpsOffsXEeReadFail m4: 24|2@1+ (1,0) [0|0] "" X
 SG_ IBST_d121_rpsOffsYEeReadFail m4: 26|2@1+ (1,0) [0|0] "" X
 SG_ IBST_d122_rpsSynchEeReadFail m4: 28|2@1+ (1,0) [0|0] "" X
 SG_ IBST_d123_rpsAnglRecalcErr m4: 30|2@1+ (1,0) [0|0] "" X
 SG_ IBST_d124_motTrvlRelWriteFail m4: 32|2@1+ (1,0) [0|0] "" X
 SG_ IBST_d125_motTrvlRelReadEmpty m4: 34|2@1+ (1,0) [0|0] "" X
 SG_ IBST_d126_ptsEeReadEmpty m4: 36|2@1+ (1,0) [0|0] "" X
 SG_ IBST_d127_ecuAdcConversionErr m4: 38|2@1+ (1,0) [0|0] "" X
 SG_ IBST_d128_ecuAdcSelftestErr m4: 40|2@1+ (1,0) [0|0] "" X
 SG_ IBST_d129_ccmFlt m4: 42|2@1+ (1,0) [0|0] "" X
 SG_ IBST_d130_ecuRomCheck m4: 44|2@1+ (1,0) [0|0] "" X
 SG_ IBST_d131_esmNmiFlt m4: 46|2@1+ (1,0) [0|0] "" X
 SG_ IBST_d132_esmSafetyFlt m4: 48|2@1+ (1,0) [0|0] "" X
 SG_ IBST_d133_motPosTrvlReadFail m4: 50|2@1+ (1,0) [0|0] "" X
 SG_ IBST_d134_motPosTrvlWriteFail m4: 52|2@1+ (1,0) [0|0] "" X
 SG_ IBST_d135_motAnglBndReadErr m4: 54|2@1+ (1,0) [0|0] "" X
 SG_ IBST_d136_motAnglBndWriteErr m4: 56|2@1+ (1,0) [0|0] "" X
 SG_ IBST_d137_motAnglGradTooLarge m4: 58|2@1+ (1,0) [0|0] "" X
 SG_ IBST_d138_pdmCustomerIdMis m4: 60|2@1+ (1,0) [0|0] "" X
 SG_ IBST_d139_pdmDtFormatMis m4: 62|2@1+ (1,0) [0|0] "" X
 SG_ IBST_d140_pdmOutOfMemory m5: 8|2@1+ (1,0) [0|0] "" X
 SG_ IBST_d141_pdmFieldSizeMis m5: 10|2@1+ (1,0) [0|0] "" X
 SG_ IBST_d142_pdmHwAcsErr m5: 12|2@1+ (1,0) [0|0] "" X
 SG_ IBST_d143_pdmInternalHWErr m5: 14|2@1+ (1,0) [0|0] "" X
 SG_ IBST_d144_ptsCalHysWritFail m5: 16|2@1+ (1,0) [0|0] "" X
 SG_ IBST_d145_ptsCalValuesChkFail m5: 18|2@1+ (1,0) [0|0] "" X
 SG_ IBST_d146_pts1CalEeReadFail m5: 20|2@1+ (1,0) [0|0] "" X
 SG_ IBST_d147_pts1CalEeWriteFail m5: 22|2@1+ (1,0) [0|0] "" X
 SG_ IBST_d148_rpsFailCompErr m5: 24|2@1+ (1,0) [0|0] "" X
 SG_ IBST_d149_pts1OffsEeWriteFail m5: 26|2@1+ (1,0) [0|0] "" X
 SG_ IBST_d150_pts2CalEeReadFail m5: 28|2@1+ (1,0) [0|0] "" X
 SG_ IBST_d151_pts2CalEeWriteFail m5: 30|2@1+ (1,0) [0|0] "" X
 SG_ IBST_d152_pts2OffsEeReadFail m5: 32|2@1+ (1,0) [0|0] "" X
 SG_ IBST_d153_pts2OffsEeWriteFail m5: 34|2@1+ (1,0) [0|0] "" X
 SG_ IBST_d154_rpsOffsXEeReadEmpty m5: 36|2@1+ (1,0) [0|0] "" X
 SG_ IBST_d155_rpsOffsXEeWriteFail m5: 38|2@1+ (1,0) [0|0] "" X
 SG_ IBST_d156_rpsOffsYEeReadEmpty m5: 40|2@1+ (1,0) [0|0] "" X
 SG_ IBST_d157_rpsOffsYEeWriteFail m5: 42|2@1+ (1,0) [0|0] "" X
 SG_ IBST_d158_rpsSynchEeReadEmpty m5: 44|2@1+ (1,0) [0|0] "" X
 SG_ IBST_d159_rpsSynchEeWriteFail m5: 46|2@1+ (1,0) [0|0] "" X
 SG_ IBST_d160_assertionFail m5: 48|2@1+ (1,0) [0|0] "" X
 SG_ IBST_d161_comsclBrkPrsPduLen m5: 50|2@1+ (1,0) [0|0] "" X
 SG_ IBST_d162_comsclBrkPrsPduTout m5: 52|2@1+ (1,0) [0|0] "" X
 SG_ IBST_d163_comsclEspIb1CntErr m5: 54|2@1+ (1,0) [0|0] "" X
 SG_ IBST_d164_comsclEspIb1CsErr m5: 56|2@1+ (1,0) [0|0] "" X
 SG_ IBST_d165_comsclEspIb1DlcErr m5: 58|2@1+ (1,0) [0|0] "" X
 SG_ IBST_d166_comsclEspIb1Tout m5: 60|2@1+ (1,0) [0|0] "" X
 SG_ IBST_d167_comsclEspIb2CntErr m5: 62|2@1+ (1,0) [0|0] "" X
 SG_ IBST_d168_comsclEspIb2CsErr m6: 8|2@1+ (1,0) [0|0] "" X
 SG_ IBST_d169_comsclEspIb2DlcErr m6: 10|2@1+ (1,0) [0|0] "" X
 SG_ IBST_d170_comsclEspIb2Tout m6: 12|2@1+ (1,0) [0|0] "" X
 SG_ IBST_d171_comsclEspIb3CntErr m6: 14|2@1+ (1,0) [0|0] "" X
 SG_ IBST_d172_comsclEspIb3CsErr m6: 16|2@1+ (1,0) [0|0] "" X
 SG_ IBST_d173_comsclEspIb3DlcErr m6: 18|2@1+ (1,0) [0|0] "" X
 SG_ IBST_d174_comsclEspIb3Tout m6: 20|2@1+ (1,0) [0|0] "" X
 SG_ IBST_d175_comsclGtwEsp1CntErr m6: 22|2@1+ (1,0) [0|0] "" X
 SG_ IBST_d176_comsclGtwEsp1CsErr m6: 24|2@1+ (1,0) [0|0] "" X
 SG_ IBST_d177_comsclGtwEsp1Corrpt m6: 26|2@1+ (1,0) [0|0] "" X
 SG_ IBST_d178_comsclGtwEsp1Tout m6: 28|2@1+ (1,0) [0|0] "" X
 SG_ IBST_d179_dcomSmrtActuNotInit m6: 30|2@1+ (1,0) [0|0] "" X
 SG_ IBST_d180_rpsLengthAbsolHigh m6: 32|2@1+ (1,0) [0|0] "" X
 SG_ IBST_d181_rpsLengthAbsolLow m6: 34|2@1+ (1,0) [0|0] "" X
 SG_ IBST_d182_shutDownEeReadFail m6: 36|2@1+ (1,0) [0|0] "" X
 SG_ IBST_d183_shutDownEeWriteFail m6: 38|2@1+ (1,0) [0|0] "" X
 SG_ IBST_d184_maxTrvlAdjstReadErr m6: 40|2@1+ (1,0) [0|0] "" X
 SG_ IBST_d185_psOffsMcEeReadFail m6: 42|2@1+ (1,0) [0|0] "" X
 SG_ IBST_d186_psOffsMcEeWriteFail m6: 44|2@1+ (1,0) [0|0] "" X
 SG_ IBST_d187_ltmSelfProtDeact m6: 46|2@1+ (1,0) [0|0] "" X
 SG_ IBST_d188_pts1OffsEeReadFail m6: 48|2@1+ (1,0) [0|0] "" X
 SG_ IBST_d189_diffStrokeRange m6: 50|2@1+ (1,0) [0|0] "" X
 SG_ IBST_d190_notProgVin m6: 52|2@1+ (1,0) [0|0] "" X
 SG_ IBST_d191_plausVin m6: 54|2@1+ (1,0) [0|0] "" X
 SG_ IBST_d192_dlCorCSumVin m6: 56|2@1+ (1,0) [0|0] "" X
 SG_ IBST_d193_ToutVin m6: 58|2@1+ (1,0) [0|0] "" X
 SG_ IBST_d194_ecuEnableB6Fail m6: 60|2@1+ (1,0) [0|0] "" X
 SG_ IBST_d195_ecuIbEnContErr m6: 62|2@1+ (1,0) [0|0] "" X
 SG_ IBST_d196_sclEspIb1pEstMax m7: 8|2@1+ (1,0) [0|0] "" X
 SG_ IBST_d197_sclEspIb1VehSpd m7: 10|2@1+ (1,0) [0|0] "" X
 SG_ IBST_d198_sclEspIb2pLimExt m7: 12|2@1+ (1,0) [0|0] "" X
 SG_ IBST_d199_sclEspIb2qTarExt m7: 14|2@1+ (1,0) [0|0] "" X
 SG_ IBST_d200_sclEspIb3pFBlend m7: 16|2@1+ (1,0) [0|0] "" X
 SG_ IBST_d201_sclEspIb3pMc1 m7: 18|2@1+ (1,0) [0|0] "" X
 SG_ IBST_d202_sclEspIb3pTarDriver m7: 20|2@1+ (1,0) [0|0] "" X
 SG_ IBST_d203_netBusOffNet0 m7: 22|2@1+ (1,0) [0|0] "" X
 SG_ IBST_d204_netErrPassivNet0 m7: 24|2@1+ (1,0) [0|0] "" X
 SG_ IBST_d205_netBusOffNet1 m7: 26|2@1+ (1,0) [0|0] "" X
 SG_ IBST_d206_netErrPassivNet1 m7: 28|2@1+ (1,0) [0|0] "" X
 SG_ IBST_d207_maxStrokeReached m7: 30|2@1+ (1,0) [0|0] "" X
 SG_ IBST_d208_sysSwClockMismatch m7: 32|2@1+ (1,0) [0|0] "" X
 SG_ IBST_d209_comsclGtwOdoCorrpt m7: 34|2@1+ (1,0) [0|0] "" X
 SG_ IBST_d210_comsclGtwStatCorrpt m7: 36|2@1+ (1,0) [0|0] "" X
 SG_ IBST_d211_comsclEpbStatCorrpt m7: 38|2@1+ (1,0) [0|0] "" X
 SG_ IBST_d212_comsclGtwOdoTout m7: 40|2@1+ (1,0) [0|0] "" X
 SG_ IBST_d213_comsclGtwStatTout m7: 42|2@1+ (1,0) [0|0] "" X
 SG_ IBST_d214_comsclEpbStatTout m7: 44|2@1+ (1,0) [0|0] "" X
 SG_ IBST_d215_comSclEpbStatCsErr m7: 46|2@1+ (1,0) [0|0] "" X
 SG_ IBST_d216_comSclEpbStatCntFlt m7: 48|2@1+ (1,0) [0|0] "" X
 SG_ IBST_d217_comSclDiTrq1Tout m7: 50|2@1+ (1,0) [0|0] "" X
 SG_ IBST_d218_comSclDiTrq1Corrpt m7: 52|2@1+ (1,0) [0|0] "" X
 SG_ IBST_d219_comSclDiTrq1CsErr m7: 54|2@1+ (1,0) [0|0] "" X
 SG_ IBST_d220_comSclDiTrq1CntFlt m7: 56|2@1+ (1,0) [0|0] "" X

BO_ 813 IBST_info: 8 ETH
 SG_ IBST_infoIndex M: 0|8@1+ (1,0) [0|0] "" X
 SG_ IBST_buildType m10: 8|8@1+ (1,0) [0|0] "" X
 SG_ IBST_componentId m10: 48|16@1+ (1,0) [0|0] "" X
 SG_ IBST_pcbaId m11: 16|8@1+ (1,0) [0|0] "" X
 SG_ IBST_assemblyId m11: 24|8@1+ (1,0) [0|0] "" X
 SG_ IBST_usageId m11: 32|16@1+ (1,0) [0|0] "" X
 SG_ IBST_udsProtocolVersion m20: 8|8@1+ (1,0) [0|0] "" X
 SG_ IBST_bootloaderCrc m20: 32|32@1+ (1,0) [0|0] "" X
 SG_ IBST_applicationCrc m13: 32|32@1+ (1,0) [0|0] "" X
 SG_ IBST_variantCrc m22: 32|32@1+ (1,0) [0|0] "" X

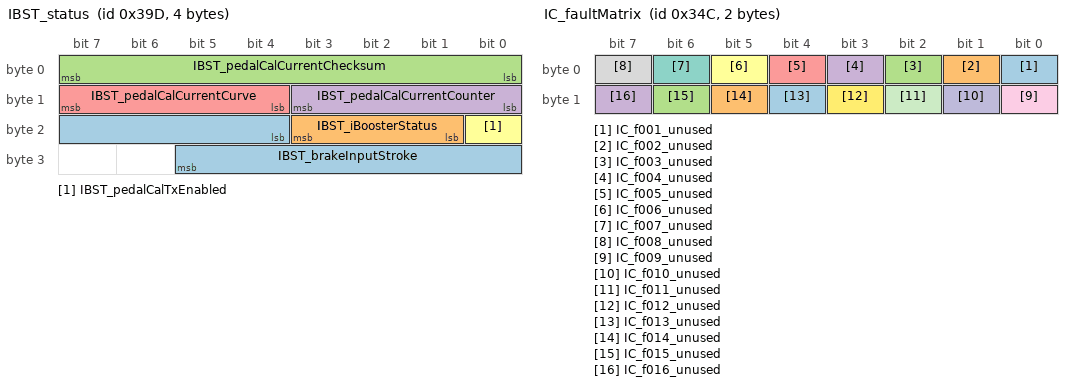
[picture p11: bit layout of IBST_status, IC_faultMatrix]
BO_ 925 IBST_status: 4 ETH
 SG_ IBST_brakeInputStroke: 20|10@1+ (0.05,-0.5) [0|0] "mm" X
 SG_ IBST_iBoosterStatus: 17|3@1+ (1,0) [0|0] "" X
 SG_ IBST_pedalCalCurrentChecksum: 0|8@1+ (1,0) [0|0] "" X
 SG_ IBST_pedalCalCurrentCounter: 8|4@1+ (1,0) [0|0] "" X
 SG_ IBST_pedalCalCurrentCurve: 12|4@1+ (1,0) [0|0] "1" X
 SG_ IBST_pedalCalTxEnabled: 16|1@1+ (1,0) [0|0] "1" X

BO_ 1632 IBST_udsResponse: 8 ETH
 SG_ IBST_udsResponseData: 0|54@0+ (1024,0) [0|0] "" X

BO_ 22 IBS_status: 8 ETH
 SG_ IBS_current: 0|32@0+ (1,-2e+06) [0|0] "mA" X
 SG_ IBS_temperature: 48|16@0+ (0.5,-40) [0|0] "deg C" X
 SG_ IBS_voltage: 32|16@0+ (1,0) [0|0] "mV" X

BO_ 844 IC_faultMatrix: 2 ETH
 SG_ IC_f001_unused: 0|1@1+ (1,0) [0|0] "" X
 SG_ IC_f002_unused: 1|1@1+ (1,0) [0|0] "" X
 SG_ IC_f003_unused: 2|1@1+ (1,0) [0|0] "" X
 SG_ IC_f004_unused: 3|1@1+ (1,0) [0|0] "" X
 SG_ IC_f005_unused: 4|1@1+ (1,0) [0|0] "" X
 SG_ IC_f006_unused: 5|1@1+ (1,0) [0|0] "" X
 SG_ IC_f007_unused: 6|1@1+ (1,0) [0|0] "" X
 SG_ IC_f008_unused: 7|1@1+ (1,0) [0|0] "" X
 SG_ IC_f009_unused: 8|1@1+ (1,0) [0|0] "" X
 SG_ IC_f010_unused: 9|1@1+ (1,0) [0|0] "" X
 SG_ IC_f011_unused: 10|1@1+ (1,0) [0|0] "" X
 SG_ IC_f012_unused: 11|1@1+ (1,0) [0|0] "" X
 SG_ IC_f013_unused: 12|1@1+ (1,0) [0|0] "" X
 SG_ IC_f014_unused: 13|1@1+ (1,0) [0|0] "" X
 SG_ IC_f015_unused: 14|1@1+ (1,0) [0|0] "" X
 SG_ IC_f016_unused: 15|1@1+ (1,0) [0|0] "" X

BO_ 134 IC_info: 8 ETH
 SG_ IC_infoIndex M: 0|8@1+ (1,0) [0|0] "" X
 SG_ IC_buildType m10: 8|8@1+ (1,0) [0|0] "" X
 SG_ IC_buildConfigurationId m10: 16|16@1+ (1,0) [0|0] "" X
 SG_ IC_hardwareId m10: 32|16@1+ (1,0) [0|0] "" X
 SG_ IC_componentId m10: 48|16@1+ (1,0) [0|0] "" X
 SG_ IC_pcbaId m11: 16|8@1+ (1,0) [0|0] "" X
 SG_ IC_assemblyId m11: 24|8@1+ (1,0) [0|0] "" X
 SG_ IC_usageId m11: 32|16@1+ (1,0) [0|0] "" X
 SG_ IC_subUsageId m11: 48|16@1+ (1,0) [0|0] "" X
 SG_ IC_applicationCrc m13: 32|32@1+ (1,0) [0|0] "" X
 SG_ IC_FPGA_version m16: 16|8@1+ (1,0) [0|0] "" X
 SG_ IC_platformTyp m19: 8|8@1+ (1,0) [0|0] "" X
 SG_ IC_infoBootLdUdsProtocolVersion m20: 8|8@1+ (1,0) [0|0] "" X
 SG_ IC_bootloaderCrc m20: 32|32@1+ (1,0) [0|0] "" X

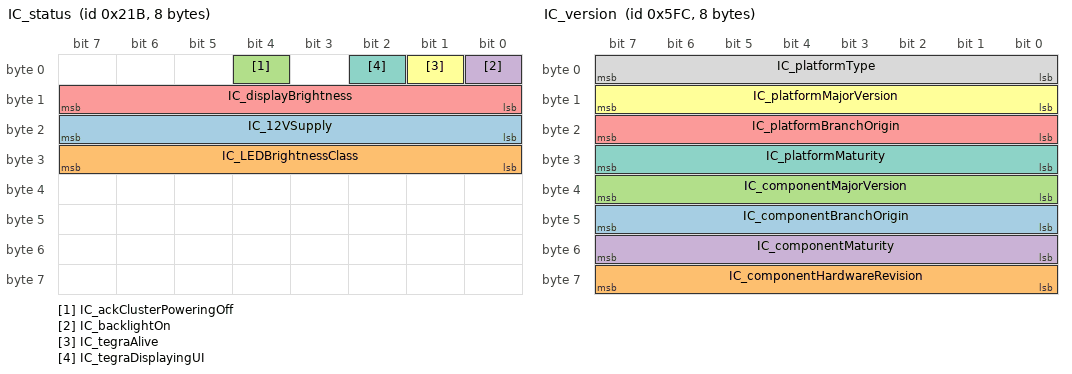
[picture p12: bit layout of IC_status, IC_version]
BO_ 539 IC_status: 8 ETH
 SG_ IC_12VSupply: 16|8@1+ (0.1,0) [0|0] "V" X
 SG_ IC_LEDBrightnessClass: 24|8@1+ (1,0) [0|0] "" X
 SG_ IC_ackClusterPoweringOff: 4|1@1+ (1,0) [0|0] "" X
 SG_ IC_backlightOn: 0|1@1+ (1,0) [0|0] "" X
 SG_ IC_displayBrightness: 8|8@1+ (0.5,0) [0|0] "%" X
 SG_ IC_tegraAlive: 1|1@1+ (1,0) [0|0] "" X
 SG_ IC_tegraDisplayingUI: 2|1@1+ (1,0) [0|0] "" X

BO_ 1628 IC_udsResponse: 8 ETH
 SG_ IC_udsResponse: 0|54@0+ (1024,0) [0|0] "" X

BO_ 1532 IC_version: 8 ETH
 SG_ IC_componentBranchOrigin: 40|8@1+ (1,0) [0|0] "" X
 SG_ IC_componentHardwareRevision: 56|8@1+ (1,0) [0|0] "" X
 SG_ IC_componentMajorVersion: 32|8@1+ (1,0) [0|0] "" X
 SG_ IC_componentMaturity: 48|8@1+ (1,0) [0|0] "" X
 SG_ IC_platformBranchOrigin: 16|8@1+ (1,0) [0|0] "" X
 SG_ IC_platformMajorVersion: 8|8@1+ (1,0) [0|0] "" X
 SG_ IC_platformMaturity: 24|8@1+ (1,0) [0|0] "" X
 SG_ IC_platformType: 0|8@1+ (1,0) [0|0] "" X

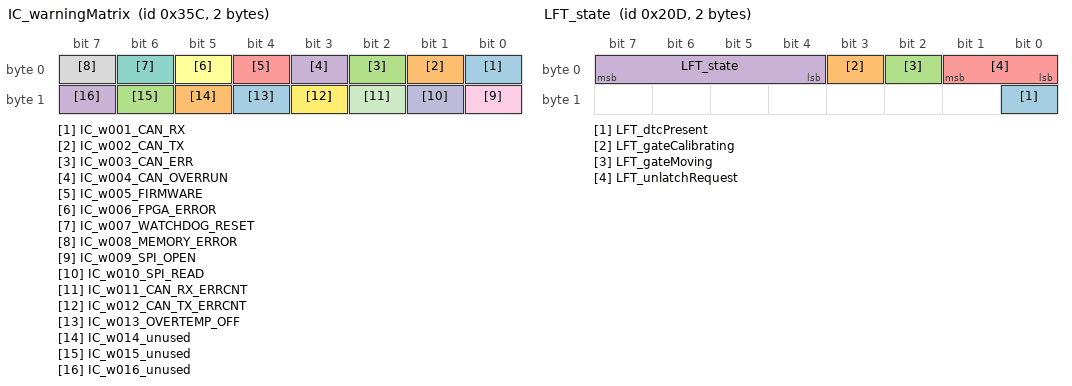
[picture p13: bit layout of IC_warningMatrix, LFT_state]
BO_ 860 IC_warningMatrix: 2 ETH
 SG_ IC_w001_CAN_RX: 0|1@1+ (1,0) [0|0] "" X
 SG_ IC_w002_CAN_TX: 1|1@1+ (1,0) [0|0] "" X
 SG_ IC_w003_CAN_ERR: 2|1@1+ (1,0) [0|0] "" X
 SG_ IC_w004_CAN_OVERRUN: 3|1@1+ (1,0) [0|0] "" X
 SG_ IC_w005_FIRMWARE: 4|1@1+ (1,0) [0|0] "" X
 SG_ IC_w006_FPGA_ERROR: 5|1@1+ (1,0) [0|0] "" X
 SG_ IC_w007_WATCHDOG_RESET: 6|1@1+ (1,0) [0|0] "" X
 SG_ IC_w008_MEMORY_ERROR: 7|1@1+ (1,0) [0|0] "" X
 SG_ IC_w009_SPI_OPEN: 8|1@1+ (1,0) [0|0] "" X
 SG_ IC_w010_SPI_READ: 9|1@1+ (1,0) [0|0] "" X
 SG_ IC_w011_CAN_RX_ERRCNT: 10|1@1+ (1,0) [0|0] "" X
 SG_ IC_w012_CAN_TX_ERRCNT: 11|1@1+ (1,0) [0|0] "" X
 SG_ IC_w013_OVERTEMP_OFF: 12|1@1+ (1,0) [0|0] "" X
 SG_ IC_w014_unused: 13|1@1+ (1,0) [0|0] "" X
 SG_ IC_w015_unused: 14|1@1+ (1,0) [0|0] "" X
 SG_ IC_w016_unused: 15|1@1+ (1,0) [0|0] "" X

BO_ 525 LFT_state: 2 ETH
 SG_ LFT_dtcPresent: 8|1@1+ (1,0) [0|0] "" X
 SG_ LFT_gateCalibrating: 3|1@1+ (1,0) [0|0] "" X
 SG_ LFT_gateMoving: 2|1@1+ (1,0) [0|0] "" X
 SG_ LFT_state: 4|4@1+ (1,0) [0|0] "" X
 SG_ LFT_unlatchRequest: 0|2@1+ (1,0) [0|0] "" X

BO_ 1693 LFT_udsResponse: 8 ETH
 SG_ LFT_udsResponseData: 0|54@0+ (1024,0) [0|0] "" X

BO_ 1293 LFT_version: 8 ETH
 SG_ LFT_componentBranchOrigin: 40|8@1+ (1,0) [0|0] "" X
 SG_ LFT_componentHardwareRevision: 56|8@1+ (1,0) [0|0] "" X
 SG_ LFT_componentMajorVersion: 32|8@1+ (1,0) [0|0] "" X
 SG_ LFT_componentMaturity: 48|8@1+ (1,0) [0|0] "" X
 SG_ LFT_componentSvn: 8|24@0+ (1,0) [0|0] "" X
 SG_ LFT_platformType: 0|8@1+ (1,0) [0|0] "" X

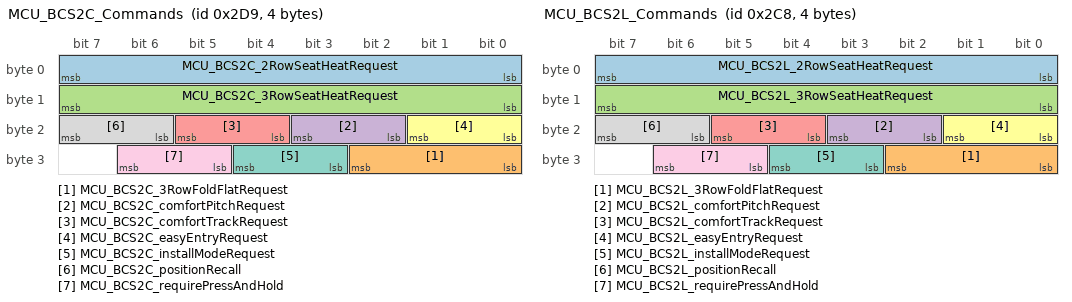
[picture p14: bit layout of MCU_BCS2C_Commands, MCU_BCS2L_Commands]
BO_ 729 MCU_BCS2C_Commands: 4 ETH
 SG_ MCU_BCS2C_2RowSeatHeatRequest: 0|8@1+ (1,0) [0|0] "" X
 SG_ MCU_BCS2C_3RowFoldFlatRequest: 24|3@1+ (1,0) [0|0] "" X
 SG_ MCU_BCS2C_3RowSeatHeatRequest: 8|8@1+ (1,0) [0|0] "" X
 SG_ MCU_BCS2C_comfortPitchRequest: 18|2@1+ (1,0) [0|0] "" X
 SG_ MCU_BCS2C_comfortTrackRequest: 20|2@1+ (1,0) [0|0] "" X
 SG_ MCU_BCS2C_easyEntryRequest: 16|2@1+ (1,0) [0|0] "" X
 SG_ MCU_BCS2C_installModeRequest: 27|2@1+ (1,0) [0|0] "" X
 SG_ MCU_BCS2C_positionRecall: 22|2@1+ (1,0) [0|0] "" X
 SG_ MCU_BCS2C_requirePressAndHold: 29|2@1+ (1,0) [0|0] "" X

BO_ 712 MCU_BCS2L_Commands: 4 ETH
 SG_ MCU_BCS2L_2RowSeatHeatRequest: 0|8@1+ (1,0) [0|0] "" X
 SG_ MCU_BCS2L_3RowFoldFlatRequest: 24|3@1+ (1,0) [0|0] "" X
 SG_ MCU_BCS2L_3RowSeatHeatRequest: 8|8@1+ (1,0) [0|0] "" X
 SG_ MCU_BCS2L_comfortPitchRequest: 18|2@1+ (1,0) [0|0] "" X
 SG_ MCU_BCS2L_comfortTrackRequest: 20|2@1+ (1,0) [0|0] "" X
 SG_ MCU_BCS2L_easyEntryRequest: 16|2@1+ (1,0) [0|0] "" X
 SG_ MCU_BCS2L_installModeRequest: 27|2@1+ (1,0) [0|0] "" X
 SG_ MCU_BCS2L_positionRecall: 22|2@1+ (1,0) [0|0] "" X
 SG_ MCU_BCS2L_requirePressAndHold: 29|2@1+ (1,0) [0|0] "" X

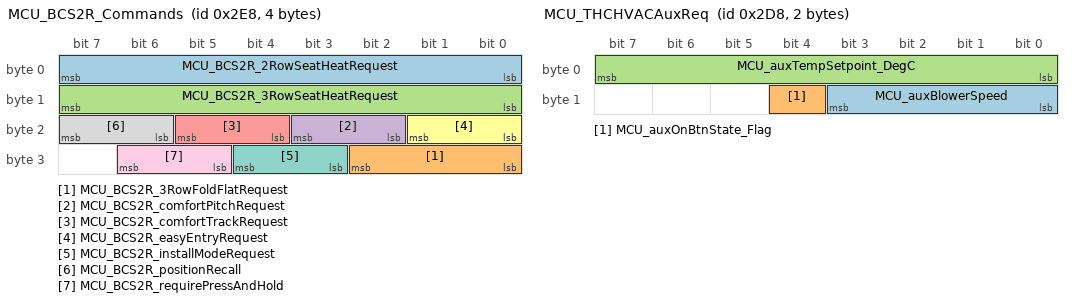
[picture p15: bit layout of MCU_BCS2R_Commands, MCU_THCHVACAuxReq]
BO_ 744 MCU_BCS2R_Commands: 4 ETH
 SG_ MCU_BCS2R_2RowSeatHeatRequest: 0|8@1+ (1,0) [0|0] "" X
 SG_ MCU_BCS2R_3RowFoldFlatRequest: 24|3@1+ (1,0) [0|0] "" X
 SG_ MCU_BCS2R_3RowSeatHeatRequest: 8|8@1+ (1,0) [0|0] "" X
 SG_ MCU_BCS2R_comfortPitchRequest: 18|2@1+ (1,0) [0|0] "" X
 SG_ MCU_BCS2R_comfortTrackRequest: 20|2@1+ (1,0) [0|0] "" X
 SG_ MCU_BCS2R_easyEntryRequest: 16|2@1+ (1,0) [0|0] "" X
 SG_ MCU_BCS2R_installModeRequest: 27|2@1+ (1,0) [0|0] "" X
 SG_ MCU_BCS2R_positionRecall: 22|2@1+ (1,0) [0|0] "" X
 SG_ MCU_BCS2R_requirePressAndHold: 29|2@1+ (1,0) [0|0] "" X

BO_ 415 MCU_SCCM_IC_A1: 8 ETH
 SG_ AirTemp_Outsd_Disp: 16|8@1+ (0.5,-40) [0|0] "C" X
 SG_ EngShutOffTm: 24|12@0+ (1,0) [0|0] "min" X
 SG_ HiBm_Enbl: 28|2@1+ (1,0) [0|0] "" X
 SG_ ODO: 40|24@1+ (0.1,0) [0|0] "km" X
 SG_ PTS_Disp_Stat_IC: 30|2@1+ (1,0) [0|0] "" X
 SG_ SwHeat: 3|1@1+ (1,0) [0|0] "" X
 SG_ VehSpd_Disp: 0|11@0+ (0.1,0) [0|0] "km/h" X
 SG_ Vprzr_DryVnTmr_Stat: 4|2@1+ (1,0) [0|0] "" X

BO_ 728 MCU_THCHVACAuxReq: 2 ETH
 SG_ MCU_auxBlowerSpeed: 8|4@1+ (1,0) [0|0] "" X
 SG_ MCU_auxOnBtnState_Flag: 12|1@1+ (1,0) [0|0] "" X
 SG_ MCU_auxTempSetpoint_DegC: 0|8@1+ (0.5,0) [0|0] "degC" X

BO_ 50 MCU_THCHumanInterfaceRequest: 7 ETH
 SG_ MCU_AconBtnState_Flag: 31|1@1+ (1,0) [0|0] "" X
 SG_ MCU_AconMnl_Flag: 19|1@1+ (1,0) [0|0] "" X
 SG_ MCU_AmbientRecircOff: 23|1@1+ (1,0) [0|0] "" X
 SG_ MCU_AutoBtnState_Flag: 24|1@1+ (1,0) [0|0] "" X
 SG_ MCU_BioWeaponBtnState_Flag: 37|1@1+ (1,0) [0|0] "" X
 SG_ MCU_BlowerMotorMnlSet_Seg: 40|4@1+ (1,0) [0|0] "" X
 SG_ MCU_BlowerMotorMnl_Flag: 17|1@1+ (1,0) [0|0] "" X
 SG_ MCU_ControlModeSet_Flag: 32|3@1+ (1,0) [0|0] "" X
 SG_ MCU_DefogBtnState_Flag: 26|2@1+ (1,0) [0|0] "" X
 SG_ MCU_DualBtnState_Flag: 25|1@1+ (1,0) [0|0] "" X
 SG_ MCU_FaultCodeRequest_Flag: 35|1@1+ (1,0) [0|0] "" X
 SG_ MCU_HtronBtnState_Flag: 21|1@1+ (1,0) [0|0] "" X
 SG_ MCU_HtronMnl_Flag: 22|1@1+ (1,0) [0|0] "" X
 SG_ MCU_IntakeActMnl_Flag: 18|1@1+ (1,0) [0|0] "" X
 SG_ MCU_IntakeBtnState_Flag: 29|2@1+ (1,0) [0|0] "" X
 SG_ MCU_IonizerOn: 20|1@1+ (1,0) [0|0] "" X
 SG_ MCU_LeftTempSetpoint_DegC: 0|8@1+ (0.5,0) [0|0] "degC" X
 SG_ MCU_ModeActMnlSet_Flag: 44|4@1+ (1,0) [0|0] "" X
 SG_ MCU_ModeActMnl_Flag: 16|1@1+ (1,0) [0|0] "" X
 SG_ MCU_OffBtnState_Flag: 28|1@1+ (1,0) [0|0] "" X
 SG_ MCU_RightTempSetpoint_DegC: 8|8@1+ (0.5,0) [0|0] "degC" X
 SG_ MCU_TestModeSet_Flag: 48|8@1+ (1,0) [0|0] "" X
 SG_ MCU_passengerSeatOccupied_Flag: 38|1@1+ (1,0) [0|0] "" X
 SG_ MCU_rearJumpSeatsOccupied_Flag: 36|1@1+ (1,0) [0|0] "" X

BO_ 54 MCU_THCRequest: 1 ETH
 SG_ THC_CabinHeaterOn: 0|1@1+ (1,0) [0|0] "" X

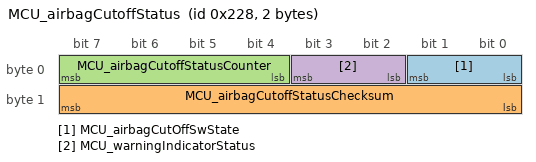
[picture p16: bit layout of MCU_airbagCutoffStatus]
BO_ 552 MCU_airbagCutoffStatus: 2 ETH
 SG_ MCU_airbagCutOffSwState: 0|2@1+ (1,0) [0|0] "" X
 SG_ MCU_airbagCutoffStatusChecksum: 8|8@1+ (1,0) [0|0] "" X
 SG_ MCU_airbagCutoffStatusCounter: 4|4@1+ (1,0) [0|0] "" X
 SG_ MCU_warningIndicatorStatus: 2|2@1+ (1,0) [0|0] "" X

BO_ 101 MCU_alertLog: 8 ETH
 SG_ MCU_alertFault: 15|1@1+ (1,0) [0|0] "" X
 SG_ MCU_alertId M: 0|15@1+ (1,0) [0|0] "" X
 SG_ MCU_a000_alertWord0 m0: 16|16@1+ (8,0) [0|0] "" X
 SG_ MCU_a000_alertWord1 m0: 32|16@1+ (8,0) [0|0] "" X
 SG_ MCU_a000_alertWord2 m0: 48|16@1+ (8,0) [0|0] "" X
 SG_ MCU_a017_touchProblem m17: 16|1@1+ (1,0) [0|0] "" X
 SG_ MCU_a017_displayProblem m17: 17|1@1+ (1,0) [0|0] "" X
 SG_ MCU_a017_modemProblem m17: 18|1@1+ (1,0) [0|0] "" X
 SG_ MCU_a017_audioProblem m17: 19|1@1+ (1,0) [0|0] "" X
 SG_ MCU_a017_parrotProblem m17: 20|1@1+ (1,0) [0|0] "" X
 SG_ MCU_a004_touchScreenErrorCode m4: 16|8@1+ (1,0) [0|0] "" X
 SG_ MCU_a029_remoteServiceAlertCode m29: 16|48@1+ (1,0) [0|0] "" X

BA_DEF_ BO_ "GenMsgSendType" ENUM "Cyclic";
BA_DEF_ BO_ "GenMsgCycleTime" INT 0 60000;

BA_ "GenMsgSendType" BO_ 823 0;
BA_ "GenMsgCycleTime" BO_ 823 1000;

BA_ "GenMsgSendType" BO_ 791 0;
BA_ "GenMsgCycleTime" BO_ 791 1000;

BA_ "GenMsgSendType" BO_ 807 0;
BA_ "GenMsgCycleTime" BO_ 807 1000;

BA_ "GenMsgSendType" BO_ 1351 0;
BA_ "GenMsgCycleTime" BO_ 1351 1000;

BA_ "GenMsgSendType" BO_ 551 0;
BA_ "GenMsgCycleTime" BO_ 551 100;

BA_ "GenMsgSendType" BO_ 1415 0;
BA_ "GenMsgCycleTime" BO_ 1415 10000;

BA_ "GenMsgSendType" BO_ 1431 0;
BA_ "GenMsgCycleTime" BO_ 1431 1000;

BA_ "GenMsgSendType" BO_ 772 0;
BA_ "GenMsgCycleTime" BO_ 772 1000;

BA_ "GenMsgSendType" BO_ 820 0;
BA_ "GenMsgCycleTime" BO_ 820 1000;

BA_ "GenMsgSendType" BO_ 788 0;
BA_ "GenMsgCycleTime" BO_ 788 1000;

BA_ "GenMsgSendType" BO_ 804 0;
BA_ "GenMsgCycleTime" BO_ 804 1000;

BA_ "GenMsgSendType" BO_ 836 0;
BA_ "GenMsgCycleTime" BO_ 836 1000;

BA_ "GenMsgSendType" BO_ 1332 0;
BA_ "GenMsgCycleTime" BO_ 1332 1000;

BA_ "GenMsgSendType" BO_ 516 0;
BA_ "GenMsgCycleTime" BO_ 516 100;

BA_ "GenMsgSendType" BO_ 1444 0;
BA_ "GenMsgCycleTime" BO_ 1444 10000;

BA_ "GenMsgSendType" BO_ 1428 0;
BA_ "GenMsgCycleTime" BO_ 1428 1000;

BA_ "GenMsgSendType" BO_ 293 0;
BA_ "GenMsgCycleTime" BO_ 293 1000;

BA_ "GenMsgSendType" BO_ 56 0;
BA_ "GenMsgCycleTime" BO_ 56 1000;

BA_ "GenMsgSendType" BO_ 325 0;
BA_ "GenMsgCycleTime" BO_ 325 50;

BA_ "GenMsgSendType" BO_ 1 0;
BA_ "GenMsgCycleTime" BO_ 1 100;

BA_ "GenMsgSendType" BO_ 504 0;
BA_ "GenMsgCycleTime" BO_ 504 100;

BA_ "GenMsgSendType" BO_ 91 0;
BA_ "GenMsgCycleTime" BO_ 91 1000;

BA_ "GenMsgSendType" BO_ 949 0;
BA_ "GenMsgCycleTime" BO_ 949 1000;

BA_ "GenMsgSendType" BO_ 805 0;
BA_ "GenMsgCycleTime" BO_ 805 10000;

BA_ "GenMsgSendType" BO_ 1502 0;
BA_ "GenMsgCycleTime" BO_ 1502 10000;

BA_ "GenMsgSendType" BO_ 1500 0;
BA_ "GenMsgCycleTime" BO_ 1500 10000;

BA_ "GenMsgSendType" BO_ 533 0;
BA_ "GenMsgCycleTime" BO_ 533 1000;

BA_ "GenMsgSendType" BO_ 543 0;
BA_ "GenMsgCycleTime" BO_ 543 1000;

BA_ "GenMsgSendType" BO_ 1122 0;
BA_ "GenMsgCycleTime" BO_ 1122 100;

BA_ "GenMsgSendType" BO_ 1124 0;
BA_ "GenMsgCycleTime" BO_ 1124 1000;

BA_ "GenMsgSendType" BO_ 644 0;
BA_ "GenMsgCycleTime" BO_ 644 1000;

BA_ "GenMsgSendType" BO_ 645 0;
BA_ "GenMsgCycleTime" BO_ 645 1000;

BA_ "GenMsgSendType" BO_ 643 0;
BA_ "GenMsgCycleTime" BO_ 643 1000;

BA_ "GenMsgSendType" BO_ 646 0;
BA_ "GenMsgCycleTime" BO_ 646 1000;

BA_ "GenMsgSendType" BO_ 650 0;
BA_ "GenMsgCycleTime" BO_ 650 1000;

BA_ "GenMsgSendType" BO_ 651 0;
BA_ "GenMsgCycleTime" BO_ 651 1000;

BA_ "GenMsgSendType" BO_ 2 0;
BA_ "GenMsgCycleTime" BO_ 2 100;

BA_ "GenMsgSendType" BO_ 792 0;
BA_ "GenMsgCycleTime" BO_ 792 1000;

BA_ "GenMsgSendType" BO_ 794 0;
BA_ "GenMsgCycleTime" BO_ 794 1000;

BA_ "GenMsgSendType" BO_ 131 0;
BA_ "GenMsgCycleTime" BO_ 131 1000;

BA_ "GenMsgSendType" BO_ 793 0;
BA_ "GenMsgCycleTime" BO_ 793 1000;

BA_ "GenMsgSendType" BO_ 856 0;
BA_ "GenMsgCycleTime" BO_ 856 1000;

BA_ "GenMsgSendType" BO_ 824 0;
BA_ "GenMsgCycleTime" BO_ 824 1000;

BA_ "GenMsgSendType" BO_ 257 0;
BA_ "GenMsgCycleTime" BO_ 257 1000;

BA_ "GenMsgSendType" BO_ 808 0;
BA_ "GenMsgCycleTime" BO_ 808 1000;

BA_ "GenMsgSendType" BO_ 1528 0;
BA_ "GenMsgCycleTime" BO_ 1528 1000;

BA_ "GenMsgSendType" BO_ 1544 0;
BA_ "GenMsgCycleTime" BO_ 1544 1000;

BA_ "GenMsgSendType" BO_ 1496 0;
BA_ "GenMsgCycleTime" BO_ 1496 1000;

BA_ "GenMsgSendType" BO_ 1992 0;
BA_ "GenMsgCycleTime" BO_ 1992 1000;

BA_ "GenMsgSendType" BO_ 2040 0;
BA_ "GenMsgCycleTime" BO_ 2040 1000;

BA_ "GenMsgSendType" BO_ 49 0;
BA_ "GenMsgCycleTime" BO_ 49 500;

BA_ "GenMsgSendType" BO_ 60 0;
BA_ "GenMsgCycleTime" BO_ 60 10000;

BA_ "GenMsgSendType" BO_ 776 0;
BA_ "GenMsgCycleTime" BO_ 776 1000;

BA_ "GenMsgSendType" BO_ 14 0;
BA_ "GenMsgCycleTime" BO_ 14 10000;

BA_ "GenMsgSendType" BO_ 135 0;
BA_ "GenMsgCycleTime" BO_ 135 1000;

BA_ "GenMsgSendType" BO_ 136 0;
BA_ "GenMsgCycleTime" BO_ 136 1000;

BA_ "GenMsgSendType" BO_ 2038 0;
BA_ "GenMsgCycleTime" BO_ 2038 1000;

BA_ "GenMsgSendType" BO_ 27 0;
BA_ "GenMsgCycleTime" BO_ 27 1000;

BA_ "GenMsgSendType" BO_ 2028 0;
BA_ "GenMsgCycleTime" BO_ 2028 1000;

BA_ "GenMsgSendType" BO_ 857 0;
BA_ "GenMsgCycleTime" BO_ 857 1000;

BA_ "GenMsgSendType" BO_ 840 0;
BA_ "GenMsgCycleTime" BO_ 840 1000;

BA_ "GenMsgSendType" BO_ 59 0;
BA_ "GenMsgCycleTime" BO_ 59 10000;

BA_ "GenMsgSendType" BO_ 62 0;
BA_ "GenMsgCycleTime" BO_ 62 1000;

BA_ "GenMsgSendType" BO_ 1432 0;
BA_ "GenMsgCycleTime" BO_ 1432 1000;

BA_ "GenMsgSendType" BO_ 1464 0;
BA_ "GenMsgCycleTime" BO_ 1464 1000;

BA_ "GenMsgSendType" BO_ 1480 0;
BA_ "GenMsgCycleTime" BO_ 1480 1000;

BA_ "GenMsgSendType" BO_ 2008 0;
BA_ "GenMsgCycleTime" BO_ 2008 1000;

BA_ "GenMsgSendType" BO_ 2024 0;
BA_ "GenMsgCycleTime" BO_ 2024 1000;

BA_ "GenMsgSendType" BO_ 26 0;
BA_ "GenMsgCycleTime" BO_ 26 1000;

BA_ "GenMsgSendType" BO_ 19 0;
BA_ "GenMsgCycleTime" BO_ 19 400;

BA_ "GenMsgSendType" BO_ 861 0;
BA_ "GenMsgCycleTime" BO_ 861 1000;

BA_ "GenMsgSendType" BO_ 813 0;
BA_ "GenMsgCycleTime" BO_ 813 10000;

BA_ "GenMsgSendType" BO_ 925 0;
BA_ "GenMsgCycleTime" BO_ 925 1000;

BA_ "GenMsgSendType" BO_ 22 0;
BA_ "GenMsgCycleTime" BO_ 22 1000;

BA_ "GenMsgSendType" BO_ 844 0;
BA_ "GenMsgCycleTime" BO_ 844 1000;

BA_ "GenMsgSendType" BO_ 134 0;
BA_ "GenMsgCycleTime" BO_ 134 1000;

BA_ "GenMsgSendType" BO_ 539 0;
BA_ "GenMsgCycleTime" BO_ 539 100;

BA_ "GenMsgSendType" BO_ 860 0;
BA_ "GenMsgCycleTime" BO_ 860 1000;

BA_ "GenMsgSendType" BO_ 729 0;
BA_ "GenMsgCycleTime" BO_ 729 100;

BA_ "GenMsgSendType" BO_ 712 0;
BA_ "GenMsgCycleTime" BO_ 712 100;

BA_ "GenMsgSendType" BO_ 744 0;
BA_ "GenMsgCycleTime" BO_ 744 100;

BA_ "GenMsgSendType" BO_ 415 0;
BA_ "GenMsgCycleTime" BO_ 415 1000;

BA_ "GenMsgSendType" BO_ 728 0;
BA_ "GenMsgCycleTime" BO_ 728 500;

BA_ "GenMsgSendType" BO_ 50 0;
BA_ "GenMsgCycleTime" BO_ 50 100;

BA_ "GenMsgSendType" BO_ 54 0;
BA_ "GenMsgCycleTime" BO_ 54 1000;

BA_ "GenMsgSendType" BO_ 552 0;
BA_ "GenMsgCycleTime" BO_ 552 500;

VAL_ 1351 EPBM_infoIndex 0 "DEPRECATED_0" 1 "DEPRECATED_1" 2 "DEPRECATED_2" 3 "DEPRECATED_3" 4 "DEPRECATED_4" 5 "DEPRECATED_5" 6 "DEPRECATED_6" 7 "DEPRECATED_7" 8 "DEPRECATED_8" 9 "DEPRECATED_9" 10 "BUILD_HWID_COMPONENTID" 11 "PCBAID_ASSYID_USAGEID" 13 "APP_CRC" 14 "BOOTLOADER_SVN" 15 "BOOTLOADER_CRC" 16 "SUBCOMPONENT" 17 "APP_GITHASH" 18 "BOOTLOADER_GITHASH" 19 "VERSION_DEPRECATED" 20 "UDS_PROTOCOL_BOOTCRC" 255 "END";
VAL_ 1351 EPBM_infoHardwareRevision 252 "CONFIGURABLE_HWID_PLACEHOLDER";

VAL_ 551 EPBM_calibrationStateLeft 0 "UNAVAILABLE" 1 "NORMAL" 2 "WARN" 3 "FAULT" 4 "BUSY";
VAL_ 551 EPBM_calibrationStateRight 0 "UNAVAILABLE" 1 "NORMAL" 2 "WARN" 3 "FAULT" 4 "BUSY";
VAL_ 551 EPBM_clampCurrentMonitor 0 "MONITOR_IDLE" 2 "TARGET_REACHED" 3 "TARGET_NOT_REACHED";
VAL_ 551 EPBM_selfParkState 0 "INIT" 1 "IDLE" 2 "ARMED" 3 "ACTIVE" 4 "COMPLETE" 5 "FAULT";
VAL_ 551 EPBM_state 0 "OPEN" 1 "DYNAMIC" 2 "PARK" 3 "HANDBRAKE" 4 "START" 5 "SERVICE" 6 "SELFPARK" 7 "SNA";
VAL_ 551 EPBM_statePending 0 "OPEN" 1 "DYNAMIC" 2 "PARK" 3 "HANDBRAKE" 4 "START" 5 "SERVICE" 6 "SELFPARK" 7 "SNA";
VAL_ 551 EPBM_stateRequest 0 "OPEN" 1 "DYNAMIC" 2 "PARK" 3 "HANDBRAKE" 4 "START" 5 "SERVICE" 6 "SELFPARK" 7 "SNA";
VAL_ 551 EPBM_substateL 0 "STATIONARY" 1 "APPLYING" 2 "RELEASING" 3 "FAULT" 4 "CTRL_FAULT";
VAL_ 551 EPBM_substateR 0 "STATIONARY" 1 "APPLYING" 2 "RELEASING" 3 "FAULT" 4 "CTRL_FAULT";
VAL_ 551 EPBM_syncState 0 "INIT" 1 "LOSTSYNC" 2 "SYNCING" 3 "READY";

VAL_ 1431 EPBM_componentHardwareRevision 252 "CONFIGURABLE_HWID_PLACEHOLDER";

VAL_ 1332 EPB_infoIndex 0 "DEPRECATED_0" 1 "DEPRECATED_1" 2 "DEPRECATED_2" 3 "DEPRECATED_3" 4 "DEPRECATED_4" 5 "DEPRECATED_5" 6 "DEPRECATED_6" 7 "DEPRECATED_7" 8 "DEPRECATED_8" 9 "DEPRECATED_9" 10 "BUILD_HWID_COMPONENTID" 11 "PCBAID_ASSYID_USAGEID" 13 "APP_CRC" 14 "BOOTLOADER_SVN" 15 "BOOTLOADER_CRC" 16 "SUBCOMPONENT" 17 "APP_GITHASH" 18 "BOOTLOADER_GITHASH" 19 "VERSION_DEPRECATED" 20 "UDS_PROTOCOL_BOOTCRC" 255 "END";
VAL_ 1332 EPB_infoHardwareRevision 252 "CONFIGURABLE_HWID_PLACEHOLDER";

VAL_ 516 EPB_brakeApplied 0 "RELEASED" 1 "APPLIED" 3 "SNA";
VAL_ 516 EPB_calibrationStateLeft 0 "UNAVAILABLE" 1 "NORMAL" 2 "WARN" 3 "FAULT" 4 "BUSY";
VAL_ 516 EPB_calibrationStateRight 0 "UNAVAILABLE" 1 "NORMAL" 2 "WARN" 3 "FAULT" 4 "BUSY";
VAL_ 516 EPB_ignoreCan 0 "IGNORE_CAN_BOOT" 1 "LISTEN_TO_CAN" 2 "IGNORE_CAN_UPDATE" 3 "IGNORE_CAN_SNA";
VAL_ 516 EPB_selfParkState 0 "INIT" 1 "IDLE" 2 "ARMED" 3 "ACTIVE" 4 "COMPLETE" 5 "FAULT";
VAL_ 516 EPB_state 0 "OPEN" 1 "DYNAMIC" 2 "PARK" 3 "HANDBRAKE" 4 "START" 5 "SERVICE" 6 "SELFPARK" 7 "SNA";
VAL_ 516 EPB_statePending 0 "OPEN" 1 "DYNAMIC" 2 "PARK" 3 "HANDBRAKE" 4 "START" 5 "SERVICE" 6 "SELFPARK" 7 "SNA";
VAL_ 516 EPB_stateRequest 0 "OPEN" 1 "DYNAMIC" 2 "PARK" 3 "HANDBRAKE" 4 "START" 5 "SERVICE" 6 "SELFPARK" 7 "SNA";
VAL_ 516 EPB_substateL 0 "STATIONARY" 1 "APPLYING" 2 "RELEASING" 3 "FAULT" 4 "CLR_FAULT";
VAL_ 516 EPB_substateR 0 "STATIONARY" 1 "APPLYING" 2 "RELEASING" 3 "FAULT" 4 "CLR_FAULT";
VAL_ 516 EPB_syncState 0 "INIT" 1 "LOSTSYNC" 2 "SYNCING" 3 "READY";
VAL_ 516 EPB_telltale 0 "LAMP_OFF" 1 "LAMP_RED_ON" 2 "LAMP_AMBER_ON" 3 "LAMP_RED_FLASH_AMBER_ON" 7 "EPB_TELLTALE_SNA";

VAL_ 1428 EPB_componentHardwareRevision 252 "CONFIGURABLE_HWID_PLACEHOLDER";

VAL_ 293 Lat_Acceleration 127 "SNA";
VAL_ 293 Long_Acceleration 127 "SNA";

VAL_ 56 ESP_absBrakeEvent 0 "NOT_ACTIVE" 1 "ACTIVE";
VAL_ 56 ESP_absFaultLamp 0 "OFF" 1 "ON";
VAL_ 56 ESP_brakeDiscWipingActive 0 "INACTIVE" 1 "ACTIVE";
VAL_ 56 ESP_brakeLamp 0 "OFF" 1 "ON";
VAL_ 56 ESP_espFaultLamp 0 "OFF" 1 "ON";
VAL_ 56 ESP_espLampFlash 0 "OFF" 1 "FLASH";
VAL_ 56 ESP_espOffLamp 0 "OFF" 1 "ON";
VAL_ 56 ESP_hillStartAssistActive 0 "INACTIVE" 1 "ACTIVE" 2 "NOT_AVAILABLE" 3 "SNA";
VAL_ 56 ESP_stabilityControlSts 0 "OFF" 1 "ON" 2 "ENGAGED" 3 "FAULTED" 4 "NOT_CONFIGURED" 5 "INIT";
VAL_ 56 ESP_tcLampFlash 0 "OFF" 1 "FLASH";

VAL_ 325 ESP_absBrakeEvent2 0 "NOT_ACTIVE" 1 "ACTIVE_FRONT_REAR" 2 "ACTIVE_FRONT" 3 "ACTIVE_REAR";
VAL_ 325 ESP_brakeMasterCylPress 1023 "PRESSURE_SNA";
VAL_ 325 ESP_brakeMasterCylPressQF 0 "UNDEFINABLE_ACCURACY" 1 "IN_SPEC";
VAL_ 325 ESP_btcTargetState 0 "OFF" 1 "BACKUP" 2 "ON" 3 "SNA";
VAL_ 325 ESP_espModeActive 0 "MODE_00_NORMAL" 1 "MODE_01_TC_OFF" 2 "ESP_DEV_MODE_1" 3 "ESP_DEV_MODE_2";
VAL_ 325 ESP_lateralAccel 1023 "SNA";
VAL_ 325 ESP_lateralAccelQF 0 "UNDEFINABLE_ACCURACY" 1 "EVAL_IN_PROGRESS" 2 "NOT_WITHIN_SPECIFICATION" 3 "IN_SPEC";
VAL_ 325 ESP_longitudinalAccel 1023 "SNA";
VAL_ 325 ESP_longitudinalAccelQF 0 "UNDEFINABLE_ACCURACY" 1 "EVAL_IN_PROGRESS" 2 "NOT_WITHIN_SPECIFICATION" 3 "IN_SPEC";
VAL_ 325 ESP_ptcTargetState 0 "FAULT" 1 "BACKUP" 2 "ON" 3 "SNA";
VAL_ 325 ESP_stabilityControlSts2 0 "OFF" 1 "ON" 2 "ENGAGED" 3 "FAULTED" 4 "NOT_CONFIGURED" 5 "INIT" 7 "SNA";
VAL_ 325 ESP_vehicleStandstillSts 0 "Not_Standstill" 1 "Standstill";
VAL_ 325 ESP_wheelSpeedsQF 0 "ONE_OR_MORE_WSS_INVALID" 1 "ALL_WSS_VALID";

VAL_ 1 ESP_BCounter 0 "COUNT_0";
VAL_ 1 ESP_vehicleSpeedQF 0 "UNDEFINABLE_ACCURACY_SNA" 3 "IN_SPEC";
VAL_ 1 ESP_wheelPulseCountFrL 255 "SNA";
VAL_ 1 ESP_wheelPulseCountFrR 255 "SNA";
VAL_ 1 ESP_wheelPulseCountReL 255 "SNA";
VAL_ 1 ESP_wheelPulseCountReR 255 "SNA";

VAL_ 504 ESP_driverBrakeApply 0 "NotInit_orOff" 1 "Not_Applied" 2 "Driver_applying_brakes" 3 "Faulty_SNA";
VAL_ 504 ESP_yawRate 4095 "SNA";

VAL_ 949 ESP_d000_absPumpMotorControl 0 "NOT_TESTED_DTC" 1 "PASSED_DTC" 2 "FAILED_DTC" 3 "UNABLE_TO_TEST_DTC";
VAL_ 949 ESP_d001_wssFLLineGnd 0 "NOT_TESTED_DTC" 1 "PASSED_DTC" 2 "FAILED_DTC" 3 "UNABLE_TO_TEST_DTC";
VAL_ 949 ESP_d002_wssFLLineHigh 0 "NOT_TESTED_DTC" 1 "PASSED_DTC" 2 "FAILED_DTC" 3 "UNABLE_TO_TEST_DTC";
VAL_ 949 ESP_d003_wssFLLineUndef 0 "NOT_TESTED_DTC" 1 "PASSED_DTC" 2 "FAILED_DTC" 3 "UNABLE_TO_TEST_DTC";
VAL_ 949 ESP_d004_wssFLOutOfRange 0 "NOT_TESTED_DTC" 1 "PASSED_DTC" 2 "FAILED_DTC" 3 "UNABLE_TO_TEST_DTC";
VAL_ 949 ESP_d005_wssFLSignalMissing 0 "NOT_TESTED_DTC" 1 "PASSED_DTC" 2 "FAILED_DTC" 3 "UNABLE_TO_TEST_DTC";
VAL_ 949 ESP_d006_wssFLWrongSen 0 "NOT_TESTED_DTC" 1 "PASSED_DTC" 2 "FAILED_DTC" 3 "UNABLE_TO_TEST_DTC";
VAL_ 949 ESP_d007_wssFLPlausibility 0 "NOT_TESTED_DTC" 1 "PASSED_DTC" 2 "FAILED_DTC" 3 "UNABLE_TO_TEST_DTC";
VAL_ 949 ESP_d008_wssFAWrongMounting 0 "NOT_TESTED_DTC" 1 "PASSED_DTC" 2 "FAILED_DTC" 3 "UNABLE_TO_TEST_DTC";
VAL_ 949 ESP_d009_wssFLAirGap 0 "NOT_TESTED_DTC" 1 "PASSED_DTC" 2 "FAILED_DTC" 3 "UNABLE_TO_TEST_DTC";
VAL_ 949 ESP_d010_wssFLSupGnd 0 "NOT_TESTED_DTC" 1 "PASSED_DTC" 2 "FAILED_DTC" 3 "UNABLE_TO_TEST_DTC";
VAL_ 949 ESP_d011_wssTstFLFld 0 "NOT_TESTED_DTC" 1 "PASSED_DTC" 2 "FAILED_DTC" 3 "UNABLE_TO_TEST_DTC";
VAL_ 949 ESP_d012_wssFRLineGnd 0 "NOT_TESTED_DTC" 1 "PASSED_DTC" 2 "FAILED_DTC" 3 "UNABLE_TO_TEST_DTC";
VAL_ 949 ESP_d013_wssFRLineHigh 0 "NOT_TESTED_DTC" 1 "PASSED_DTC" 2 "FAILED_DTC" 3 "UNABLE_TO_TEST_DTC";
VAL_ 949 ESP_d014_wssFRLineUndef 0 "NOT_TESTED_DTC" 1 "PASSED_DTC" 2 "FAILED_DTC" 3 "UNABLE_TO_TEST_DTC";
VAL_ 949 ESP_d015_wssFROutOfRange 0 "NOT_TESTED_DTC" 1 "PASSED_DTC" 2 "FAILED_DTC" 3 "UNABLE_TO_TEST_DTC";
VAL_ 949 ESP_d016_wssFRSignalMissing 0 "NOT_TESTED_DTC" 1 "PASSED_DTC" 2 "FAILED_DTC" 3 "UNABLE_TO_TEST_DTC";
VAL_ 949 ESP_d017_wssFRWrongSen 0 "NOT_TESTED_DTC" 1 "PASSED_DTC" 2 "FAILED_DTC" 3 "UNABLE_TO_TEST_DTC";
VAL_ 949 ESP_d018_wssFRPlausibility 0 "NOT_TESTED_DTC" 1 "PASSED_DTC" 2 "FAILED_DTC" 3 "UNABLE_TO_TEST_DTC";
VAL_ 949 ESP_d019_wssMonWheelDirFR 0 "NOT_TESTED_DTC" 1 "PASSED_DTC" 2 "FAILED_DTC" 3 "UNABLE_TO_TEST_DTC";
VAL_ 949 ESP_d020_wssFRAirGap 0 "NOT_TESTED_DTC" 1 "PASSED_DTC" 2 "FAILED_DTC" 3 "UNABLE_TO_TEST_DTC";
VAL_ 949 ESP_d021_wssFRSupGnd 0 "NOT_TESTED_DTC" 1 "PASSED_DTC" 2 "FAILED_DTC" 3 "UNABLE_TO_TEST_DTC";
VAL_ 949 ESP_d022_wssTstFRFld 0 "NOT_TESTED_DTC" 1 "PASSED_DTC" 2 "FAILED_DTC" 3 "UNABLE_TO_TEST_DTC";
VAL_ 949 ESP_d023_wssRLLineGnd 0 "NOT_TESTED_DTC" 1 "PASSED_DTC" 2 "FAILED_DTC" 3 "UNABLE_TO_TEST_DTC";
VAL_ 949 ESP_d024_wssRLLineHigh 0 "NOT_TESTED_DTC" 1 "PASSED_DTC" 2 "FAILED_DTC" 3 "UNABLE_TO_TEST_DTC";
VAL_ 949 ESP_d025_wssRLLineUndef 0 "NOT_TESTED_DTC" 1 "PASSED_DTC" 2 "FAILED_DTC" 3 "UNABLE_TO_TEST_DTC";
VAL_ 949 ESP_d026_wssRLOutOfRange 0 "NOT_TESTED_DTC" 1 "PASSED_DTC" 2 "FAILED_DTC" 3 "UNABLE_TO_TEST_DTC";
VAL_ 949 ESP_d027_wssRLSignalMissing 0 "NOT_TESTED_DTC" 1 "PASSED_DTC" 2 "FAILED_DTC" 3 "UNABLE_TO_TEST_DTC";
VAL_ 949 ESP_d028_wssRLWrongSen 0 "NOT_TESTED_DTC" 1 "PASSED_DTC" 2 "FAILED_DTC" 3 "UNABLE_TO_TEST_DTC";
VAL_ 949 ESP_d029_wssRLPlausibility 0 "NOT_TESTED_DTC" 1 "PASSED_DTC" 2 "FAILED_DTC" 3 "UNABLE_TO_TEST_DTC";
VAL_ 949 ESP_d030_wssRAWrongMounting 0 "NOT_TESTED_DTC" 1 "PASSED_DTC" 2 "FAILED_DTC" 3 "UNABLE_TO_TEST_DTC";
VAL_ 949 ESP_d031_wssRLAirGap 0 "NOT_TESTED_DTC" 1 "PASSED_DTC" 2 "FAILED_DTC" 3 "UNABLE_TO_TEST_DTC";
VAL_ 949 ESP_d032_wssRLSupGnd 0 "NOT_TESTED_DTC" 1 "PASSED_DTC" 2 "FAILED_DTC" 3 "UNABLE_TO_TEST_DTC";
VAL_ 949 ESP_d033_wssTstRLFld 0 "NOT_TESTED_DTC" 1 "PASSED_DTC" 2 "FAILED_DTC" 3 "UNABLE_TO_TEST_DTC";
VAL_ 949 ESP_d034_wssRRLineGnd 0 "NOT_TESTED_DTC" 1 "PASSED_DTC" 2 "FAILED_DTC" 3 "UNABLE_TO_TEST_DTC";
VAL_ 949 ESP_d035_wssRRLineHigh 0 "NOT_TESTED_DTC" 1 "PASSED_DTC" 2 "FAILED_DTC" 3 "UNABLE_TO_TEST_DTC";
VAL_ 949 ESP_d036_wssRRLineUndef 0 "NOT_TESTED_DTC" 1 "PASSED_DTC" 2 "FAILED_DTC" 3 "UNABLE_TO_TEST_DTC";
VAL_ 949 ESP_d037_wssRROutOfRange 0 "NOT_TESTED_DTC" 1 "PASSED_DTC" 2 "FAILED_DTC" 3 "UNABLE_TO_TEST_DTC";
VAL_ 949 ESP_d038_wssRRSignalMissing 0 "NOT_TESTED_DTC" 1 "PASSED_DTC" 2 "FAILED_DTC" 3 "UNABLE_TO_TEST_DTC";
VAL_ 949 ESP_d039_wssRRWrongSen 0 "NOT_TESTED_DTC" 1 "PASSED_DTC" 2 "FAILED_DTC" 3 "UNABLE_TO_TEST_DTC";
VAL_ 949 ESP_d040_wssRRPlausibility 0 "NOT_TESTED_DTC" 1 "PASSED_DTC" 2 "FAILED_DTC" 3 "UNABLE_TO_TEST_DTC";
VAL_ 949 ESP_d041_wssMonWheelDirRR 0 "NOT_TESTED_DTC" 1 "PASSED_DTC" 2 "FAILED_DTC" 3 "UNABLE_TO_TEST_DTC";
VAL_ 949 ESP_d042_wssRRAirGap 0 "NOT_TESTED_DTC" 1 "PASSED_DTC" 2 "FAILED_DTC" 3 "UNABLE_TO_TEST_DTC";
VAL_ 949 ESP_d043_wssRRSupGnd 0 "NOT_TESTED_DTC" 1 "PASSED_DTC" 2 "FAILED_DTC" 3 "UNABLE_TO_TEST_DTC";
VAL_ 949 ESP_d044_wssTstRRFld 0 "NOT_TESTED_DTC" 1 "PASSED_DTC" 2 "FAILED_DTC" 3 "UNABLE_TO_TEST_DTC";
VAL_ 949 ESP_d045_wssGeneralFault 0 "NOT_TESTED_DTC" 1 "PASSED_DTC" 2 "FAILED_DTC" 3 "UNABLE_TO_TEST_DTC";
VAL_ 949 ESP_d046_brakeSwitchStuckHigh 0 "NOT_TESTED_DTC" 1 "PASSED_DTC" 2 "FAILED_DTC" 3 "UNABLE_TO_TEST_DTC";
VAL_ 949 ESP_d047_blsStatusInvd 0 "NOT_TESTED_DTC" 1 "PASSED_DTC" 2 "FAILED_DTC" 3 "UNABLE_TO_TEST_DTC";
VAL_ 949 ESP_d048_brakeSwitchPlausib 0 "NOT_TESTED_DTC" 1 "PASSED_DTC" 2 "FAILED_DTC" 3 "UNABLE_TO_TEST_DTC";
VAL_ 949 ESP_d049_pressSenMc1Line 0 "NOT_TESTED_DTC" 1 "PASSED_DTC" 2 "FAILED_DTC" 3 "UNABLE_TO_TEST_DTC";
VAL_ 949 ESP_d050_acmPsOfstMc1 0 "NOT_TESTED_DTC" 1 "PASSED_DTC" 2 "FAILED_DTC" 3 "UNABLE_TO_TEST_DTC";
VAL_ 949 ESP_d051_acmPsTstpulseMc1 0 "NOT_TESTED_DTC" 1 "PASSED_DTC" 2 "FAILED_DTC" 3 "UNABLE_TO_TEST_DTC";
VAL_ 949 ESP_d052_comSclLowBrakeFluid 0 "NOT_TESTED_DTC" 1 "PASSED_DTC" 2 "FAILED_DTC" 3 "UNABLE_TO_TEST_DTC";
VAL_ 949 ESP_d053_sasMonConstSig 0 "NOT_TESTED_DTC" 1 "PASSED_DTC" 2 "FAILED_DTC" 3 "UNABLE_TO_TEST_DTC";
VAL_ 949 ESP_d054_sasMonOfst 0 "NOT_TESTED_DTC" 1 "PASSED_DTC" 2 "FAILED_DTC" 3 "UNABLE_TO_TEST_DTC";
VAL_ 949 ESP_d055_sasPlausibility 0 "NOT_TESTED_DTC" 1 "PASSED_DTC" 2 "FAILED_DTC" 3 "UNABLE_TO_TEST_DTC";
VAL_ 949 ESP_d056_aySensorFault 0 "NOT_TESTED_DTC" 1 "PASSED_DTC" 2 "FAILED_DTC" 3 "UNABLE_TO_TEST_DTC";
VAL_ 949 ESP_d057_aysMonRange 0 "NOT_TESTED_DTC" 1 "PASSED_DTC" 2 "FAILED_DTC" 3 "UNABLE_TO_TEST_DTC";
VAL_ 949 ESP_d058_aysOffset 0 "NOT_TESTED_DTC" 1 "PASSED_DTC" 2 "FAILED_DTC" 3 "UNABLE_TO_TEST_DTC";
VAL_ 949 ESP_d059_aysPlaus 0 "NOT_TESTED_DTC" 1 "PASSED_DTC" 2 "FAILED_DTC" 3 "UNABLE_TO_TEST_DTC";
VAL_ 949 ESP_d060_axSensorFault 0 "NOT_TESTED_DTC" 1 "PASSED_DTC" 2 "FAILED_DTC" 3 "UNABLE_TO_TEST_DTC";
VAL_ 949 ESP_d061_axsMonRange 0 "NOT_TESTED_DTC" 1 "PASSED_DTC" 2 "FAILED_DTC" 3 "UNABLE_TO_TEST_DTC";
VAL_ 949 ESP_d062_axOffsTooLarge 0 "NOT_TESTED_DTC" 1 "PASSED_DTC" 2 "FAILED_DTC" 3 "UNABLE_TO_TEST_DTC";
VAL_ 949 ESP_d063_axSensorPlaus 0 "NOT_TESTED_DTC" 1 "PASSED_DTC" 2 "FAILED_DTC" 3 "UNABLE_TO_TEST_DTC";
VAL_ 949 ESP_d064_yawSensorFault 0 "NOT_TESTED_DTC" 1 "PASSED_DTC" 2 "FAILED_DTC" 3 "UNABLE_TO_TEST_DTC";
VAL_ 949 ESP_d065_yawSensorPlaus 0 "NOT_TESTED_DTC" 1 "PASSED_DTC" 2 "FAILED_DTC" 3 "UNABLE_TO_TEST_DTC";
VAL_ 949 ESP_d066_absVdcContControl 0 "NOT_TESTED_DTC" 1 "PASSED_DTC" 2 "FAILED_DTC" 3 "UNABLE_TO_TEST_DTC";
VAL_ 949 ESP_d067_undervoltage 0 "NOT_TESTED_DTC" 1 "PASSED_DTC" 2 "FAILED_DTC" 3 "UNABLE_TO_TEST_DTC";
VAL_ 949 ESP_d068_overvoltage 0 "NOT_TESTED_DTC" 1 "PASSED_DTC" 2 "FAILED_DTC" 3 "UNABLE_TO_TEST_DTC";
VAL_ 949 ESP_d069_memoryFault 0 "NOT_TESTED_DTC" 1 "PASSED_DTC" 2 "FAILED_DTC" 3 "UNABLE_TO_TEST_DTC";
VAL_ 949 ESP_d070_ecuInternalGeneric 0 "NOT_TESTED_DTC" 1 "PASSED_DTC" 2 "FAILED_DTC" 3 "UNABLE_TO_TEST_DTC";
VAL_ 949 ESP_d071_ecuInternalEcu 0 "NOT_TESTED_DTC" 1 "PASSED_DTC" 2 "FAILED_DTC" 3 "UNABLE_TO_TEST_DTC";
VAL_ 949 ESP_d072_valveGeneric 0 "NOT_TESTED_DTC" 1 "PASSED_DTC" 2 "FAILED_DTC" 3 "UNABLE_TO_TEST_DTC";
VAL_ 949 ESP_d073_valveAvFaults 0 "NOT_TESTED_DTC" 1 "PASSED_DTC" 2 "FAILED_DTC" 3 "UNABLE_TO_TEST_DTC";
VAL_ 949 ESP_d074_valveEvFaults 0 "NOT_TESTED_DTC" 1 "PASSED_DTC" 2 "FAILED_DTC" 3 "UNABLE_TO_TEST_DTC";
VAL_ 949 ESP_d075_valveHsvFaults 0 "NOT_TESTED_DTC" 1 "PASSED_DTC" 2 "FAILED_DTC" 3 "UNABLE_TO_TEST_DTC";
VAL_ 949 ESP_d076_valveUsvFaults 0 "NOT_TESTED_DTC" 1 "PASSED_DTC" 2 "FAILED_DTC" 3 "UNABLE_TO_TEST_DTC";
VAL_ 949 ESP_d077_refNotInitInTime 0 "NOT_TESTED_DTC" 1 "PASSED_DTC" 2 "FAILED_DTC" 3 "UNABLE_TO_TEST_DTC";
VAL_ 949 ESP_d078_acmBtmOheatBraking 0 "NOT_TESTED_DTC" 1 "PASSED_DTC" 2 "FAILED_DTC" 3 "UNABLE_TO_TEST_DTC";
VAL_ 949 ESP_d079_varCodeEeprom 0 "NOT_TESTED_DTC" 1 "PASSED_DTC" 2 "FAILED_DTC" 3 "UNABLE_TO_TEST_DTC";
VAL_ 949 ESP_d080_reverseGearPlaus 0 "NOT_TESTED_DTC" 1 "PASSED_DTC" 2 "FAILED_DTC" 3 "UNABLE_TO_TEST_DTC";
VAL_ 949 ESP_d081_comSclVinAllZeroFF 0 "NOT_TESTED_DTC" 1 "PASSED_DTC" 2 "FAILED_DTC" 3 "UNABLE_TO_TEST_DTC";
VAL_ 949 ESP_d082_comSclVip405HsImpVin 0 "NOT_TESTED_DTC" 1 "PASSED_DTC" 2 "FAILED_DTC" 3 "UNABLE_TO_TEST_DTC";
VAL_ 949 ESP_d083_comSclVip405HsDtCrpt 0 "NOT_TESTED_DTC" 1 "PASSED_DTC" 2 "FAILED_DTC" 3 "UNABLE_TO_TEST_DTC";
VAL_ 949 ESP_d084_comSclVip405HsTout 0 "NOT_TESTED_DTC" 1 "PASSED_DTC" 2 "FAILED_DTC" 3 "UNABLE_TO_TEST_DTC";
VAL_ 949 ESP_d085_rollerBenchActv 0 "NOT_TESTED_DTC" 1 "PASSED_DTC" 2 "FAILED_DTC" 3 "UNABLE_TO_TEST_DTC";
VAL_ 949 ESP_d086_network0 0 "NOT_TESTED_DTC" 1 "PASSED_DTC" 2 "FAILED_DTC" 3 "UNABLE_TO_TEST_DTC";
VAL_ 949 ESP_d087_network1 0 "NOT_TESTED_DTC" 1 "PASSED_DTC" 2 "FAILED_DTC" 3 "UNABLE_TO_TEST_DTC";
VAL_ 949 ESP_d088_comMotorTOut 0 "NOT_TESTED_DTC" 1 "PASSED_DTC" 2 "FAILED_DTC" 3 "UNABLE_TO_TEST_DTC";
VAL_ 949 ESP_d089_comDrsTxTOut 0 "NOT_TESTED_DTC" 1 "PASSED_DTC" 2 "FAILED_DTC" 3 "UNABLE_TO_TEST_DTC";
VAL_ 949 ESP_d090_comSclStwAnglhpTout 0 "NOT_TESTED_DTC" 1 "PASSED_DTC" 2 "FAILED_DTC" 3 "UNABLE_TO_TEST_DTC";
VAL_ 949 ESP_d091_comSclEpbStatusTout 0 "NOT_TESTED_DTC" 1 "PASSED_DTC" 2 "FAILED_DTC" 3 "UNABLE_TO_TEST_DTC";
VAL_ 949 ESP_d092_comIbEsptTOut 0 "NOT_TESTED_DTC" 1 "PASSED_DTC" 2 "FAILED_DTC" 3 "UNABLE_TO_TEST_DTC";
VAL_ 949 ESP_d093_comSclBdyStatusTout 0 "NOT_TESTED_DTC" 1 "PASSED_DTC" 2 "FAILED_DTC" 3 "UNABLE_TO_TEST_DTC";
VAL_ 949 ESP_d094_comSclGtwEsp1Tout 0 "NOT_TESTED_DTC" 1 "PASSED_DTC" 2 "FAILED_DTC" 3 "UNABLE_TO_TEST_DTC";
VAL_ 949 ESP_d095_comSclGtwOdoTout 0 "NOT_TESTED_DTC" 1 "PASSED_DTC" 2 "FAILED_DTC" 3 "UNABLE_TO_TEST_DTC";
VAL_ 949 ESP_d096_comSclGtwCarCfgTout 0 "NOT_TESTED_DTC" 1 "PASSED_DTC" 2 "FAILED_DTC" 3 "UNABLE_TO_TEST_DTC";
VAL_ 949 ESP_d097_comMotorCrpt 0 "NOT_TESTED_DTC" 1 "PASSED_DTC" 2 "FAILED_DTC" 3 "UNABLE_TO_TEST_DTC";
VAL_ 949 ESP_d098_comMotorMsgCount 0 "NOT_TESTED_DTC" 1 "PASSED_DTC" 2 "FAILED_DTC" 3 "UNABLE_TO_TEST_DTC";
VAL_ 949 ESP_d099_comMotorInvalidSig 0 "NOT_TESTED_DTC" 1 "PASSED_DTC" 2 "FAILED_DTC" 3 "UNABLE_TO_TEST_DTC";
VAL_ 949 ESP_d100_comSclEpbStatusCrpt 0 "NOT_TESTED_DTC" 1 "PASSED_DTC" 2 "FAILED_DTC" 3 "UNABLE_TO_TEST_DTC";
VAL_ 949 ESP_d101_comIbEspCrpt 0 "NOT_TESTED_DTC" 1 "PASSED_DTC" 2 "FAILED_DTC" 3 "UNABLE_TO_TEST_DTC";
VAL_ 949 ESP_d102_comIbEspMsgCount 0 "NOT_TESTED_DTC" 1 "PASSED_DTC" 2 "FAILED_DTC" 3 "UNABLE_TO_TEST_DTC";
VAL_ 949 ESP_d103_sclIbEspInvalidSig 0 "NOT_TESTED_DTC" 1 "PASSED_DTC" 2 "FAILED_DTC" 3 "UNABLE_TO_TEST_DTC";
VAL_ 949 ESP_d104_comSclBdyStatusCrpt 0 "NOT_TESTED_DTC" 1 "PASSED_DTC" 2 "FAILED_DTC" 3 "UNABLE_TO_TEST_DTC";
VAL_ 949 ESP_d105_comStwAnglHpCrpt 0 "NOT_TESTED_DTC" 1 "PASSED_DTC" 2 "FAILED_DTC" 3 "UNABLE_TO_TEST_DTC";
VAL_ 949 ESP_d106_comStwAnglHpMsgCount 0 "NOT_TESTED_DTC" 1 "PASSED_DTC" 2 "FAILED_DTC" 3 "UNABLE_TO_TEST_DTC";
VAL_ 949 ESP_d107_comSasInvalidSig 0 "NOT_TESTED_DTC" 1 "PASSED_DTC" 2 "FAILED_DTC" 3 "UNABLE_TO_TEST_DTC";
VAL_ 949 ESP_d108_comDrsTxCrpt 0 "NOT_TESTED_DTC" 1 "PASSED_DTC" 2 "FAILED_DTC" 3 "UNABLE_TO_TEST_DTC";
VAL_ 949 ESP_d109_sclMm3InvalidSig 0 "NOT_TESTED_DTC" 1 "PASSED_DTC" 2 "FAILED_DTC" 3 "UNABLE_TO_TEST_DTC";
VAL_ 949 ESP_d110_comGtwEsp1Crpt 0 "NOT_TESTED_DTC" 1 "PASSED_DTC" 2 "FAILED_DTC" 3 "UNABLE_TO_TEST_DTC";
VAL_ 949 ESP_d111_comSclGtwEsp1CntFlt 0 "NOT_TESTED_DTC" 1 "PASSED_DTC" 2 "FAILED_DTC" 3 "UNABLE_TO_TEST_DTC";
VAL_ 949 ESP_d112_comSclGtwOdoDtCrpt 0 "NOT_TESTED_DTC" 1 "PASSED_DTC" 2 "FAILED_DTC" 3 "UNABLE_TO_TEST_DTC";
VAL_ 949 ESP_d113_comSclGtwCrCfgDtCrpt 0 "NOT_TESTED_DTC" 1 "PASSED_DTC" 2 "FAILED_DTC" 3 "UNABLE_TO_TEST_DTC";
VAL_ 949 ESP_d114_teslaChassisTypeSna 0 "NOT_TESTED_DTC" 1 "PASSED_DTC" 2 "FAILED_DTC" 3 "UNABLE_TO_TEST_DTC";
VAL_ 949 ESP_d115_varPlatCalMismtch 0 "NOT_TESTED_DTC" 1 "PASSED_DTC" 2 "FAILED_DTC" 3 "UNABLE_TO_TEST_DTC";
VAL_ 949 ESP_d116_ptsBlsStatusInvd 0 "NOT_TESTED_DTC" 1 "PASSED_DTC" 2 "FAILED_DTC" 3 "UNABLE_TO_TEST_DTC";
VAL_ 949 ESP_d117_comSclBdwReqInvalid 0 "NOT_TESTED_DTC" 1 "PASSED_DTC" 2 "FAILED_DTC" 3 "UNABLE_TO_TEST_DTC";
VAL_ 949 ESP_d118_rcmInvalidAx 0 "NOT_TESTED_DTC" 1 "PASSED_DTC" 2 "FAILED_DTC" 3 "UNABLE_TO_TEST_DTC";
VAL_ 949 ESP_d119_rcmInvalidAy 0 "NOT_TESTED_DTC" 1 "PASSED_DTC" 2 "FAILED_DTC" 3 "UNABLE_TO_TEST_DTC";
VAL_ 949 ESP_d120_rcmInvalidYaw 0 "NOT_TESTED_DTC" 1 "PASSED_DTC" 2 "FAILED_DTC" 3 "UNABLE_TO_TEST_DTC";
VAL_ 949 ESP_d121_rcmInvalidFrame1 0 "NOT_TESTED_DTC" 1 "PASSED_DTC" 2 "FAILED_DTC" 3 "UNABLE_TO_TEST_DTC";
VAL_ 949 ESP_d122_rcmInvalidFrame2 0 "NOT_TESTED_DTC" 1 "PASSED_DTC" 2 "FAILED_DTC" 3 "UNABLE_TO_TEST_DTC";
VAL_ 949 ESP_d123_rcmLostComm 0 "NOT_TESTED_DTC" 1 "PASSED_DTC" 2 "FAILED_DTC" 3 "UNABLE_TO_TEST_DTC";
VAL_ 949 ESP_d124_rcmIncompleteSensInfo 0 "NOT_TESTED_DTC" 1 "PASSED_DTC" 2 "FAILED_DTC" 3 "UNABLE_TO_TEST_DTC";
VAL_ 949 ESP_d125_rcmSerialNumMismatch 0 "NOT_TESTED_DTC" 1 "PASSED_DTC" 2 "FAILED_DTC" 3 "UNABLE_TO_TEST_DTC";
VAL_ 949 ESP_d126_rcmWrongSensorConfig 0 "NOT_TESTED_DTC" 1 "PASSED_DTC" 2 "FAILED_DTC" 3 "UNABLE_TO_TEST_DTC";
VAL_ 949 ESP_d127_rcmInvalidCalibration 0 "NOT_TESTED_DTC" 1 "PASSED_DTC" 2 "FAILED_DTC" 3 "UNABLE_TO_TEST_DTC";
VAL_ 949 ESP_d128_comSclPmState2TOut 0 "NOT_TESTED_DTC" 1 "PASSED_DTC" 2 "FAILED_DTC" 3 "UNABLE_TO_TEST_DTC";
VAL_ 949 ESP_d129_sclBdwReqActiveInvd 0 "NOT_TESTED_DTC" 1 "PASSED_DTC" 2 "FAILED_DTC" 3 "UNABLE_TO_TEST_DTC";
VAL_ 949 ESP_d130_comPmState2Crpt 0 "NOT_TESTED_DTC" 1 "PASSED_DTC" 2 "FAILED_DTC" 3 "UNABLE_TO_TEST_DTC";
VAL_ 949 ESP_d131_comSclPmState2CntFlt 0 "NOT_TESTED_DTC" 1 "PASSED_DTC" 2 "FAILED_DTC" 3 "UNABLE_TO_TEST_DTC";
VAL_ 949 ESP_d132_sclPmEbrCmdStateInvd 0 "NOT_TESTED_DTC" 1 "PASSED_DTC" 2 "FAILED_DTC" 3 "UNABLE_TO_TEST_DTC";
VAL_ 949 ESP_d133_acmVsSignalPlaus 0 "NOT_TESTED_DTC" 1 "PASSED_DTC" 2 "FAILED_DTC" 3 "UNABLE_TO_TEST_DTC";
VAL_ 949 ESP_d134_sasMonRange 0 "NOT_TESTED_DTC" 1 "PASSED_DTC" 2 "FAILED_DTC" 3 "UNABLE_TO_TEST_DTC";
VAL_ 949 ESP_d135_sasMonGrad 0 "NOT_TESTED_DTC" 1 "PASSED_DTC" 2 "FAILED_DTC" 3 "UNABLE_TO_TEST_DTC";
VAL_ 949 ESP_d136_yrsSignalOutOfRange 0 "NOT_TESTED_DTC" 1 "PASSED_DTC" 2 "FAILED_DTC" 3 "UNABLE_TO_TEST_DTC";
VAL_ 949 ESP_d137_yrsMonGrad 0 "NOT_TESTED_DTC" 1 "PASSED_DTC" 2 "FAILED_DTC" 3 "UNABLE_TO_TEST_DTC";
VAL_ 949 ESP_d138_yrsOffsetTooLarge 0 "NOT_TESTED_DTC" 1 "PASSED_DTC" 2 "FAILED_DTC" 3 "UNABLE_TO_TEST_DTC";
VAL_ 949 ESP_d139_evpSigPlausibility 0 "NOT_TESTED_DTC" 1 "PASSED_DTC" 2 "FAILED_DTC" 3 "UNABLE_TO_TEST_DTC";
VAL_ 949 ESP_d140_evpVacSigLow 0 "NOT_TESTED_DTC" 1 "PASSED_DTC" 2 "FAILED_DTC" 3 "UNABLE_TO_TEST_DTC";
VAL_ 949 ESP_d141_vacSensorElectFail 0 "NOT_TESTED_DTC" 1 "PASSED_DTC" 2 "FAILED_DTC" 3 "UNABLE_TO_TEST_DTC";
VAL_ 949 ESP_d142_canCommGeneral 0 "NOT_TESTED_DTC" 1 "PASSED_DTC" 2 "FAILED_DTC" 3 "UNABLE_TO_TEST_DTC";
VAL_ 949 ESP_d143_mcuChassisContrDtCrpt 0 "NOT_TESTED_DTC" 1 "PASSED_DTC" 2 "FAILED_DTC" 3 "UNABLE_TO_TEST_DTC";
VAL_ 949 ESP_d144_mcuChassisContrTout 0 "NOT_TESTED_DTC" 1 "PASSED_DTC" 2 "FAILED_DTC" 3 "UNABLE_TO_TEST_DTC";

VAL_ 805 ESP_infoIndex 0 "DEPRECATED_0" 1 "DEPRECATED_1" 2 "DEPRECATED_2" 3 "DEPRECATED_3" 4 "DEPRECATED_4" 5 "DEPRECATED_5" 6 "DEPRECATED_6" 7 "DEPRECATED_7" 8 "DEPRECATED_8" 9 "DEPRECATED_9" 10 "BUILD_HWID_COMPONENTID" 11 "PCBAID_ASSYID_USAGEID" 13 "APP_CRC" 14 "BOOTLOADER_SVN" 15 "BOOTLOADER_CRC" 16 "SUBCOMPONENT" 17 "APP_GITHASH" 18 "BOOTLOADER_GITHASH" 19 "VERSION_DEPRECATED" 20 "UDS_PROTOCOL_BOOTCRC" 22 "VARIANT_CRC" 255 "END";
VAL_ 805 ESP_vehicleVariant 1 "S_RWD_TESLA_TC" 2 "S_RWD_ESP_TC" 3 "S_AWD" 4 "X_AWD";

VAL_ 1502 EasVersion0 255 "SNA";
VAL_ 1502 EasVersion1 255 "SNA";
VAL_ 1502 EasVersion2 255 "SNA";
VAL_ 1502 EasVersion3 255 "SNA";
VAL_ 1502 EasVersion4 255 "SNA";

VAL_ 1500 EspVersion0 255 "SNA";
VAL_ 1500 EspVersion1 255 "SNA";
VAL_ 1500 EspVersion2 255 "SNA";
VAL_ 1500 EspVersion3 255 "SNA";
VAL_ 1500 EspVersion4 255 "SNA";
VAL_ 1500 EspVersion5 255 "SNA";
VAL_ 1500 EspVersion6 255 "SNA";
VAL_ 1500 EspVersion7 255 "SNA";

VAL_ 533 FC_infoDummySig 0 "SNA";
VAL_ 533 FC_infoIndex 0 "DEPRECATED_0" 1 "DEPRECATED_1" 2 "DEPRECATED_2" 3 "DEPRECATED_3" 4 "DEPRECATED_4" 5 "DEPRECATED_5" 6 "DEPRECATED_6" 7 "DEPRECATED_7" 8 "DEPRECATED_8" 9 "DEPRECATED_9" 10 "BUILD_HWID_COMPONENTID" 11 "PCBAID_ASSYID_USAGEID" 13 "APP_CRC" 14 "BOOTLOADER_SVN" 15 "BOOTLOADER_CRC" 16 "SUBCOMPONENT" 17 "APP_GITHASH" 18 "BOOTLOADER_GITHASH" 19 "APP_TRIPLE" 20 "UDS_PROTOCOL_BOOTCRC" 127 "END";
VAL_ 533 FC_infoBuildType 0 "UNKNOWN_BUILD" 1 "PLATFORM_BUILD" 2 "LOCAL_BUILD" 3 "TRACEABLE_CI_BUILD" 4 "MFG_BUILD" 255 "BUILD_TYPE_SNA";
VAL_ 533 FC_infoBuildConfigID 0 "SNA";
VAL_ 533 FC_infoHardwareID 0 "SNA";
VAL_ 533 FC_infoComponentID 0 "SNA";
VAL_ 533 FC_infoPcbaID 0 "SNA";
VAL_ 533 FC_infoAssemblyID 0 "SNA";
VAL_ 533 FC_infoUsageID 0 "SNA";
VAL_ 533 FC_infoSubUsageID 0 "SNA";
VAL_ 533 FC_infoApplicationCRC 0 "SNA";
VAL_ 533 FC_infoBootSvnRev 0 "SNA";
VAL_ 533 FC_infoBootCRC 0 "SNA";
VAL_ 533 FC_infoCPLDVersionMajor 0 "SNA";
VAL_ 533 FC_infoCPLDVersionMinor 0 "SNA";
VAL_ 533 FC_infoAppGitHashBytes 0 "SNA";
VAL_ 533 FC_infoBootGitHashBytes 0 "SNA";
VAL_ 533 FC_infoPlatformType 0 "SNA";
VAL_ 533 FC_infoMajorVersion 255 "SNA";
VAL_ 533 FC_infoBranchOrigin 255 "SNA";
VAL_ 533 FC_infoMaturity 255 "SNA";
VAL_ 533 FC_infoHardwareRevision 0 "SNA";
VAL_ 533 FC_partNumChar01 0 "SNA";
VAL_ 533 FC_partNumChar02 0 "SNA";
VAL_ 533 FC_partNumChar03 0 "SNA";
VAL_ 533 FC_partNumChar04 0 "SNA";
VAL_ 533 FC_partNumChar05 0 "SNA";
VAL_ 533 FC_partNumChar06 0 "SNA";
VAL_ 533 FC_partNumChar07 0 "SNA";
VAL_ 533 FC_partNumChar08 0 "SNA";
VAL_ 533 FC_partNumChar09 0 "SNA";
VAL_ 533 FC_partNumChar10 0 "SNA";
VAL_ 533 FC_partNumChar11 0 "SNA";
VAL_ 533 FC_partNumChar12 0 "SNA";
VAL_ 533 FC_partNumChar13 0 "SNA";
VAL_ 533 FC_partNumChar14 0 "SNA";
VAL_ 533 FC_partNumChar15 0 "SNA";
VAL_ 533 FC_partNumChar16 0 "SNA";
VAL_ 533 FC_partNumChar17 0 "SNA";
VAL_ 533 FC_partNumChar18 0 "SNA";
VAL_ 533 FC_partNumChar19 0 "SNA";
VAL_ 533 FC_partNumChar20 1 "SNA";

VAL_ 543 FC_serialDummySig 0 "SNA";
VAL_ 543 FC_serialChar01 0 "SNA";
VAL_ 543 FC_serialChar02 0 "SNA";
VAL_ 543 FC_serialChar03 0 "SNA";
VAL_ 543 FC_serialChar04 0 "SNA";
VAL_ 543 FC_serialChar05 0 "SNA";
VAL_ 543 FC_serialChar06 0 "SNA";
VAL_ 543 FC_serialChar07 0 "SNA";
VAL_ 543 FC_serialChar08 0 "SNA";
VAL_ 543 FC_serialChar09 0 "SNA";
VAL_ 543 FC_serialChar10 0 "SNA";
VAL_ 543 FC_serialChar11 0 "SNA";
VAL_ 543 FC_serialChar12 0 "SNA";
VAL_ 543 FC_serialChar13 0 "SNA";
VAL_ 543 FC_serialChar14 0 "SNA";
VAL_ 543 FC_serialChar15 0 "SNA";
VAL_ 543 FC_serialChar16 0 "SNA";
VAL_ 543 FC_serialChar17 0 "SNA";

VAL_ 1122 FC_postID 0 "MASTER" 1 "SLAVE" 2 "ID_2" 3 "ID_SNA";
VAL_ 1122 FC_statusCode 0 "NOTREADY_SNA" 1 "READY" 2 "UPDATE_IN_PROGRESS" 3 "UNUSED_3" 4 "WAIT_POST_READY_TO_CHARGE" 5 "INT_ISOACTIVE" 6 "EXT_ISOACTIVE" 7 "POST_OUT_OF_SERVICE" 13 "NOTCOMPATIBLE" 14 "MALFUNCTION" 15 "NODATA";
VAL_ 1122 FC_type 0 "SUPERCHARGER" 1 "CHADEMO" 2 "GB" 3 "CC_EVSE" 4 "COMBO" 5 "MC_EVSE" 6 "OTHER" 7 "SNA";

VAL_ 1123 FC_externalIsolationResistance 255 "SNA";

VAL_ 1124 FC_class 0 "SNA" 1 "SUPERCHARGER" 2 "URBANCHARGER";
VAL_ 1124 FC_brand 0 "SNA" 1 "TESLA";
VAL_ 1124 FC_coolingType 0 "SNA" 1 "CONVECTION" 2 "LIQUID";
VAL_ 1124 FC_uiStopType 0 "SNA" 1 "TOGGLE" 2 "MOMENTARY";

VAL_ 2 BMS_packCurrent -16384 "SNA";
VAL_ 2 BMS_packVoltage 65535 "SNA";
VAL_ 2 BMS_state_ModelS 0 "STANDBY" 1 "CLEAR_FAULTS" 2 "FAULT" 3 "PRECHG_ANC" 4 "PRECHG_DR" 5 "PRECHG_FC" 6 "SUPPORT_ENABLE" 7 "DRIVE_ENABLE" 8 "CHARGER_ENABLE" 9 "FASTCHARGER_ENABLE" 10 "CHARGER_VOLTAGE" 15 "INVALID";

VAL_ 792 GTW_audioType 0 "Base" 1 "Premium";
VAL_ 792 GTW_autopilot 0 "NONE" 1 "HIGHWAY" 2 "ENHANCED" 3 "SELF_DRIVING";
VAL_ 792 GTW_auxHvacType 0 "NONE" 1 "HALLA_PTCR";
VAL_ 792 GTW_fastChargeAllowed 0 "NOT_ALLOWED" 1 "ALLOW" 2 "PAID";
VAL_ 792 GTW_frunkLatchType 0 "DIRECT_DRIVE" 1 "CONTINUOUS_DRIVE";
VAL_ 792 GTW_gpsType 0 "ublox" 1 "sierra";
VAL_ 792 GTW_ionizerType 0 "NONE" 1 "HALLA";
VAL_ 792 GTW_memorySeatsInstalled 0 "NONE" 1 "BITRON_GEN1" 2 "BITRON_GEN2";
VAL_ 792 GTW_performanceConfig 0 "CONFIG_SNA" 1 "P1" 2 "P2" 3 "P3" 4 "P4" 5 "P5" 6 "P6" 7 "P7";
VAL_ 792 GTW_plcAdapterType 0 "NONE" 1 "GEN3_EU_CP";
VAL_ 792 GTW_rearDriveUnitType 0 "LARGE_REAR" 1 "SMALL_REAR";
VAL_ 792 GTW_roofColor 0 "NONE" 1 "COLOR" 2 "BLACK" 3 "GLASS";
VAL_ 792 GTW_steeringHeat 0 "NONE" 1 "INSTALLED";
VAL_ 792 GTW_steeringWheel 0 "MY2012" 1 "MY2014_BASE" 2 "MY2014_ACC" 3 "MY2015_ACC" 7 "SNA";
VAL_ 792 GTW_towPackage 0 "NONE" 1 "TESLA_REV1";

VAL_ 794 GTW_badging 0 "BASE" 1 "FOUNDER" 2 "SIGNATURE" 3 "PERFORMANCE_PKG";
VAL_ 794 GTW_boardRevision 4 "SOP" 255 "UNKNOWN";
VAL_ 794 GTW_bodyControlsType 0 "PEKTRON" 1 "TESLA";
VAL_ 794 GTW_chargerType 0 "NOT_CONFIGURED" 1 "SINGLE_TESLA_10KW" 2 "DUAL_TESLA_10KW" 3 "CONFIG_SNA" 4 "SINGLE_7K5W" 5 "7K5W_MASTER_10KW_SLAVE" 6 "SINGLE_TESLA_RELAY" 7 "SINGLE_TESLA_LIMITED";
VAL_ 794 GTW_exteriorColorCode 0 "Default" 1 "SIERRA_BLACK" 2 "CATALINA_WHITE" 3 "SAN_SIMEON_SILVER" 4 "TIBURON_GREY" 5 "MONTEREY_BLUE" 6 "SEQUOIA_GREEN" 7 "ANZA_BROWN" 8 "SHASTA_WHITE_PEARL" 9 "SIGNATURE_RED" 10 "METALLIC_RED" 11 "STEEL_GREY" 12 "METALLIC_BLACK" 13 "TITANIUM_COPPER" 14 "SIGNATURE_BLUE";
VAL_ 794 GTW_frontSeatVentilationType 0 "NONE" 1 "FUTURIS" 2 "L_FUTURIS_R_KONGSBERG" 3 "L_KONGSBERG_R_FUTURIS" 4 "KONGSBERG";
VAL_ 794 GTW_headLampType 0 "halogen" 1 "hid" 2 "led" 3 "SNA";
VAL_ 794 GTW_interiorColorCode 0 "DEFAULT";
VAL_ 794 GTW_intrusionTiltInstalled 0 "NOT_INSTALLED" 1 "WITH_BATTERY_SIREN" 2 "ONLY";
VAL_ 794 GTW_powerLiftgateStrutType 0 "1" 1 "2";
VAL_ 794 GTW_steeringColumnType 0 "DAIMLER" 1 "THYSSEN_KRUPP";
VAL_ 794 GTW_thirdRowSeatType 0 "NONE" 1 "FUTURIS_UNIDIR_FOLDFLAT" 2 "FUTURIS_UNIDIR_NO_FOLDFLAT";
VAL_ 794 GTW_tpmsType 0 "BAOLONG" 1 "CONTI" 2 "NONE" 3 "CONTI_2";

VAL_ 131 GTW_airSuspensionInstalled 0 "NONE" 1 "STANDARD" 2 "PLUS" 3 "TESLA_STANDARD" 4 "TESLA_PLUS" 5 "TESLA_ADAPTIVE";
VAL_ 131 GTW_backupCameraType 0 "SMK" 1 "SEMCO";
VAL_ 131 GTW_brakeHwType 0 "P40_BREMBO_P28_BREMBO_EPB" 1 "P40_MANDO_43MOC" 2 "P44_MANDO_43MOC";
VAL_ 131 GTW_compressorType 0 "DENSO" 1 "HALLA_ASSM1" 2 "HALLA_ASSM2" 3 "HALLA_ASSM2_NVH_DEADBAND";
VAL_ 131 GTW_curveLightingType 0 "NONE" 1 "VARROC";
VAL_ 131 GTW_dasHw 0 "NONE" 1 "MONOCAM" 2 "PARKER_PASCAL" 3 "PARKER_PASCAL_2_5" 4 "TESLA_AP3";
VAL_ 131 GTW_displayBacklightFilmType 0 "DEFAULT_LUMINANCE_600" 1 "DBEF_LUMINANCE_800";
VAL_ 131 GTW_epasType 0 "BOSCH_L538" 1 "BOSCH_L405" 2 "MANDO_FGR64" 3 "MANDO_VGR66" 4 "MANDO_VGR66_GEN3";
VAL_ 131 GTW_espInterface 1 "1" 2 "2";
VAL_ 131 GTW_frontDriveUnitType 0 "SMALL_OR_NONE" 1 "PERMANENT_MAGNET";
VAL_ 131 GTW_headlightLevelerInstalled 0 "NONE" 1 "GEN_1" 2 "GEN_2";
VAL_ 131 GTW_intakeAirFilterType 0 "PAPER" 1 "X_COMBINATION_HEPA_INCAR" 2 "X_COMBINATION_INCAR_ONLY" 3 "MS_COMBINATION_HEPA_INCAR" 4 "MS_COMBINATION_INCAR_ONLY";
VAL_ 131 GTW_mapRegion 0 "us" 1 "eu" 2 "none" 3 "cn" 4 "au" 5 "jp" 6 "tw" 7 "kr" 8 "me";
VAL_ 131 GTW_navigationAllowed 0 "NOT_ALLOWED" 1 "ALLOWED" 3 "SNA";
VAL_ 131 GTW_parkAssistInstalled 0 "NONE" 1 "BOSCH_4_5" 2 "BOSCH_5" 3 "VALEO_5";
VAL_ 131 GTW_radarPosition 0 "MODELS" 1 "MODELS_2" 2 "MODELX";
VAL_ 131 GTW_rearFacingSeats 0 "NONE" 1 "BASE_REAR_FACING_SEATS";
VAL_ 131 GTW_restraintControlsType 0 "SDM" 1 "BOSCH_RCM";
VAL_ 131 GTW_spoilerInstalled 0 "NONE" 1 "PASSIVE" 2 "ACTIVE";
VAL_ 131 GTW_sunroofInstalled 0 "NONE" 1 "SUNROOF_1" 2 "SUNROOF_2";
VAL_ 131 GTW_topSpeedEnum 0 "DEFAULT_SNA" 1 "ONE_HUNDRED_FIFTY_FIVE";
VAL_ 131 GTW_wheelType 0 "BASE_19" 1 "SILVER_21" 2 "CHARCOAL_21" 3 "SILVER_21_EURO" 4 "AERO_19" 5 "CHARCOAL_21_EURO" 6 "SUPER_21_GRAY" 7 "SUPER_21_SILVER" 8 "TURBINE_19" 9 "TURBINE_19_CHARCOAL" 10 "AERO_TURBINE_19_METAL" 11 "AERO_TURBINE_19_BLACK" 12 "HELIX_20_SILVER" 13 "AERO_TURBINE_20_SILVER" 14 "TURBINE_22_SILVER" 15 "CYCLONE_19_GREY" 16 "AERO_TURBINE_20_SLVRBLK" 17 "TURBINE_22_BLACK" 18 "ARACHNID_21_SILVER" 19 "ARACHNID_21_BLACK" 20 "ARACHNID_21_GREY" 21 "SLIPSTREAM_20_CARBON" 22 "SLIPSTREAM_20_SLVRBLK" 23 "SLIPSTREAM_19_CARBON" 24 "TWINTURBINE_21_SILVER" 25 "TWINTURBINE_21_CARBON" 31 "CONFIG_SNA";

VAL_ 793 GTW_chassisType 0 "S_CHASSIS" 1 "X_CHASSIS" 2 "3_CHASSIS";
VAL_ 793 GTW_devTPMSType 0 "NOT_INSTALLED" 1 "PIRELLI_BLE";
VAL_ 793 GTW_efficiencyPackage 0 "DEFAULT" 1 "MODELS_2";
VAL_ 793 GTW_efuseType 0 "NONE" 1 "TESLA_REV1";
VAL_ 793 GTW_exvType 0 "NONE" 1 "SANHUA";
VAL_ 793 GTW_falconCapSensorInstalled 0 "INSTALLED" 1 "NOT_INSTALLED";
VAL_ 793 GTW_falconInwardUSSInstalled 0 "NOT_INSTALLED" 1 "INSTALLED_SILENT" 2 "INSTALLED_ACTIVE";
VAL_ 793 GTW_falconStrutType 0 "V1" 1 "V2";
VAL_ 793 GTW_fasciaType 0 "DEFAULT" 1 "MODELS_2";
VAL_ 793 GTW_fastChargeInstalled 0 "NOT_INSTALLED" 1 "FAST_CHG_HV_CHAIN_TYPE_1" 2 "FAST_CHG_HV_CHAIN_TYPE_2";
VAL_ 793 GTW_forwardRadarHw 0 "NONE" 1 "BOSCH_MRR14" 2 "CONTI_ARS410";
VAL_ 793 GTW_frontDoorActuationType 0 "ACTIVE" 1 "ACTIVE_LIMITED_FEATURES" 2 "PASSIVE";
VAL_ 793 GTW_frontDoorLatchType 0 "DEFAULT" 1 "MX_KIEKERT";
VAL_ 793 GTW_homelinkInstalled 0 "NONE" 1 "4" 2 "V_OPT_1" 3 "V_OPT_2";
VAL_ 793 GTW_parkSensorGeometryType 0 "MODELS" 1 "MODELS_2" 2 "MODELX";
VAL_ 793 GTW_performanceAddOn 0 "STANDARD" 1 "LUDICROUS" 2 "DERATED" 3 "UNCORKED";
VAL_ 793 GTW_performanceLock 0 "NONE" 1 "COMFORT_PERFORMANCE";
VAL_ 793 GTW_prototypeType 0 "A" 1 "B" 2 "C" 3 "D";
VAL_ 793 GTW_pwsSpeakerType 0 "NONE" 1 "SPEAKER_1";
VAL_ 793 GTW_rearSeatHeatersInstalled 0 "NONE" 1 "BASE" 2 "EXECUTIVE" 3 "MODELX_BASE" 4 "GENTHERM";
VAL_ 793 GTW_rearSeatType 0 "BASE" 1 "RECARO" 2 "EXECUTIVE" 3 "TWO_SEAT" 4 "MX_FOLD_FLAT" 5 "TWO_SEAT_WITH_CONSOLE" 6 "MX_FOLD_FLAT_MOTORIZED" 7 "FOLD_FLAT_MOTORIZED_DUAL";
VAL_ 793 GTW_restraintsHardwareType 0 "SNA" 1 "MX_NA_2R_BUCKET" 2 "MX_EUROW_LHD_2R_BUCKET" 3 "MX_NA_2R_FOLD_FLAT" 4 "MX_EUROW_LHD_2R_FOLD_FLAT" 5 "MX_EUROW_RHD_2R_BUCKET" 6 "MX_EUROW_RHD_2R_FOLD_FLAT" 11 "MSR_NA" 12 "MSR_EUROW" 21 "M3_NA" 22 "M3_EUROW" 111 "MSR_NA_RCM" 112 "MSR_EU_RCM" 113 "MSR_APAC_RCM";
VAL_ 793 GTW_screenAdhesiveType 0 "DBA2220" 1 "UV60-31";
VAL_ 793 GTW_seatType 0 "BASE" 1 "RECARO" 2 "TESLA_MS_GEN_1";
VAL_ 793 GTW_shutterType 0 "GEN1" 1 "GEN2";
VAL_ 793 GTW_steeringColumnHarness 0 "DEFAULT" 1 "CONTROLLED_BY_SUN";
VAL_ 793 GTW_temperatureHumiditySensor 0 "NONE" 1 "INSTALLED";
VAL_ 793 GTW_thirdRowSeatHeatType 0 "NONE" 1 "FUTURIS_HEATED" 2 "GENTHERM";
VAL_ 793 GTW_tractionControlType 0 "ESP_IF_RWD_DI_IF_AWD" 1 "DRIVE_INVERTER";
VAL_ 793 GTW_twelveVBatteryType 0 "EXIDE" 1 "C_D" 2 "C_D_NANO_CARBON" 3 "ATLAS_BX" 4 "SEBANG" 5 "ATLAS_U1_AGM";

VAL_ 856 GTW_aboutToChargeElab 0 "DISCON" 1 "LATCHED" 2 "PILOT_GOOD" 3 "PILOT_NOT_GOOD" 4 "POWER_GOOD" 5 "POWER_NOT_GOOD" 6 "NO_CHARGE_REQ" 7 "COMPLETE" 8 "BMS_FAULT" 9 "CHG_FAULT" 10 "WALL_FAULT" 11 "WAIT_BMS" 12 "DIS_WHILE_CHG" 13 "WALL_PLUG_OUT" 15 "MALFUNCTION" 16 "NO_CHG_ENABLE" 17 "CHG_REQ_CHANGE" 18 "NOT_COMPLETE";
VAL_ 856 GTW_chargeChargingElab 0 "DISCON" 1 "LATCHED" 2 "PILOT_GOOD" 3 "PILOT_NOT_GOOD" 4 "POWER_GOOD" 5 "POWER_NOT_GOOD" 6 "NO_CHARGE_REQ" 7 "COMPLETE" 8 "BMS_FAULT" 9 "CHG_FAULT" 10 "WALL_FAULT" 11 "WAIT_BMS" 12 "DIS_WHILE_CHG" 13 "WALL_PLUG_OUT" 15 "MALFUNCTION" 16 "NO_CHG_ENABLE" 17 "CHG_REQ_CHANGE" 18 "NOT_COMPLETE";
VAL_ 856 GTW_chargeCompleteElab 0 "DISCON" 1 "LATCHED" 2 "PILOT_GOOD" 3 "PILOT_NOT_GOOD" 4 "POWER_GOOD" 5 "POWER_NOT_GOOD" 6 "NO_CHARGE_REQ" 7 "COMPLETE" 8 "BMS_FAULT" 9 "CHG_FAULT" 10 "WALL_FAULT" 11 "WAIT_BMS" 12 "DIS_WHILE_CHG" 13 "WALL_PLUG_OUT" 15 "MALFUNCTION" 16 "NO_CHG_ENABLE" 17 "CHG_REQ_CHANGE" 18 "NOT_COMPLETE";
VAL_ 856 GTW_chargeDisconElab 0 "DISCON" 1 "LATCHED" 2 "PILOT_GOOD" 3 "PILOT_NOT_GOOD" 4 "POWER_GOOD" 5 "POWER_NOT_GOOD" 6 "NO_CHARGE_REQ" 7 "COMPLETE" 8 "BMS_FAULT" 9 "CHG_FAULT" 10 "WALL_FAULT" 11 "WAIT_BMS" 12 "DIS_WHILE_CHG" 13 "WALL_PLUG_OUT" 15 "MALFUNCTION" 16 "NO_CHG_ENABLE" 17 "CHG_REQ_CHANGE" 18 "NOT_COMPLETE";
VAL_ 856 GTW_chargeNoPowerElab 0 "DISCON" 1 "LATCHED" 2 "PILOT_GOOD" 3 "PILOT_NOT_GOOD" 4 "POWER_GOOD" 5 "POWER_NOT_GOOD" 6 "NO_CHARGE_REQ" 7 "COMPLETE" 8 "BMS_FAULT" 9 "CHG_FAULT" 10 "WALL_FAULT" 11 "WAIT_BMS" 12 "DIS_WHILE_CHG" 13 "WALL_PLUG_OUT" 15 "MALFUNCTION" 16 "NO_CHG_ENABLE" 17 "CHG_REQ_CHANGE" 18 "NOT_COMPLETE";
VAL_ 856 GTW_chargeState 0 "DISCONNECTED" 1 "NO_POWER" 2 "ABOUT_TO_CHARGE" 3 "CHARGING" 4 "COMPLETE" 5 "STOPPED" 6 "MAX";
VAL_ 856 GTW_chargeStoppedElab 0 "DISCON" 1 "LATCHED" 2 "PILOT_GOOD" 3 "PILOT_NOT_GOOD" 4 "POWER_GOOD" 5 "POWER_NOT_GOOD" 6 "NO_CHARGE_REQ" 7 "COMPLETE" 8 "BMS_FAULT" 9 "CHG_FAULT" 10 "WALL_FAULT" 11 "WAIT_BMS" 12 "DIS_WHILE_CHG" 13 "WALL_PLUG_OUT" 15 "MALFUNCTION" 16 "NO_CHG_ENABLE" 17 "CHG_REQ_CHANGE" 18 "NOT_COMPLETE";
VAL_ 856 GTW_currentStateElab 0 "DISCON" 1 "LATCHED" 2 "PILOT_GOOD" 3 "PILOT_NOT_GOOD" 4 "POWER_GOOD" 5 "POWER_NOT_GOOD" 6 "NO_CHARGE_REQ" 7 "COMPLETE" 8 "BMS_FAULT" 9 "CHG_FAULT" 10 "WALL_FAULT" 11 "WAIT_BMS" 12 "DIS_WHILE_CHG" 13 "WALL_PLUG_OUT" 15 "MALFUNCTION" 16 "NO_CHG_ENABLE" 17 "CHG_REQ_CHANGE" 18 "NOT_COMPLETE";
VAL_ 856 GTW_offboardUpdateState 0 "WAITING_FOR_CONNECTION" 1 "WAIT_UPDATE_TRIGGER" 2 "PREPARING" 3 "RUNNING" 4 "CONFIRM_UPDATE" 5 "LATCH_RESULT";
VAL_ 856 GTW_offboardUpdateStatus 0 "OK" 1 "FILE_OPEN_ERROR" 2 "UNPLUGGED" 3 "UDS_FAILED" 4 "SUCCESS" 5 "LOST_DIGITAL_COMMS" 6 "NOT_NEEDED" 7 "APPTRIPLE_MISMATCH";

VAL_ 824 GTW_d001_versionMismatch 0 "NOT_TESTED_DTC" 1 "PASSED_DTC" 2 "FAILED_DTC" 3 "UNABLE_TO_TEST_DTC";
VAL_ 824 GTW_d002_12VOvervoltage 0 "NOT_TESTED_DTC" 1 "PASSED_DTC" 2 "FAILED_DTC" 3 "UNABLE_TO_TEST_DTC";
VAL_ 824 GTW_d003_12VUndervoltage 0 "NOT_TESTED_DTC" 1 "PASSED_DTC" 2 "FAILED_DTC" 3 "UNABLE_TO_TEST_DTC";
VAL_ 824 GTW_d004_replaceGateway 0 "NOT_TESTED_DTC" 1 "PASSED_DTC" 2 "FAILED_DTC" 3 "UNABLE_TO_TEST_DTC";
VAL_ 824 GTW_d005_componentMia 0 "NOT_TESTED_DTC" 1 "PASSED_DTC" 2 "FAILED_DTC" 3 "UNABLE_TO_TEST_DTC";
VAL_ 824 GTW_d006_replace12VBattery 0 "NOT_TESTED_DTC" 1 "PASSED_DTC" 2 "FAILED_DTC" 3 "UNABLE_TO_TEST_DTC";
VAL_ 824 GTW_d007_chgMia 0 "NOT_TESTED_DTC" 1 "PASSED_DTC" 2 "FAILED_DTC" 3 "UNABLE_TO_TEST_DTC";
VAL_ 824 GTW_d008_diMia 0 "NOT_TESTED_DTC" 1 "PASSED_DTC" 2 "FAILED_DTC" 3 "UNABLE_TO_TEST_DTC";
VAL_ 824 GTW_d009_bmsMia 0 "NOT_TESTED_DTC" 1 "PASSED_DTC" 2 "FAILED_DTC" 3 "UNABLE_TO_TEST_DTC";
VAL_ 824 GTW_d010_dcdcMia 0 "NOT_TESTED_DTC" 1 "PASSED_DTC" 2 "FAILED_DTC" 3 "UNABLE_TO_TEST_DTC";
VAL_ 824 GTW_d011_thcMia 0 "NOT_TESTED_DTC" 1 "PASSED_DTC" 2 "FAILED_DTC" 3 "UNABLE_TO_TEST_DTC";
VAL_ 824 GTW_d012_bdyMia 0 "NOT_TESTED_DTC" 1 "PASSED_DTC" 2 "FAILED_DTC" 3 "UNABLE_TO_TEST_DTC";
VAL_ 824 GTW_d013_epbMia 0 "NOT_TESTED_DTC" 1 "PASSED_DTC" 2 "FAILED_DTC" 3 "UNABLE_TO_TEST_DTC";

VAL_ 257 GTW_epasTuneRequest 0 "FAIL_SAFE_DEFAULT" 1 "DM_COMFORT" 2 "DM_STANDARD" 3 "DM_SPORT" 4 "RWD_COMFORT" 5 "RWD_STANDARD" 6 "RWD_SPORT" 7 "SNA";

VAL_ 49 GTW_diagDriveState 0 "OFF_SNA" 1 "FACTORY" 2 "SERVICE" 3 "ENGINEERING" 4 "KEYPAIRING";
VAL_ 49 GTW_willBeGoingToSleep 0 "IDLE" 1 "ACTIVE" 2 "ABORTED" 3 "SNA";

VAL_ 60 GTW_buildType 0 "UNKNOWN" 1 "PLATFORM" 2 "LOCAL" 3 "TRACEABLE_CI" 4 "MANUFACTURING" 255 "SNA";
VAL_ 60 GTW_buildConfigID 65535 "SNA";
VAL_ 60 GTW_applicationCrc 4294967295 "SNA";
VAL_ 60 GTW_branchEnumId 4095 "SNA";
VAL_ 60 GTW_branchCommitCount 1048575 "SNA";

VAL_ 776 GTW_easManualLevelRequest 0 "NO_CHANGE_SNA" 1 "REQUEST_LOW_LEVEL" 2 "REQUEST_NORMAL_LEVEL" 3 "REQUEST_HIGH_LEVEL" 4 "REQUEST_VERY_HIGH_LEVEL" 5 "TOGGLE_JACK_MODE" 6 "SWITCH_DEFECT" 7 "REQUEST_VERY_LOW_LEVEL";

VAL_ 135 GTW_clusterState 0 "OFF_CLUSTER" 1 "OFF_WAIT_DONE_CLUSTER" 2 "POWER_ENABLED_CLUSTER" 3 "POWER_WAITING_CLUSTER" 4 "POWER_ON_CLUSTER" 5 "FORCING_OFF_CLUSTER" 6 "FORCED_OFF_CLUSTER" 7 "CLUSTER_BOOT_WAIT";
VAL_ 135 GTW_mcuClusterInstantOn 0 "ALLOW_CLUSTER_OFF_SNA";
VAL_ 135 GTW_mcuGatewaySleepReq 0 "DONT_SLEEP" 1 "OK_TO_START" 2 "SLEEP_NOW" 3 "LOW_POWER_SLEEP" 7 "SNA";

VAL_ 136 GTW_deepSleepMinutes 16382 "NEVER" 16383 "SNA";

VAL_ 2038 GTW_wakeupReason 0 "12V_POWER_WAKEUP" 16 "CAN_BUS_0_WAKEUP" 32 "CAN_BUS_1_WAKEUP" 64 "CAN_BUS_2_WAKEUP" 96 "CAN_BUS_1_AND_2_WAKEUP" 128 "CAN_BUS_3_WAKEUP" 256 "CAN_BUS_4_WAKEUP" 512 "CAN_BUS_5_WAKEUP" 32768 "UART_WAKEUP" 2097152 "RTC_WAKEUP_INFO2" 2097184 "CAN_BUS_1_AND_RTC_WAKEUP_INFO2" 2097216 "CAN_BUS_2_AND_RTC_WAKEUP_INFO2" 2129920 "UART_AND_RTC_WAKEUP_INFO2" 8388608 "RTC_WAKEUP" 8388640 "CAN_BUS_1_AND_RTC_WAKEUP" 8388672 "CAN_BUS_2_AND_RTC_WAKEUP" 8389120 "UART_AND_RTC_WAKEUP" 16777216 "GSM_WAKEUP" 25165824 "RTC_AND_GSM_WAKEUP" 2147483648 "GSM_WAKEUP_INFO2" 2149580800 "RTC_AND_GSM_WAKEUP_INFO2";

VAL_ 27 GTW_ambientTemperature 255 "SNA";
VAL_ 27 GTW_temp_bottom -128 "SNA";
VAL_ 27 GTW_temp_dsp -128 "SNA";
VAL_ 27 GTW_temp_left -128 "SNA";
VAL_ 27 GTW_temp_remote_3 -128 "SNA";
VAL_ 27 GTW_temp_remote_4 -128 "SNA";
VAL_ 27 GTW_temp_right -128 "SNA";
VAL_ 27 GTW_temp_top -128 "SNA";

VAL_ 2028 GTW_progHLKResponse 0 "NOT_ACTIVE_SNA" 1 "PROG_SUCCESS" 2 "PROG_FAILURE";

VAL_ 857 GTW_TPMSLearnIDMode 0 "NO_ID_LEARN_FUNCTION" 1 "AUTO_LEARN_ACTIVE_BY_MANUAL" 2 "AUTO_LOCATION_ACTIVE_BY_MANUAL" 3 "AUTO_LEARN_ACTIVE_AFTER_PWR" 4 "AUTO_LOCATION_ACTIVE_AFTER_PWR";
VAL_ 857 GTW_TPMSMode 0 "UNUSED_MODE" 1 "NORMAL_MODE" 2 "PERFORMANCE_MODE";
VAL_ 857 GTW_sizeOfReqCANAutoLearn 0 "UNUSED" 1 "DISPLAY_CAN_FRAME_AUTO_LEARN" 2 "DO_NOT_DISPLAY_CAN_FRAME";
VAL_ 857 GTW_sizeOfWheelSelect 0 "UNUSED" 1 "19_INCH_WHEEL" 2 "21_INCH_WHEEL";

VAL_ 59 GTW_componentHardwareRevision 254 "LOCAL_BUILD" 255 "SNA";
VAL_ 59 GTW_platformType 254 "LOCAL_BUILD" 255 "SNA";

VAL_ 19 HLK_led 255 "SNA";

VAL_ 71 HVBC_ac50Hz 0 "60Hz" 1 "50Hz";
VAL_ 71 HVBC_en 0 "not_enabled" 1 "enabled";
VAL_ 71 HVBC_fault 0 "No_Fault" 1 "Fault";
VAL_ 71 HVBC_hfc 0 "No_Faults" 1 "Statistics" 2 "Notice" 3 "Ramp_Down_Switch_Off" 4 "Immediate_Switch_Off" 5 "Unused_5" 6 "Unused_6" 7 "Unused_7";
VAL_ 71 HVBC_pilotFault 0 "not_in_fault" 1 "in_fault";

VAL_ 861 IBST_d000_bmsInitTestFail 0 "NOT_TESTED_DTC" 1 "PASSED_DTC" 2 "FAILED_DTC" 3 "UNABLE_TO_TEST_DTC";
VAL_ 861 IBST_d001_bmcSingleTransTest 0 "NOT_TESTED_DTC" 1 "PASSED_DTC" 2 "FAILED_DTC" 3 "UNABLE_TO_TEST_DTC";
VAL_ 861 IBST_d002_tle5012SsccrcFail 0 "NOT_TESTED_DTC" 1 "PASSED_DTC" 2 "FAILED_DTC" 3 "UNABLE_TO_TEST_DTC";
VAL_ 861 IBST_d003_tle5012Config 0 "NOT_TESTED_DTC" 1 "PASSED_DTC" 2 "FAILED_DTC" 3 "UNABLE_TO_TEST_DTC";
VAL_ 861 IBST_d004_deadlMonTaskx1Ovr 0 "NOT_TESTED_DTC" 1 "PASSED_DTC" 2 "FAILED_DTC" 3 "UNABLE_TO_TEST_DTC";
VAL_ 861 IBST_d005_ecuWdFltCntTstFls 0 "NOT_TESTED_DTC" 1 "PASSED_DTC" 2 "FAILED_DTC" 3 "UNABLE_TO_TEST_DTC";
VAL_ 861 IBST_d006_ecuWdScheduleTout 0 "NOT_TESTED_DTC" 1 "PASSED_DTC" 2 "FAILED_DTC" 3 "UNABLE_TO_TEST_DTC";
VAL_ 861 IBST_d007_ecuWdStarttestFls 0 "NOT_TESTED_DTC" 1 "PASSED_DTC" 2 "FAILED_DTC" 3 "UNABLE_TO_TEST_DTC";
VAL_ 861 IBST_d008_ecuWdStatusContErr 0 "NOT_TESTED_DTC" 1 "PASSED_DTC" 2 "FAILED_DTC" 3 "UNABLE_TO_TEST_DTC";
VAL_ 861 IBST_d009_netOvrvolt 0 "NOT_TESTED_DTC" 1 "PASSED_DTC" 2 "FAILED_DTC" 3 "UNABLE_TO_TEST_DTC";
VAL_ 861 IBST_d010_micSpiTout 0 "NOT_TESTED_DTC" 1 "PASSED_DTC" 2 "FAILED_DTC" 3 "UNABLE_TO_TEST_DTC";
VAL_ 861 IBST_d011_micSpiTransferErr 0 "NOT_TESTED_DTC" 1 "PASSED_DTC" 2 "FAILED_DTC" 3 "UNABLE_TO_TEST_DTC";
VAL_ 861 IBST_d012_netUndvolt 0 "NOT_TESTED_DTC" 1 "PASSED_DTC" 2 "FAILED_DTC" 3 "UNABLE_TO_TEST_DTC";
VAL_ 861 IBST_d013_xpassToutErr 0 "NOT_TESTED_DTC" 1 "PASSED_DTC" 2 "FAILED_DTC" 3 "UNABLE_TO_TEST_DTC";
VAL_ 861 IBST_d014_rpsOffsEeReadEmpty 0 "NOT_TESTED_DTC" 1 "PASSED_DTC" 2 "FAILED_DTC" 3 "UNABLE_TO_TEST_DTC";
VAL_ 861 IBST_d015_rtpEnaHigh 0 "NOT_TESTED_DTC" 1 "PASSED_DTC" 2 "FAILED_DTC" 3 "UNABLE_TO_TEST_DTC";
VAL_ 861 IBST_d016_xpassEchoCountErr 0 "NOT_TESTED_DTC" 1 "PASSED_DTC" 2 "FAILED_DTC" 3 "UNABLE_TO_TEST_DTC";
VAL_ 861 IBST_d017_preDriveChckFail 0 "NOT_TESTED_DTC" 1 "PASSED_DTC" 2 "FAILED_DTC" 3 "UNABLE_TO_TEST_DTC";
VAL_ 861 IBST_d018_ucSafetyFlt 0 "NOT_TESTED_DTC" 1 "PASSED_DTC" 2 "FAILED_DTC" 3 "UNABLE_TO_TEST_DTC";
VAL_ 861 IBST_d019_unsupportedHw 0 "NOT_TESTED_DTC" 1 "PASSED_DTC" 2 "FAILED_DTC" 3 "UNABLE_TO_TEST_DTC";
VAL_ 861 IBST_d020_voltPreRegModeFld 0 "NOT_TESTED_DTC" 1 "PASSED_DTC" 2 "FAILED_DTC" 3 "UNABLE_TO_TEST_DTC";
VAL_ 861 IBST_d021_ubbSupplyLine 0 "NOT_TESTED_DTC" 1 "PASSED_DTC" 2 "FAILED_DTC" 3 "UNABLE_TO_TEST_DTC";
VAL_ 861 IBST_d022_stmAswSysTout 0 "NOT_TESTED_DTC" 1 "PASSED_DTC" 2 "FAILED_DTC" 3 "UNABLE_TO_TEST_DTC";
VAL_ 861 IBST_d023_stackOvrUndFlow 0 "NOT_TESTED_DTC" 1 "PASSED_DTC" 2 "FAILED_DTC" 3 "UNABLE_TO_TEST_DTC";
VAL_ 861 IBST_d024_smmOneReqsInit 0 "NOT_TESTED_DTC" 1 "PASSED_DTC" 2 "FAILED_DTC" 3 "UNABLE_TO_TEST_DTC";
VAL_ 861 IBST_d025_ptsSupply 0 "NOT_TESTED_DTC" 1 "PASSED_DTC" 2 "FAILED_DTC" 3 "UNABLE_TO_TEST_DTC";
VAL_ 861 IBST_d026_ptsSupplyUndvolt 0 "NOT_TESTED_DTC" 1 "PASSED_DTC" 2 "FAILED_DTC" 3 "UNABLE_TO_TEST_DTC";
VAL_ 861 IBST_d027_tempB6Plaus 0 "NOT_TESTED_DTC" 1 "PASSED_DTC" 2 "FAILED_DTC" 3 "UNABLE_TO_TEST_DTC";
VAL_ 861 IBST_d028_ecuWdErrCntContErr 0 "NOT_TESTED_DTC" 1 "PASSED_DTC" 2 "FAILED_DTC" 3 "UNABLE_TO_TEST_DTC";
VAL_ 861 IBST_d029_bmcShortedGateTest 0 "NOT_TESTED_DTC" 1 "PASSED_DTC" 2 "FAILED_DTC" 3 "UNABLE_TO_TEST_DTC";
VAL_ 861 IBST_d030_controllerDevTooBig 0 "NOT_TESTED_DTC" 1 "PASSED_DTC" 2 "FAILED_DTC" 3 "UNABLE_TO_TEST_DTC";
VAL_ 861 IBST_d031_ibDtrFail 0 "NOT_TESTED_DTC" 1 "PASSED_DTC" 2 "FAILED_DTC" 3 "UNABLE_TO_TEST_DTC";
VAL_ 861 IBST_d032_oc6InitTestFail 0 "NOT_TESTED_DTC" 1 "PASSED_DTC" 2 "FAILED_DTC" 3 "UNABLE_TO_TEST_DTC";
VAL_ 861 IBST_d033_oc6Monitor 0 "NOT_TESTED_DTC" 1 "PASSED_DTC" 2 "FAILED_DTC" 3 "UNABLE_TO_TEST_DTC";
VAL_ 861 IBST_d034_motorOscillationDet 0 "NOT_TESTED_DTC" 1 "PASSED_DTC" 2 "FAILED_DTC" 3 "UNABLE_TO_TEST_DTC";
VAL_ 861 IBST_d035_rpsOffsEeReadFail 0 "NOT_TESTED_DTC" 1 "PASSED_DTC" 2 "FAILED_DTC" 3 "UNABLE_TO_TEST_DTC";
VAL_ 861 IBST_d036_sysErrHook 0 "NOT_TESTED_DTC" 1 "PASSED_DTC" 2 "FAILED_DTC" 3 "UNABLE_TO_TEST_DTC";
VAL_ 861 IBST_d037_calIdlePosNotPlaus 0 "NOT_TESTED_DTC" 1 "PASSED_DTC" 2 "FAILED_DTC" 3 "UNABLE_TO_TEST_DTC";
VAL_ 861 IBST_d038_boostSupUndrvolt 0 "NOT_TESTED_DTC" 1 "PASSED_DTC" 2 "FAILED_DTC" 3 "UNABLE_TO_TEST_DTC";
VAL_ 861 IBST_d039_calRoutineAbort 0 "NOT_TESTED_DTC" 1 "PASSED_DTC" 2 "FAILED_DTC" 3 "UNABLE_TO_TEST_DTC";
VAL_ 861 IBST_d040_bmcGateUndervoltPro 0 "NOT_TESTED_DTC" 1 "PASSED_DTC" 2 "FAILED_DTC" 3 "UNABLE_TO_TEST_DTC";
VAL_ 861 IBST_d041_hswInitPhseUndrvolt 0 "NOT_TESTED_DTC" 1 "PASSED_DTC" 2 "FAILED_DTC" 3 "UNABLE_TO_TEST_DTC";
VAL_ 861 IBST_d042_ltmWarnLevelReached 0 "NOT_TESTED_DTC" 1 "PASSED_DTC" 2 "FAILED_DTC" 3 "UNABLE_TO_TEST_DTC";
VAL_ 861 IBST_d043_rpsVctrLengthRelErr 0 "NOT_TESTED_DTC" 1 "PASSED_DTC" 2 "FAILED_DTC" 3 "UNABLE_TO_TEST_DTC";
VAL_ 861 IBST_d044_b6TempDegradeLevel1 0 "NOT_TESTED_DTC" 1 "PASSED_DTC" 2 "FAILED_DTC" 3 "UNABLE_TO_TEST_DTC";
VAL_ 861 IBST_d045_B6TempDegradeLevel2 0 "NOT_TESTED_DTC" 1 "PASSED_DTC" 2 "FAILED_DTC" 3 "UNABLE_TO_TEST_DTC";
VAL_ 861 IBST_d046_spiAnglOrRawNotUp 0 "NOT_TESTED_DTC" 1 "PASSED_DTC" 2 "FAILED_DTC" 3 "UNABLE_TO_TEST_DTC";
VAL_ 861 IBST_d047_dcomIboosterNotInit 0 "NOT_TESTED_DTC" 1 "PASSED_DTC" 2 "FAILED_DTC" 3 "UNABLE_TO_TEST_DTC";
VAL_ 861 IBST_d048_unintendMotorReturn 0 "NOT_TESTED_DTC" 1 "PASSED_DTC" 2 "FAILED_DTC" 3 "UNABLE_TO_TEST_DTC";
VAL_ 861 IBST_d049_cdmOvrvoltLevel1 0 "NOT_TESTED_DTC" 1 "PASSED_DTC" 2 "FAILED_DTC" 3 "UNABLE_TO_TEST_DTC";
VAL_ 861 IBST_d050_cdmUndrvoltLevel2 0 "NOT_TESTED_DTC" 1 "PASSED_DTC" 2 "FAILED_DTC" 3 "UNABLE_TO_TEST_DTC";
VAL_ 861 IBST_d051_cdmUndrvoltLevel1 0 "NOT_TESTED_DTC" 1 "PASSED_DTC" 2 "FAILED_DTC" 3 "UNABLE_TO_TEST_DTC";
VAL_ 861 IBST_d052_motTrvlRelReadFail 0 "NOT_TESTED_DTC" 1 "PASSED_DTC" 2 "FAILED_DTC" 3 "UNABLE_TO_TEST_DTC";
VAL_ 861 IBST_d053_tle5012UnexpReset 0 "NOT_TESTED_DTC" 1 "PASSED_DTC" 2 "FAILED_DTC" 3 "UNABLE_TO_TEST_DTC";
VAL_ 861 IBST_d054_bmsGateUndrvolt 0 "NOT_TESTED_DTC" 1 "PASSED_DTC" 2 "FAILED_DTC" 3 "UNABLE_TO_TEST_DTC";
VAL_ 861 IBST_d055_kl15HwPlausSw 0 "NOT_TESTED_DTC" 1 "PASSED_DTC" 2 "FAILED_DTC" 3 "UNABLE_TO_TEST_DTC";
VAL_ 861 IBST_d056_ibNotShutDownRight 0 "NOT_TESTED_DTC" 1 "PASSED_DTC" 2 "FAILED_DTC" 3 "UNABLE_TO_TEST_DTC";
VAL_ 861 IBST_d057_cdmHardUndrvolt 0 "NOT_TESTED_DTC" 1 "PASSED_DTC" 2 "FAILED_DTC" 3 "UNABLE_TO_TEST_DTC";
VAL_ 861 IBST_d058_cdmHardOvrvolt 0 "NOT_TESTED_DTC" 1 "PASSED_DTC" 2 "FAILED_DTC" 3 "UNABLE_TO_TEST_DTC";
VAL_ 861 IBST_d059_maxTrvlAdjstUpdFail 0 "NOT_TESTED_DTC" 1 "PASSED_DTC" 2 "FAILED_DTC" 3 "UNABLE_TO_TEST_DTC";
VAL_ 861 IBST_d060_ltmLimitReached 0 "NOT_TESTED_DTC" 1 "PASSED_DTC" 2 "FAILED_DTC" 3 "UNABLE_TO_TEST_DTC";
VAL_ 861 IBST_d061_dcomEcuDefect 0 "NOT_TESTED_DTC" 1 "PASSED_DTC" 2 "FAILED_DTC" 3 "UNABLE_TO_TEST_DTC";
VAL_ 861 IBST_d062_inputStroke1RngHigh 0 "NOT_TESTED_DTC" 1 "PASSED_DTC" 2 "FAILED_DTC" 3 "UNABLE_TO_TEST_DTC";
VAL_ 861 IBST_d063_inputStroke1RngLow 0 "NOT_TESTED_DTC" 1 "PASSED_DTC" 2 "FAILED_DTC" 3 "UNABLE_TO_TEST_DTC";
VAL_ 861 IBST_d064_inputStroke2RngHigh 0 "NOT_TESTED_DTC" 1 "PASSED_DTC" 2 "FAILED_DTC" 3 "UNABLE_TO_TEST_DTC";
VAL_ 861 IBST_d065_inputStroke2RngLow 0 "NOT_TESTED_DTC" 1 "PASSED_DTC" 2 "FAILED_DTC" 3 "UNABLE_TO_TEST_DTC";
VAL_ 861 IBST_d066_ibSupVoltDivDrift 0 "NOT_TESTED_DTC" 1 "PASSED_DTC" 2 "FAILED_DTC" 3 "UNABLE_TO_TEST_DTC";
VAL_ 861 IBST_d067_sOutRodToPressVal 0 "NOT_TESTED_DTC" 1 "PASSED_DTC" 2 "FAILED_DTC" 3 "UNABLE_TO_TEST_DTC";
VAL_ 861 IBST_d068_tle5012LifeCnt 0 "NOT_TESTED_DTC" 1 "PASSED_DTC" 2 "FAILED_DTC" 3 "UNABLE_TO_TEST_DTC";
VAL_ 861 IBST_d069_cdmExtendedUndrvolt 0 "NOT_TESTED_DTC" 1 "PASSED_DTC" 2 "FAILED_DTC" 3 "UNABLE_TO_TEST_DTC";
VAL_ 861 IBST_d070_cdmExtendedOvrvolt 0 "NOT_TESTED_DTC" 1 "PASSED_DTC" 2 "FAILED_DTC" 3 "UNABLE_TO_TEST_DTC";
VAL_ 861 IBST_d071_tempB6Ch1LineHigh 0 "NOT_TESTED_DTC" 1 "PASSED_DTC" 2 "FAILED_DTC" 3 "UNABLE_TO_TEST_DTC";
VAL_ 861 IBST_d072_tempB6Ch1LineLow 0 "NOT_TESTED_DTC" 1 "PASSED_DTC" 2 "FAILED_DTC" 3 "UNABLE_TO_TEST_DTC";
VAL_ 861 IBST_d073_tempB6Ch2LineHigh 0 "NOT_TESTED_DTC" 1 "PASSED_DTC" 2 "FAILED_DTC" 3 "UNABLE_TO_TEST_DTC";
VAL_ 861 IBST_d074_tempB6Ch2LineLow 0 "NOT_TESTED_DTC" 1 "PASSED_DTC" 2 "FAILED_DTC" 3 "UNABLE_TO_TEST_DTC";
VAL_ 861 IBST_d075_hevSwitchOffDcom 0 "NOT_TESTED_DTC" 1 "PASSED_DTC" 2 "FAILED_DTC" 3 "UNABLE_TO_TEST_DTC";
VAL_ 861 IBST_d076_tle5012VoltFail 0 "NOT_TESTED_DTC" 1 "PASSED_DTC" 2 "FAILED_DTC" 3 "UNABLE_TO_TEST_DTC";
VAL_ 861 IBST_d077_bcsFltCurrentHigh 0 "NOT_TESTED_DTC" 1 "PASSED_DTC" 2 "FAILED_DTC" 3 "UNABLE_TO_TEST_DTC";
VAL_ 861 IBST_d078_bcsFltCurrentLow 0 "NOT_TESTED_DTC" 1 "PASSED_DTC" 2 "FAILED_DTC" 3 "UNABLE_TO_TEST_DTC";
VAL_ 861 IBST_d079_ecuSupVoltDivDrift 0 "NOT_TESTED_DTC" 1 "PASSED_DTC" 2 "FAILED_DTC" 3 "UNABLE_TO_TEST_DTC";
VAL_ 861 IBST_d080_inputstroke1Grad 0 "NOT_TESTED_DTC" 1 "PASSED_DTC" 2 "FAILED_DTC" 3 "UNABLE_TO_TEST_DTC";
VAL_ 861 IBST_d081_pts1Err 0 "NOT_TESTED_DTC" 1 "PASSED_DTC" 2 "FAILED_DTC" 3 "UNABLE_TO_TEST_DTC";
VAL_ 861 IBST_d082_pts1LineGnd 0 "NOT_TESTED_DTC" 1 "PASSED_DTC" 2 "FAILED_DTC" 3 "UNABLE_TO_TEST_DTC";
VAL_ 861 IBST_d083_pts1LineHigh 0 "NOT_TESTED_DTC" 1 "PASSED_DTC" 2 "FAILED_DTC" 3 "UNABLE_TO_TEST_DTC";
VAL_ 861 IBST_d084_inputStroke2Grad 0 "NOT_TESTED_DTC" 1 "PASSED_DTC" 2 "FAILED_DTC" 3 "UNABLE_TO_TEST_DTC";
VAL_ 861 IBST_d085_pts2Err 0 "NOT_TESTED_DTC" 1 "PASSED_DTC" 2 "FAILED_DTC" 3 "UNABLE_TO_TEST_DTC";
VAL_ 861 IBST_d086_pts2LineGnd 0 "NOT_TESTED_DTC" 1 "PASSED_DTC" 2 "FAILED_DTC" 3 "UNABLE_TO_TEST_DTC";
VAL_ 861 IBST_d087_pts2LineHigh 0 "NOT_TESTED_DTC" 1 "PASSED_DTC" 2 "FAILED_DTC" 3 "UNABLE_TO_TEST_DTC";
VAL_ 861 IBST_d088_faildevInputStroke 0 "NOT_TESTED_DTC" 1 "PASSED_DTC" 2 "FAILED_DTC" 3 "UNABLE_TO_TEST_DTC";
VAL_ 861 IBST_d089_ptsOffsTooHigh 0 "NOT_TESTED_DTC" 1 "PASSED_DTC" 2 "FAILED_DTC" 3 "UNABLE_TO_TEST_DTC";
VAL_ 861 IBST_d090_pbistErr 0 "NOT_TESTED_DTC" 1 "PASSED_DTC" 2 "FAILED_DTC" 3 "UNABLE_TO_TEST_DTC";
VAL_ 861 IBST_d091_ramInitErr 0 "NOT_TESTED_DTC" 1 "PASSED_DTC" 2 "FAILED_DTC" 3 "UNABLE_TO_TEST_DTC";
VAL_ 861 IBST_d092_ramsinlgeFlt 0 "NOT_TESTED_DTC" 1 "PASSED_DTC" 2 "FAILED_DTC" 3 "UNABLE_TO_TEST_DTC";
VAL_ 861 IBST_d093_bertFlt 0 "NOT_TESTED_DTC" 1 "PASSED_DTC" 2 "FAILED_DTC" 3 "UNABLE_TO_TEST_DTC";
VAL_ 861 IBST_d094_CalDataNotPlaus 0 "NOT_TESTED_DTC" 1 "PASSED_DTC" 2 "FAILED_DTC" 3 "UNABLE_TO_TEST_DTC";
VAL_ 861 IBST_d095_canEHwError 0 "NOT_TESTED_DTC" 1 "PASSED_DTC" 2 "FAILED_DTC" 3 "UNABLE_TO_TEST_DTC";
VAL_ 861 IBST_d096_canETout 0 "NOT_TESTED_DTC" 1 "PASSED_DTC" 2 "FAILED_DTC" 3 "UNABLE_TO_TEST_DTC";
VAL_ 861 IBST_d097_cpuException 0 "NOT_TESTED_DTC" 1 "PASSED_DTC" 2 "FAILED_DTC" 3 "UNABLE_TO_TEST_DTC";
VAL_ 861 IBST_d098_ecuBandGap 0 "NOT_TESTED_DTC" 1 "PASSED_DTC" 2 "FAILED_DTC" 3 "UNABLE_TO_TEST_DTC";
VAL_ 861 IBST_d099_ecuBmsOnWhileWdTout 0 "NOT_TESTED_DTC" 1 "PASSED_DTC" 2 "FAILED_DTC" 3 "UNABLE_TO_TEST_DTC";
VAL_ 861 IBST_d100_ecuErrpinCntTstFls 0 "NOT_TESTED_DTC" 1 "PASSED_DTC" 2 "FAILED_DTC" 3 "UNABLE_TO_TEST_DTC";
VAL_ 861 IBST_d101_ecuHetException 0 "NOT_TESTED_DTC" 1 "PASSED_DTC" 2 "FAILED_DTC" 3 "UNABLE_TO_TEST_DTC";
VAL_ 861 IBST_d102_ecuHetTuAddErr 0 "NOT_TESTED_DTC" 1 "PASSED_DTC" 2 "FAILED_DTC" 3 "UNABLE_TO_TEST_DTC";
VAL_ 861 IBST_d103_ecuHetTuBusErr 0 "NOT_TESTED_DTC" 1 "PASSED_DTC" 2 "FAILED_DTC" 3 "UNABLE_TO_TEST_DTC";
VAL_ 861 IBST_d104_ecuHetTuBusyErr 0 "NOT_TESTED_DTC" 1 "PASSED_DTC" 2 "FAILED_DTC" 3 "UNABLE_TO_TEST_DTC";
VAL_ 861 IBST_d105_ecuHetTuException 0 "NOT_TESTED_DTC" 1 "PASSED_DTC" 2 "FAILED_DTC" 3 "UNABLE_TO_TEST_DTC";
VAL_ 861 IBST_d106_ecuTaskMissing 0 "NOT_TESTED_DTC" 1 "PASSED_DTC" 2 "FAILED_DTC" 3 "UNABLE_TO_TEST_DTC";
VAL_ 861 IBST_d107_hetRefError 0 "NOT_TESTED_DTC" 1 "PASSED_DTC" 2 "FAILED_DTC" 3 "UNABLE_TO_TEST_DTC";
VAL_ 861 IBST_d108_micInitSpiTstFld 0 "NOT_TESTED_DTC" 1 "PASSED_DTC" 2 "FAILED_DTC" 3 "UNABLE_TO_TEST_DTC";
VAL_ 861 IBST_d109_micInitSpiTransfErr 0 "NOT_TESTED_DTC" 1 "PASSED_DTC" 2 "FAILED_DTC" 3 "UNABLE_TO_TEST_DTC";
VAL_ 861 IBST_d110_micIntMonGenBitMon 0 "NOT_TESTED_DTC" 1 "PASSED_DTC" 2 "FAILED_DTC" 3 "UNABLE_TO_TEST_DTC";
VAL_ 861 IBST_d111_micIntVoltMonFld 0 "NOT_TESTED_DTC" 1 "PASSED_DTC" 2 "FAILED_DTC" 3 "UNABLE_TO_TEST_DTC";
VAL_ 861 IBST_d112_motPosTrvlReadEmpty 0 "NOT_TESTED_DTC" 1 "PASSED_DTC" 2 "FAILED_DTC" 3 "UNABLE_TO_TEST_DTC";
VAL_ 861 IBST_d113_motAngBoundReadEmpt 0 "NOT_TESTED_DTC" 1 "PASSED_DTC" 2 "FAILED_DTC" 3 "UNABLE_TO_TEST_DTC";
VAL_ 861 IBST_d114_motShaftShiftDetect 0 "NOT_TESTED_DTC" 1 "PASSED_DTC" 2 "FAILED_DTC" 3 "UNABLE_TO_TEST_DTC";
VAL_ 861 IBST_d115_osErrHook 0 "NOT_TESTED_DTC" 1 "PASSED_DTC" 2 "FAILED_DTC" 3 "UNABLE_TO_TEST_DTC";
VAL_ 861 IBST_d116_pdurEInitFail 0 "NOT_TESTED_DTC" 1 "PASSED_DTC" 2 "FAILED_DTC" 3 "UNABLE_TO_TEST_DTC";
VAL_ 861 IBST_d117_pdurEPduInstLost 0 "NOT_TESTED_DTC" 1 "PASSED_DTC" 2 "FAILED_DTC" 3 "UNABLE_TO_TEST_DTC";
VAL_ 861 IBST_d118_pts1OffsEeReadEmpty 0 "NOT_TESTED_DTC" 1 "PASSED_DTC" 2 "FAILED_DTC" 3 "UNABLE_TO_TEST_DTC";
VAL_ 861 IBST_d119_pts2OffsEeReadEmpty 0 "NOT_TESTED_DTC" 1 "PASSED_DTC" 2 "FAILED_DTC" 3 "UNABLE_TO_TEST_DTC";
VAL_ 861 IBST_d120_rpsOffsXEeReadFail 0 "NOT_TESTED_DTC" 1 "PASSED_DTC" 2 "FAILED_DTC" 3 "UNABLE_TO_TEST_DTC";
VAL_ 861 IBST_d121_rpsOffsYEeReadFail 0 "NOT_TESTED_DTC" 1 "PASSED_DTC" 2 "FAILED_DTC" 3 "UNABLE_TO_TEST_DTC";
VAL_ 861 IBST_d122_rpsSynchEeReadFail 0 "NOT_TESTED_DTC" 1 "PASSED_DTC" 2 "FAILED_DTC" 3 "UNABLE_TO_TEST_DTC";
VAL_ 861 IBST_d123_rpsAnglRecalcErr 0 "NOT_TESTED_DTC" 1 "PASSED_DTC" 2 "FAILED_DTC" 3 "UNABLE_TO_TEST_DTC";
VAL_ 861 IBST_d124_motTrvlRelWriteFail 0 "NOT_TESTED_DTC" 1 "PASSED_DTC" 2 "FAILED_DTC" 3 "UNABLE_TO_TEST_DTC";
VAL_ 861 IBST_d125_motTrvlRelReadEmpty 0 "NOT_TESTED_DTC" 1 "PASSED_DTC" 2 "FAILED_DTC" 3 "UNABLE_TO_TEST_DTC";
VAL_ 861 IBST_d126_ptsEeReadEmpty 0 "NOT_TESTED_DTC" 1 "PASSED_DTC" 2 "FAILED_DTC" 3 "UNABLE_TO_TEST_DTC";
VAL_ 861 IBST_d127_ecuAdcConversionErr 0 "NOT_TESTED_DTC" 1 "PASSED_DTC" 2 "FAILED_DTC" 3 "UNABLE_TO_TEST_DTC";
VAL_ 861 IBST_d128_ecuAdcSelftestErr 0 "NOT_TESTED_DTC" 1 "PASSED_DTC" 2 "FAILED_DTC" 3 "UNABLE_TO_TEST_DTC";
VAL_ 861 IBST_d129_ccmFlt 0 "NOT_TESTED_DTC" 1 "PASSED_DTC" 2 "FAILED_DTC" 3 "UNABLE_TO_TEST_DTC";
VAL_ 861 IBST_d130_ecuRomCheck 0 "NOT_TESTED_DTC" 1 "PASSED_DTC" 2 "FAILED_DTC" 3 "UNABLE_TO_TEST_DTC";
VAL_ 861 IBST_d131_esmNmiFlt 0 "NOT_TESTED_DTC" 1 "PASSED_DTC" 2 "FAILED_DTC" 3 "UNABLE_TO_TEST_DTC";
VAL_ 861 IBST_d132_esmSafetyFlt 0 "NOT_TESTED_DTC" 1 "PASSED_DTC" 2 "FAILED_DTC" 3 "UNABLE_TO_TEST_DTC";
VAL_ 861 IBST_d133_motPosTrvlReadFail 0 "NOT_TESTED_DTC" 1 "PASSED_DTC" 2 "FAILED_DTC" 3 "UNABLE_TO_TEST_DTC";
VAL_ 861 IBST_d134_motPosTrvlWriteFail 0 "NOT_TESTED_DTC" 1 "PASSED_DTC" 2 "FAILED_DTC" 3 "UNABLE_TO_TEST_DTC";
VAL_ 861 IBST_d135_motAnglBndReadErr 0 "NOT_TESTED_DTC" 1 "PASSED_DTC" 2 "FAILED_DTC" 3 "UNABLE_TO_TEST_DTC";
VAL_ 861 IBST_d136_motAnglBndWriteErr 0 "NOT_TESTED_DTC" 1 "PASSED_DTC" 2 "FAILED_DTC" 3 "UNABLE_TO_TEST_DTC";
VAL_ 861 IBST_d137_motAnglGradTooLarge 0 "NOT_TESTED_DTC" 1 "PASSED_DTC" 2 "FAILED_DTC" 3 "UNABLE_TO_TEST_DTC";
VAL_ 861 IBST_d138_pdmCustomerIdMis 0 "NOT_TESTED_DTC" 1 "PASSED_DTC" 2 "FAILED_DTC" 3 "UNABLE_TO_TEST_DTC";
VAL_ 861 IBST_d139_pdmDtFormatMis 0 "NOT_TESTED_DTC" 1 "PASSED_DTC" 2 "FAILED_DTC" 3 "UNABLE_TO_TEST_DTC";
VAL_ 861 IBST_d140_pdmOutOfMemory 0 "NOT_TESTED_DTC" 1 "PASSED_DTC" 2 "FAILED_DTC" 3 "UNABLE_TO_TEST_DTC";
VAL_ 861 IBST_d141_pdmFieldSizeMis 0 "NOT_TESTED_DTC" 1 "PASSED_DTC" 2 "FAILED_DTC" 3 "UNABLE_TO_TEST_DTC";
VAL_ 861 IBST_d142_pdmHwAcsErr 0 "NOT_TESTED_DTC" 1 "PASSED_DTC" 2 "FAILED_DTC" 3 "UNABLE_TO_TEST_DTC";
VAL_ 861 IBST_d143_pdmInternalHWErr 0 "NOT_TESTED_DTC" 1 "PASSED_DTC" 2 "FAILED_DTC" 3 "UNABLE_TO_TEST_DTC";
VAL_ 861 IBST_d144_ptsCalHysWritFail 0 "NOT_TESTED_DTC" 1 "PASSED_DTC" 2 "FAILED_DTC" 3 "UNABLE_TO_TEST_DTC";
VAL_ 861 IBST_d145_ptsCalValuesChkFail 0 "NOT_TESTED_DTC" 1 "PASSED_DTC" 2 "FAILED_DTC" 3 "UNABLE_TO_TEST_DTC";
VAL_ 861 IBST_d146_pts1CalEeReadFail 0 "NOT_TESTED_DTC" 1 "PASSED_DTC" 2 "FAILED_DTC" 3 "UNABLE_TO_TEST_DTC";
VAL_ 861 IBST_d147_pts1CalEeWriteFail 0 "NOT_TESTED_DTC" 1 "PASSED_DTC" 2 "FAILED_DTC" 3 "UNABLE_TO_TEST_DTC";
VAL_ 861 IBST_d148_rpsFailCompErr 0 "NOT_TESTED_DTC" 1 "PASSED_DTC" 2 "FAILED_DTC" 3 "UNABLE_TO_TEST_DTC";
VAL_ 861 IBST_d149_pts1OffsEeWriteFail 0 "NOT_TESTED_DTC" 1 "PASSED_DTC" 2 "FAILED_DTC" 3 "UNABLE_TO_TEST_DTC";
VAL_ 861 IBST_d150_pts2CalEeReadFail 0 "NOT_TESTED_DTC" 1 "PASSED_DTC" 2 "FAILED_DTC" 3 "UNABLE_TO_TEST_DTC";
VAL_ 861 IBST_d151_pts2CalEeWriteFail 0 "NOT_TESTED_DTC" 1 "PASSED_DTC" 2 "FAILED_DTC" 3 "UNABLE_TO_TEST_DTC";
VAL_ 861 IBST_d152_pts2OffsEeReadFail 0 "NOT_TESTED_DTC" 1 "PASSED_DTC" 2 "FAILED_DTC" 3 "UNABLE_TO_TEST_DTC";
VAL_ 861 IBST_d153_pts2OffsEeWriteFail 0 "NOT_TESTED_DTC" 1 "PASSED_DTC" 2 "FAILED_DTC" 3 "UNABLE_TO_TEST_DTC";
VAL_ 861 IBST_d154_rpsOffsXEeReadEmpty 0 "NOT_TESTED_DTC" 1 "PASSED_DTC" 2 "FAILED_DTC" 3 "UNABLE_TO_TEST_DTC";
VAL_ 861 IBST_d155_rpsOffsXEeWriteFail 0 "NOT_TESTED_DTC" 1 "PASSED_DTC" 2 "FAILED_DTC" 3 "UNABLE_TO_TEST_DTC";
VAL_ 861 IBST_d156_rpsOffsYEeReadEmpty 0 "NOT_TESTED_DTC" 1 "PASSED_DTC" 2 "FAILED_DTC" 3 "UNABLE_TO_TEST_DTC";
VAL_ 861 IBST_d157_rpsOffsYEeWriteFail 0 "NOT_TESTED_DTC" 1 "PASSED_DTC" 2 "FAILED_DTC" 3 "UNABLE_TO_TEST_DTC";
VAL_ 861 IBST_d158_rpsSynchEeReadEmpty 0 "NOT_TESTED_DTC" 1 "PASSED_DTC" 2 "FAILED_DTC" 3 "UNABLE_TO_TEST_DTC";
VAL_ 861 IBST_d159_rpsSynchEeWriteFail 0 "NOT_TESTED_DTC" 1 "PASSED_DTC" 2 "FAILED_DTC" 3 "UNABLE_TO_TEST_DTC";
VAL_ 861 IBST_d160_assertionFail 0 "NOT_TESTED_DTC" 1 "PASSED_DTC" 2 "FAILED_DTC" 3 "UNABLE_TO_TEST_DTC";
VAL_ 861 IBST_d161_comsclBrkPrsPduLen 0 "NOT_TESTED_DTC" 1 "PASSED_DTC" 2 "FAILED_DTC" 3 "UNABLE_TO_TEST_DTC";
VAL_ 861 IBST_d162_comsclBrkPrsPduTout 0 "NOT_TESTED_DTC" 1 "PASSED_DTC" 2 "FAILED_DTC" 3 "UNABLE_TO_TEST_DTC";
VAL_ 861 IBST_d163_comsclEspIb1CntErr 0 "NOT_TESTED_DTC" 1 "PASSED_DTC" 2 "FAILED_DTC" 3 "UNABLE_TO_TEST_DTC";
VAL_ 861 IBST_d164_comsclEspIb1CsErr 0 "NOT_TESTED_DTC" 1 "PASSED_DTC" 2 "FAILED_DTC" 3 "UNABLE_TO_TEST_DTC";
VAL_ 861 IBST_d165_comsclEspIb1DlcErr 0 "NOT_TESTED_DTC" 1 "PASSED_DTC" 2 "FAILED_DTC" 3 "UNABLE_TO_TEST_DTC";
VAL_ 861 IBST_d166_comsclEspIb1Tout 0 "NOT_TESTED_DTC" 1 "PASSED_DTC" 2 "FAILED_DTC" 3 "UNABLE_TO_TEST_DTC";
VAL_ 861 IBST_d167_comsclEspIb2CntErr 0 "NOT_TESTED_DTC" 1 "PASSED_DTC" 2 "FAILED_DTC" 3 "UNABLE_TO_TEST_DTC";
VAL_ 861 IBST_d168_comsclEspIb2CsErr 0 "NOT_TESTED_DTC" 1 "PASSED_DTC" 2 "FAILED_DTC" 3 "UNABLE_TO_TEST_DTC";
VAL_ 861 IBST_d169_comsclEspIb2DlcErr 0 "NOT_TESTED_DTC" 1 "PASSED_DTC" 2 "FAILED_DTC" 3 "UNABLE_TO_TEST_DTC";
VAL_ 861 IBST_d170_comsclEspIb2Tout 0 "NOT_TESTED_DTC" 1 "PASSED_DTC" 2 "FAILED_DTC" 3 "UNABLE_TO_TEST_DTC";
VAL_ 861 IBST_d171_comsclEspIb3CntErr 0 "NOT_TESTED_DTC" 1 "PASSED_DTC" 2 "FAILED_DTC" 3 "UNABLE_TO_TEST_DTC";
VAL_ 861 IBST_d172_comsclEspIb3CsErr 0 "NOT_TESTED_DTC" 1 "PASSED_DTC" 2 "FAILED_DTC" 3 "UNABLE_TO_TEST_DTC";
VAL_ 861 IBST_d173_comsclEspIb3DlcErr 0 "NOT_TESTED_DTC" 1 "PASSED_DTC" 2 "FAILED_DTC" 3 "UNABLE_TO_TEST_DTC";
VAL_ 861 IBST_d174_comsclEspIb3Tout 0 "NOT_TESTED_DTC" 1 "PASSED_DTC" 2 "FAILED_DTC" 3 "UNABLE_TO_TEST_DTC";
VAL_ 861 IBST_d175_comsclGtwEsp1CntErr 0 "NOT_TESTED_DTC" 1 "PASSED_DTC" 2 "FAILED_DTC" 3 "UNABLE_TO_TEST_DTC";
VAL_ 861 IBST_d176_comsclGtwEsp1CsErr 0 "NOT_TESTED_DTC" 1 "PASSED_DTC" 2 "FAILED_DTC" 3 "UNABLE_TO_TEST_DTC";
VAL_ 861 IBST_d177_comsclGtwEsp1Corrpt 0 "NOT_TESTED_DTC" 1 "PASSED_DTC" 2 "FAILED_DTC" 3 "UNABLE_TO_TEST_DTC";
VAL_ 861 IBST_d178_comsclGtwEsp1Tout 0 "NOT_TESTED_DTC" 1 "PASSED_DTC" 2 "FAILED_DTC" 3 "UNABLE_TO_TEST_DTC";
VAL_ 861 IBST_d179_dcomSmrtActuNotInit 0 "NOT_TESTED_DTC" 1 "PASSED_DTC" 2 "FAILED_DTC" 3 "UNABLE_TO_TEST_DTC";
VAL_ 861 IBST_d180_rpsLengthAbsolHigh 0 "NOT_TESTED_DTC" 1 "PASSED_DTC" 2 "FAILED_DTC" 3 "UNABLE_TO_TEST_DTC";
VAL_ 861 IBST_d181_rpsLengthAbsolLow 0 "NOT_TESTED_DTC" 1 "PASSED_DTC" 2 "FAILED_DTC" 3 "UNABLE_TO_TEST_DTC";
VAL_ 861 IBST_d182_shutDownEeReadFail 0 "NOT_TESTED_DTC" 1 "PASSED_DTC" 2 "FAILED_DTC" 3 "UNABLE_TO_TEST_DTC";
VAL_ 861 IBST_d183_shutDownEeWriteFail 0 "NOT_TESTED_DTC" 1 "PASSED_DTC" 2 "FAILED_DTC" 3 "UNABLE_TO_TEST_DTC";
VAL_ 861 IBST_d184_maxTrvlAdjstReadErr 0 "NOT_TESTED_DTC" 1 "PASSED_DTC" 2 "FAILED_DTC" 3 "UNABLE_TO_TEST_DTC";
VAL_ 861 IBST_d185_psOffsMcEeReadFail 0 "NOT_TESTED_DTC" 1 "PASSED_DTC" 2 "FAILED_DTC" 3 "UNABLE_TO_TEST_DTC";
VAL_ 861 IBST_d186_psOffsMcEeWriteFail 0 "NOT_TESTED_DTC" 1 "PASSED_DTC" 2 "FAILED_DTC" 3 "UNABLE_TO_TEST_DTC";
VAL_ 861 IBST_d187_ltmSelfProtDeact 0 "NOT_TESTED_DTC" 1 "PASSED_DTC" 2 "FAILED_DTC" 3 "UNABLE_TO_TEST_DTC";
VAL_ 861 IBST_d188_pts1OffsEeReadFail 0 "NOT_TESTED_DTC" 1 "PASSED_DTC" 2 "FAILED_DTC" 3 "UNABLE_TO_TEST_DTC";
VAL_ 861 IBST_d189_diffStrokeRange 0 "NOT_TESTED_DTC" 1 "PASSED_DTC" 2 "FAILED_DTC" 3 "UNABLE_TO_TEST_DTC";
VAL_ 861 IBST_d190_notProgVin 0 "NOT_TESTED_DTC" 1 "PASSED_DTC" 2 "FAILED_DTC" 3 "UNABLE_TO_TEST_DTC";
VAL_ 861 IBST_d191_plausVin 0 "NOT_TESTED_DTC" 1 "PASSED_DTC" 2 "FAILED_DTC" 3 "UNABLE_TO_TEST_DTC";
VAL_ 861 IBST_d192_dlCorCSumVin 0 "NOT_TESTED_DTC" 1 "PASSED_DTC" 2 "FAILED_DTC" 3 "UNABLE_TO_TEST_DTC";
VAL_ 861 IBST_d193_ToutVin 0 "NOT_TESTED_DTC" 1 "PASSED_DTC" 2 "FAILED_DTC" 3 "UNABLE_TO_TEST_DTC";
VAL_ 861 IBST_d194_ecuEnableB6Fail 0 "NOT_TESTED_DTC" 1 "PASSED_DTC" 2 "FAILED_DTC" 3 "UNABLE_TO_TEST_DTC";
VAL_ 861 IBST_d195_ecuIbEnContErr 0 "NOT_TESTED_DTC" 1 "PASSED_DTC" 2 "FAILED_DTC" 3 "UNABLE_TO_TEST_DTC";
VAL_ 861 IBST_d196_sclEspIb1pEstMax 0 "NOT_TESTED_DTC" 1 "PASSED_DTC" 2 "FAILED_DTC" 3 "UNABLE_TO_TEST_DTC";
VAL_ 861 IBST_d197_sclEspIb1VehSpd 0 "NOT_TESTED_DTC" 1 "PASSED_DTC" 2 "FAILED_DTC" 3 "UNABLE_TO_TEST_DTC";
VAL_ 861 IBST_d198_sclEspIb2pLimExt 0 "NOT_TESTED_DTC" 1 "PASSED_DTC" 2 "FAILED_DTC" 3 "UNABLE_TO_TEST_DTC";
VAL_ 861 IBST_d199_sclEspIb2qTarExt 0 "NOT_TESTED_DTC" 1 "PASSED_DTC" 2 "FAILED_DTC" 3 "UNABLE_TO_TEST_DTC";
VAL_ 861 IBST_d200_sclEspIb3pFBlend 0 "NOT_TESTED_DTC" 1 "PASSED_DTC" 2 "FAILED_DTC" 3 "UNABLE_TO_TEST_DTC";
VAL_ 861 IBST_d201_sclEspIb3pMc1 0 "NOT_TESTED_DTC" 1 "PASSED_DTC" 2 "FAILED_DTC" 3 "UNABLE_TO_TEST_DTC";
VAL_ 861 IBST_d202_sclEspIb3pTarDriver 0 "NOT_TESTED_DTC" 1 "PASSED_DTC" 2 "FAILED_DTC" 3 "UNABLE_TO_TEST_DTC";
VAL_ 861 IBST_d203_netBusOffNet0 0 "NOT_TESTED_DTC" 1 "PASSED_DTC" 2 "FAILED_DTC" 3 "UNABLE_TO_TEST_DTC";
VAL_ 861 IBST_d204_netErrPassivNet0 0 "NOT_TESTED_DTC" 1 "PASSED_DTC" 2 "FAILED_DTC" 3 "UNABLE_TO_TEST_DTC";
VAL_ 861 IBST_d205_netBusOffNet1 0 "NOT_TESTED_DTC" 1 "PASSED_DTC" 2 "FAILED_DTC" 3 "UNABLE_TO_TEST_DTC";
VAL_ 861 IBST_d206_netErrPassivNet1 0 "NOT_TESTED_DTC" 1 "PASSED_DTC" 2 "FAILED_DTC" 3 "UNABLE_TO_TEST_DTC";
VAL_ 861 IBST_d207_maxStrokeReached 0 "NOT_TESTED_DTC" 1 "PASSED_DTC" 2 "FAILED_DTC" 3 "UNABLE_TO_TEST_DTC";
VAL_ 861 IBST_d208_sysSwClockMismatch 0 "NOT_TESTED_DTC" 1 "PASSED_DTC" 2 "FAILED_DTC" 3 "UNABLE_TO_TEST_DTC";
VAL_ 861 IBST_d209_comsclGtwOdoCorrpt 0 "NOT_TESTED_DTC" 1 "PASSED_DTC" 2 "FAILED_DTC" 3 "UNABLE_TO_TEST_DTC";
VAL_ 861 IBST_d210_comsclGtwStatCorrpt 0 "NOT_TESTED_DTC" 1 "PASSED_DTC" 2 "FAILED_DTC" 3 "UNABLE_TO_TEST_DTC";
VAL_ 861 IBST_d211_comsclEpbStatCorrpt 0 "NOT_TESTED_DTC" 1 "PASSED_DTC" 2 "FAILED_DTC" 3 "UNABLE_TO_TEST_DTC";
VAL_ 861 IBST_d212_comsclGtwOdoTout 0 "NOT_TESTED_DTC" 1 "PASSED_DTC" 2 "FAILED_DTC" 3 "UNABLE_TO_TEST_DTC";
VAL_ 861 IBST_d213_comsclGtwStatTout 0 "NOT_TESTED_DTC" 1 "PASSED_DTC" 2 "FAILED_DTC" 3 "UNABLE_TO_TEST_DTC";
VAL_ 861 IBST_d214_comsclEpbStatTout 0 "NOT_TESTED_DTC" 1 "PASSED_DTC" 2 "FAILED_DTC" 3 "UNABLE_TO_TEST_DTC";
VAL_ 861 IBST_d215_comSclEpbStatCsErr 0 "NOT_TESTED_DTC" 1 "PASSED_DTC" 2 "FAILED_DTC" 3 "UNABLE_TO_TEST_DTC";
VAL_ 861 IBST_d216_comSclEpbStatCntFlt 0 "NOT_TESTED_DTC" 1 "PASSED_DTC" 2 "FAILED_DTC" 3 "UNABLE_TO_TEST_DTC";
VAL_ 861 IBST_d217_comSclDiTrq1Tout 0 "NOT_TESTED_DTC" 1 "PASSED_DTC" 2 "FAILED_DTC" 3 "UNABLE_TO_TEST_DTC";
VAL_ 861 IBST_d218_comSclDiTrq1Corrpt 0 "NOT_TESTED_DTC" 1 "PASSED_DTC" 2 "FAILED_DTC" 3 "UNABLE_TO_TEST_DTC";
VAL_ 861 IBST_d219_comSclDiTrq1CsErr 0 "NOT_TESTED_DTC" 1 "PASSED_DTC" 2 "FAILED_DTC" 3 "UNABLE_TO_TEST_DTC";
VAL_ 861 IBST_d220_comSclDiTrq1CntFlt 0 "NOT_TESTED_DTC" 1 "PASSED_DTC" 2 "FAILED_DTC" 3 "UNABLE_TO_TEST_DTC";

VAL_ 813 IBST_infoIndex 0 "DEPRECATED_0" 1 "DEPRECATED_1" 2 "DEPRECATED_2" 3 "DEPRECATED_3" 4 "DEPRECATED_4" 5 "DEPRECATED_5" 6 "DEPRECATED_6" 7 "DEPRECATED_7" 8 "DEPRECATED_8" 9 "DEPRECATED_9" 10 "BUILD_HWID_COMPONENTID" 11 "PCBAID_ASSYID_USAGEID" 13 "APP_CRC" 14 "BOOTLOADER_SVN" 15 "BOOTLOADER_CRC" 16 "SUBCOMPONENT" 17 "APP_GITHASH" 18 "BOOTLOADER_GITHASH" 19 "VERSION_DEPRECATED" 20 "UDS_PROTOCOL_BOOTCRC" 22 "VARIANT_CRC" 255 "END";

VAL_ 925 IBST_brakeInputStroke 1022 "NOT_VALID" 1023 "SNA";
VAL_ 925 IBST_iBoosterStatus 0 "NOT_INITIALIZED_OR_SUP" 1 "FAILURE" 2 "DIAGNOSIS" 3 "MAX_STROKE" 4 "STANDALONE" 5 "REDUCED" 6 "POST_RUN_REDUCED" 7 "READY";

VAL_ 22 IBS_current 4294967295 "SNA";
VAL_ 22 IBS_temperature 65535 "SNA";
VAL_ 22 IBS_voltage 65535 "SNA";

VAL_ 134 IC_infoIndex 0 "DEPRECATED_0" 1 "DEPRECATED_1" 2 "DEPRECATED_2" 3 "DEPRECATED_3" 4 "DEPRECATED_4" 5 "DEPRECATED_5" 6 "DEPRECATED_6" 7 "DEPRECATED_7" 8 "DEPRECATED_8" 9 "DEPRECATED_9" 10 "BUILD_HWID_COMPONENTID" 11 "PCBAID_ASSYID_USAGEID" 13 "APP_CRC" 14 "BOOTLOADER_SVN" 15 "BOOTLOADER_CRC" 16 "SUBCOMPONENT" 17 "APP_GITHASH" 18 "BOOTLOADER_GITHASH" 19 "VERSION_DEPRECATED" 20 "UDS_PROTOCOL_BOOTCRC" 255 "END";
VAL_ 134 IC_FPGA_version 254 "LOCAL_BUILD" 255 "SNA";

VAL_ 539 IC_LEDBrightnessClass 0 "UNKNOWN" 1 "LED_RANK_PA7" 2 "LED_RANK_PA8" 3 "LED_RANK_PA9";

VAL_ 1532 IC_componentHardwareRevision 252 "CONFIGURABLE_HWID_PLACEHOLDER";

VAL_ 525 LFT_state 0 "SNA" 1 "OPEN" 2 "OPENING" 3 "CLOSING" 4 "MANUAL" 5 "CLOSED" 6 "LATCH_TRANSITION" 7 "INIT";
VAL_ 525 LFT_unlatchRequest 0 "NO_ACTION" 1 "UNLATCH" 2 "UNUSED" 3 "SNA";

VAL_ 1293 LFT_componentBranchOrigin 254 "LOCAL_BUILD" 255 "SNA";
VAL_ 1293 LFT_componentHardwareRevision 254 "LOCAL_BUILD" 255 "SNA";
VAL_ 1293 LFT_componentMajorVersion 254 "LOCAL_BUILD" 255 "SNA";
VAL_ 1293 LFT_componentMaturity 254 "LOCAL_BUILD" 255 "SNA";
VAL_ 1293 LFT_componentSvn 16777215 "SNA";
VAL_ 1293 LFT_platformType 254 "LOCAL_BUILD" 255 "SNA";

VAL_ 729 MCU_BCS2C_3RowFoldFlatRequest 0 "SNA" 1 "FAULT" 2 "HEADREST_ONLY" 3 "HEADREST_AND_FOLD_FLAT" 4 "IDLE";
VAL_ 729 MCU_BCS2C_comfortPitchRequest 0 "SNA" 1 "FORWARD" 2 "BACKWARD" 3 "IDLE";
VAL_ 729 MCU_BCS2C_comfortTrackRequest 0 "SNA" 1 "FORWARD" 2 "BACKWARD" 3 "IDLE";
VAL_ 729 MCU_BCS2C_easyEntryRequest 0 "SNA" 1 "GOTO_EASY_ENTRY_REQUEST" 2 "RETURN_FROM_EASY_ENTRY_REQUEST" 3 "IDLE";
VAL_ 729 MCU_BCS2C_installModeRequest 0 "OFF" 1 "ON" 3 "SNA";
VAL_ 729 MCU_BCS2C_positionRecall 0 "NO_ACTION_SNA" 1 "CARGO" 2 "DEFAULT_ALIGN" 3 "EXIT_CARGO";
VAL_ 729 MCU_BCS2C_requirePressAndHold 0 "OFF" 1 "ON" 3 "SNA";

VAL_ 712 MCU_BCS2L_3RowFoldFlatRequest 0 "SNA" 1 "FAULT" 2 "HEADREST_ONLY" 3 "HEADREST_AND_FOLD_FLAT" 4 "IDLE";
VAL_ 712 MCU_BCS2L_comfortPitchRequest 0 "SNA" 1 "FORWARD" 2 "BACKWARD" 3 "IDLE";
VAL_ 712 MCU_BCS2L_comfortTrackRequest 0 "SNA" 1 "FORWARD" 2 "BACKWARD" 3 "IDLE";
VAL_ 712 MCU_BCS2L_easyEntryRequest 0 "SNA" 1 "GOTO_EASY_ENTRY_REQUEST" 2 "RETURN_FROM_EASY_ENTRY_REQUEST" 3 "IDLE";
VAL_ 712 MCU_BCS2L_installModeRequest 0 "OFF" 1 "ON" 3 "SNA";
VAL_ 712 MCU_BCS2L_positionRecall 0 "NO_ACTION_SNA" 1 "CARGO" 2 "DEFAULT_ALIGN" 3 "EXIT_CARGO";
VAL_ 712 MCU_BCS2L_requirePressAndHold 0 "OFF" 1 "ON" 3 "SNA";

VAL_ 744 MCU_BCS2R_3RowFoldFlatRequest 0 "SNA" 1 "FAULT" 2 "HEADREST_ONLY" 3 "HEADREST_AND_FOLD_FLAT" 4 "IDLE";
VAL_ 744 MCU_BCS2R_comfortPitchRequest 0 "SNA" 1 "FORWARD" 2 "BACKWARD" 3 "IDLE";
VAL_ 744 MCU_BCS2R_comfortTrackRequest 0 "SNA" 1 "FORWARD" 2 "BACKWARD" 3 "IDLE";
VAL_ 744 MCU_BCS2R_easyEntryRequest 0 "SNA" 1 "GOTO_EASY_ENTRY_REQUEST" 2 "RETURN_FROM_EASY_ENTRY_REQUEST" 3 "IDLE";
VAL_ 744 MCU_BCS2R_installModeRequest 0 "OFF" 1 "ON" 3 "SNA";
VAL_ 744 MCU_BCS2R_positionRecall 0 "NO_ACTION_SNA" 1 "CARGO" 2 "DEFAULT_ALIGN" 3 "EXIT_CARGO";
VAL_ 744 MCU_BCS2R_requirePressAndHold 0 "OFF" 1 "ON" 3 "SNA";

VAL_ 415 AirTemp_Outsd_Disp 255 "SNA";
VAL_ 415 EngShutOffTm 4095 "SNA";
VAL_ 415 HiBm_Enbl 0 "DSABL" 1 "ENBL" 2 "NDEF2" 3 "SNA";
VAL_ 415 ODO 16777214 "Init" 16777215 "SNA";
VAL_ 415 PTS_Disp_Stat_IC 0 "OK" 1 "TIMEOUT" 2 "FATAL" 3 "SNA";
VAL_ 415 VehSpd_Disp 2047 "SNA";
VAL_ 415 Vprzr_DryVnTmr_Stat 0 "INACTV" 1 "ACTV" 2 "EXPIRED" 3 "SNA";

VAL_ 728 MCU_auxBlowerSpeed 1 "MANUAL_1" 2 "MANUAL_2" 3 "MANUAL_3" 4 "MANUAL_4" 5 "MANUAL_5" 6 "MANUAL_6" 7 "MANUAL_7" 12 "AUTO";
VAL_ 728 MCU_auxOnBtnState_Flag 0 "OFF" 1 "ON";
VAL_ 728 MCU_auxTempSetpoint_DegC 15 "LO" 28 "HI";

VAL_ 50 MCU_AconBtnState_Flag 0 "OFF" 1 "ON";
VAL_ 50 MCU_AconMnl_Flag 0 "AUTO" 1 "MANUAL";
VAL_ 50 MCU_AmbientRecircOff 0 "ACTIVE" 1 "OFF";
VAL_ 50 MCU_AutoBtnState_Flag 0 "MANUAL" 1 "AUTO";
VAL_ 50 MCU_BlowerMotorMnl_Flag 0 "AUTO" 1 "MANUAL";
VAL_ 50 MCU_DefogBtnState_Flag 0 "OFF" 1 "DEFOG" 2 "MAX_DEFOG" 3 "AUTO_DEFOG";
VAL_ 50 MCU_IntakeActMnl_Flag 0 "AUTO" 1 "MANUAL";
VAL_ 50 MCU_IntakeBtnState_Flag 0 "FRESH" 1 "FRESH_OFF_RECIRC" 2 "AUTO";
VAL_ 50 MCU_LeftTempSetpoint_DegC 15 "LO" 28 "HI";
VAL_ 50 MCU_ModeActMnlSet_Flag 1 "Panel" 2 "PanelAndFloor" 3 "Floor" 4 "FloorAndDef" 5 "Defrost" 6 "AllMode" 7 "PanelAndDef";
VAL_ 50 MCU_ModeActMnl_Flag 0 "AUTO" 1 "MANUAL";
VAL_ 50 MCU_OffBtnState_Flag 0 "ON" 1 "OFF";
VAL_ 50 MCU_RightTempSetpoint_DegC 15 "LO" 28 "HI";

VAL_ 552 MCU_airbagCutOffSwState 0 "PASSENGER_AIRBAG_ON" 1 "PASSENGER_AIRBAG_OFF" 2 "SNA" 3 "UNUSED";
VAL_ 552 MCU_warningIndicatorStatus 0 "WARNING_LAMP_OFF" 1 "WARNING_LAMP_ON" 2 "UNUSED" 3 "SNA";

VAL_ 101 MCU_alertId 0 "a000_unused" 2 "a002_HighCDTegraTemp" 4 "a004_TouchScreenError" 5 "a005_BrakeFluidLow" 6 "a006_displayFirmwareMismatch" 7 "a007_MapsMissing" 8 "a008_TPMS_globalHardWarn" 9 "a009_TPMS_globalOverPresWarn" 10 "a010_TPMS_globalSoftWarn" 11 "a011_TPMS_globalTireTempWarn" 12 "a012_TPMS_systemFault" 13 "a013_IncorrectMap" 14 "a014_parrotNotWorking" 15 "a015_parrotReflashed" 16 "a016_wifiAntennaDisconnected" 17 "a017_wakeupProblem" 18 "w018_sunroofSpeedWarning" 19 "a019_radioMainAntShort" 20 "a020_radioSubAntShort" 21 "a021_radioMainAntOpen" 22 "a022_radioSubAntOpen" 23 "a023_radioXMAntOpen" 24 "a024_radioDABAntOpen" 25 "a025_radioBatVTooHigh" 26 "a026_cidWatchdogReset" 27 "a027_dtcActive" 28 "a028_usb5vProblem" 29 "w029_remoteServiceAlert" 30 "w030_softPackConfigMismatch" 31 "w031_cidSquashfsError" 32 "w032_icSquashfsError" 33 "a033_dasAutosteerMIA" 34 "a034_apeFusesEtc" 35 "w035_USBError" 36 "a036_modemReset" 37 "a037_modemVMCrash" 38 "a038_modemMIA" 39 "a039_cellInternetCheckFailed" 40 "a040_wifiInternetCheckFailed" 41 "a041_wifiOnlineCheckFailed" 42 "a042_modemResetLoopDetected" 43 "a043_tractionControlOff" 44 "a044_cellModemRecoveryResets" 45 "w045_AudioDmesgDspException" 46 "w046_AudioWatchdogKernelError" 47 "w047_AudioWatchdogHfpError" 48 "w048_AudioWatchdogXrunStormError" 49 "w049_AudioWatchdogA2bI2cLockupError" 50 "w050_HomelinkTransmit" 51 "w051_AudioDmesgRtThrottling" 52 "w052_invalidMapDataOverride" 53 "w053_AudioDmesgXrun" 54 "w054_BackupCameraStreamError" 55 "w055_CellRoamingDisallowed" 8193 "u001_rearSeatbeltUnbuckled" 8194 "u002_washerFluidLow" 8195 "u003_HeadlightsOnDoorOpen" 8196 "u004_EASInJackMode" 8197 "u005_FrunkOpen" 8198 "u006_DriverDoorOpen" 8199 "u007_DoorOpen" 8200 "u008_DSTEntryLockDisabled" 8201 "u009_DAS_excessiveSpeeding" 8202 "u010_DAS_laneDepartureWarning" 8203 "u011_frunkOpenPopupClosed" 8204 "u012_rearSeatsUnlatchedPopupVisible" 8205 "u013_rearSeatsUnlatchedPopupClosed" 8206 "u014_TrunkOpen" 8207 "u015_notOnPrivateProperty" 8208 "u016_FalconDoorOpen" 8209 "u017_RegenChanged" 8210 "u018_ApTrialExpired";
